VERSION ""

NS_ :

BS_:

BU_: DMU_VEDS VIC Vehicle_Control_Unit
VAL_TABLE_ ThermMngtSysHeatrSts 3 "Not Available" 2 "Error" 1 "Heater On" 0 "Heater Off" ;
VAL_TABLE_ ThermMngtSysHVILSts 3 "Not Available" 2 "Error" 1 "HVIL Open" 0 "HVIL Closed" ;
VAL_TABLE_ ThermMngtSysCooltLvl 3 "Not Available" 2 "Error" 1 "Coolant Level is sufficient" 0 "Coolant Level is not sufficient" ;
VAL_TABLE_ ThermManagSysMode_table 15 "Not Available" 14 "Faulted" 13 "Reserved" 12 "Reserved" 11 "Reserved" 10 "Reserved" 9 "Reserved" 8 "Reserved" 7 "Reserved" 6 "Reserved" 5 "Reserved" 4 "Drying" 3 "Heating" 2 "Cooling" 1 "Circulating" 0 "Off" ;
VAL_TABLE_ HVESS_Total_Accumulated_Charge 1 "100 Ah/bit" 0 "Description for the value '0x0'" ;
VAL_TABLE_ HVESS_Total_Energy_Throughput 1 "100 Watt-hour per bit" 0 "Description for the value '0x0'" ;
VAL_TABLE_ HVESS_State_of_Health 0 "0.4% per bit" ;
VAL_TABLE_ HVBLSRCR 3 "11b = Don't care/take no action" 2 "10b = Reserved" 1 "01b = Connection Requested" 0 "00b = Connection not Requested" ;
VAL_TABLE_ HVBHSRCR 3 "11b = Don't care/take no action" 2 "10b = Reserved" 1 "01b = Connection Requested" 0 "00b = Connection not Requested" ;
VAL_TABLE_ HOC 3 "11b = Don't care/Take no action" 2 "10b = Error" 1 "01b = Consent given" 0 "00b = Consent revoked" ;
VAL_TABLE_ HEICC 3 "11b = Don't care/Take no action" 2 "10b = Reserved" 1 "01b = Enable charging" 0 "00b = Disable charging" ;
VAL_TABLE_ HCBC 3 "11b = Don't care/Take no action" 2 "10b = Reserved" 1 "01b = Cell Balancing requested" 0 "00b = Cell Balancing not req" ;
VAL_TABLE_ HVBPITC 3 "11b = Don't care/Take no action" 2 "10b = Inhibit Passive Iso Test" 1 "01b = Passive Iso Test req" 0 "00b = Passive Iso Test not req" ;
VAL_TABLE_ HVBAITC 3 "11b = Don't care/Take no action" 2 "10b = Inhibit Active Iso Test" 1 "01b = Active Iso Test request" 0 "00b = Active Iso Test not req" ;
VAL_TABLE_ HPDM 3 "11b = Don't care/Take no action" 2 "10b = Execute emergency power-dn" 1 "01b = Execute normal power-down" 0 "00b = Power-down not requested" ;
VAL_TABLE_ HVBCC 3 "11b = Don't care/Take no action" 2 "10b = Emgancy contactor cls req" 1 "01b = Close Contactor" 0 "00b = Open Contactor" ;
VAL_TABLE_ PropB_C0 15 "1111b = Info not available (default)" 11 "1011b = Granted but error" 10 "1010b = Granted" 2 "10b = Denied permanently" 1 "01b = Denied until restart" 0 "00b = Denied due to initialization" ;
VAL_TABLE_ PropB_C1_ErrLvl 7 "111b = Open contactors immediately and lock" 6 "110b = Open contactors immediately" 5 "101b = Open contactors normal" 4 "100b = Open contactors with time limit" 3 "11b = Open contactors with speed limit" 2 "10b = Limp Home with limited power" 1 "01b = Internal information" 0 "00b = System is ok" ;
VAL_TABLE_ PropB_C1_ThermEveStsCellT 3 "11b = info not available (default)" 2 "10b = crit. temp. warn. limit exceeded" 1 "01b = temp. warn. limit exceeded" 0 "00b = temperature ok" ;
VAL_TABLE_ S1_ES_HV_REQ 7 "111b = info not available (default)" 6 "110b = disconnect DC char" 5 "101b = connect für DC char" 4 "100b = prepair for DC char" 3 "11b = connect for AC char" 2 "10b = connect for driving" 1 "01b = emergency disconnect" 0 "00b = disconnect" ;
VAL_TABLE_ PropB_A1_LOCK_ACTIVATED 3 "11b = Not available" 2 "10b = Lock is activated by ESCU" 1 "01b = Lock is activated by HTCU" 0 "00b = Lock is inactive" ;
VAL_TABLE_ PropB_A1_STATE_ES_RELAY 7 "111b = Not available" 6 "110b = Error" 5 "101b = reserved" 4 "100b = Main Relays opening" 3 "11b = Main Relays closed" 2 "10b = All Es-Relays closed" 1 "01b = PreCharge-Relais closed" 0 "00b = All Es-Relays open" ;
VAL_TABLE_ Control_Byte_TP_CM 16 "RTS" 17 "CTS" 19 "EoMA" 20 "ERTS" 21 "ECTS" 22 "EDPO" 23 "EEoMACK" 24 "EAbort" 32 "BAM" 255 "Abort" ;

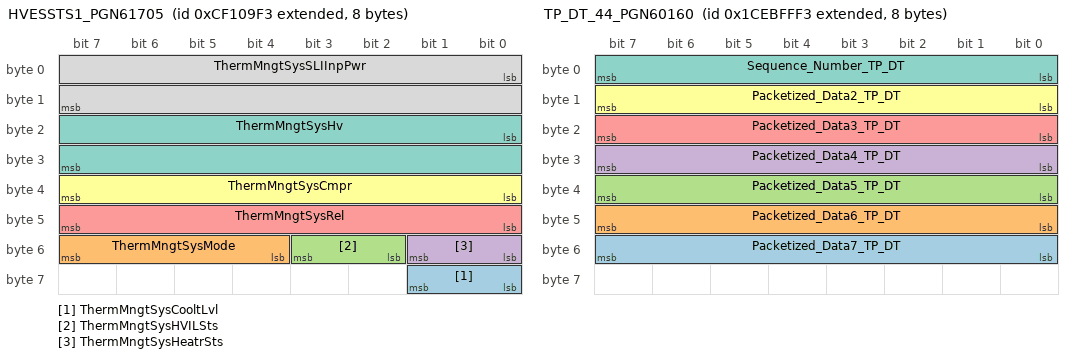
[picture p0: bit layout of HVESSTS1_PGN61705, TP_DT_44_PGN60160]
BO_ 2364606963 HVESSTS1_PGN61705: 8 VIC
 SG_ ThermMngtSysCooltLvl : 56|2@1+ (1,0) [0|3] "bit"  Vehicle_Control_Unit
 SG_ ThermMngtSysMode : 52|4@1+ (1,0) [0|15] "bit"  Vehicle_Control_Unit
 SG_ ThermMngtSysHVILSts : 50|2@1+ (1,0) [0|3] "bit"  Vehicle_Control_Unit
 SG_ ThermMngtSysHeatrSts : 48|2@1+ (1,0) [0|3] "bit"  Vehicle_Control_Unit
 SG_ ThermMngtSysRel : 40|8@1+ (0.4,0) [0|100] "%"  Vehicle_Control_Unit
 SG_ ThermMngtSysCmpr : 32|8@1+ (32,0) [0|8000] "rpm"  Vehicle_Control_Unit
 SG_ ThermMngtSysHv : 16|16@1+ (0.5,0) [0|32127.5] "W"  Vehicle_Control_Unit
 SG_ ThermMngtSysSLIInpPwr : 0|16@1+ (0.5,0) [0|32127.5] "W"  Vehicle_Control_Unit

BO_ 2632712179 TP_DT_44_PGN60160: 8 VIC
 SG_ Packetized_Data7_TP_DT : 48|8@1+ (1,0) [0|255] "" Vector__XXX
 SG_ Packetized_Data6_TP_DT : 40|8@1+ (1,0) [0|255] "" Vector__XXX
 SG_ Packetized_Data5_TP_DT : 32|8@1+ (1,0) [0|255] "" Vector__XXX
 SG_ Packetized_Data4_TP_DT : 24|8@1+ (1,0) [0|255] "" Vector__XXX
 SG_ Packetized_Data3_TP_DT : 16|8@1+ (1,0) [0|255] "" Vector__XXX
 SG_ Packetized_Data2_TP_DT : 8|8@1+ (1,0) [0|255] "" Vector__XXX
 SG_ Sequence_Number_TP_DT : 0|8@1+ (1,0) [0|255] "count" Vector__XXX

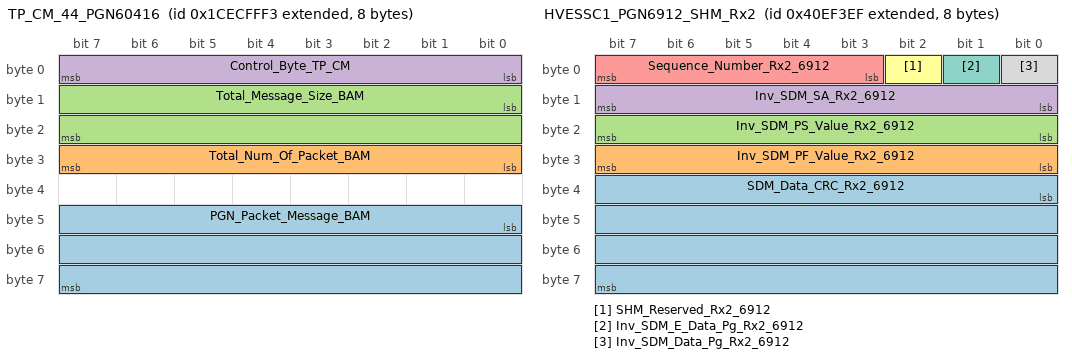
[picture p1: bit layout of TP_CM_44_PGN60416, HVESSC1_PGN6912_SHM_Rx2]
BO_ 2632777715 TP_CM_44_PGN60416: 8 VIC
 SG_ PGN_Packet_Message_BAM : 40|24@1+ (1,0) [0|16777215] "bit" Vector__XXX
 SG_ Total_Num_Of_Packet_BAM : 24|8@1+ (1,0) [0|255] "count" Vector__XXX
 SG_ Total_Message_Size_BAM : 8|16@1+ (1,0) [9|1785] "count" Vector__XXX
 SG_ Control_Byte_TP_CM : 0|8@1+ (1,0) [0|255] "bit" Vector__XXX

BO_ 2215572463 HVESSC1_PGN6912_SHM_Rx2: 8 DMU_VEDS
 SG_ SDM_Data_CRC_Rx2_6912 : 32|32@1+ (1,0) [0|4294967295] "bit"  VIC
 SG_ Inv_SDM_PF_Value_Rx2_6912 : 24|8@1+ (1,0) [0|256] "bit"  VIC
 SG_ Inv_SDM_PS_Value_Rx2_6912 : 16|8@1+ (1,0) [0|256] "bit"  VIC
 SG_ Inv_SDM_SA_Rx2_6912 : 8|8@1+ (1,0) [0|256] "bit"  VIC
 SG_ Sequence_Number_Rx2_6912 : 3|5@1+ (1,0) [0|32] "bit"  VIC
 SG_ SHM_Reserved_Rx2_6912 : 2|1@1+ (1,0) [0|1] "bit"  VIC
 SG_ Inv_SDM_E_Data_Pg_Rx2_6912 : 1|1@1+ (1,0) [0|1] "bit"  VIC
 SG_ Inv_SDM_Data_Pg_Rx2_6912 : 0|1@1+ (1,0) [0|1] "bit"  VIC

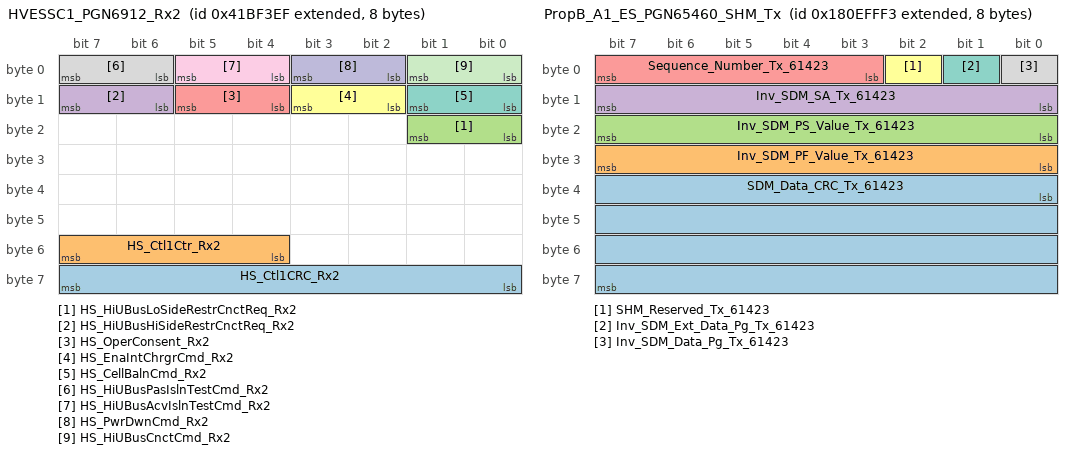
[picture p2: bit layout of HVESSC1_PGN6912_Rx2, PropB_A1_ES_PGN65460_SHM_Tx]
BO_ 2216424431 HVESSC1_PGN6912_Rx2: 8 DMU_VEDS
 SG_ HS_Ctl1CRC_Rx2 : 56|8@1+ (1,0) [0|255] "count"  VIC
 SG_ HS_Ctl1Ctr_Rx2 : 52|4@1+ (1,0) [0|15] "bit"  VIC
 SG_ HS_HiUBusLoSideRestrCnctReq_Rx2 : 16|2@1+ (1,0) [0|3] "bit"  VIC
 SG_ HS_HiUBusHiSideRestrCnctReq_Rx2 : 14|2@1+ (1,0) [0|3] "bit"  VIC
 SG_ HS_OperConsent_Rx2 : 12|2@1+ (1,0) [0|3] "bit"  VIC
 SG_ HS_EnaIntChrgrCmd_Rx2 : 10|2@1+ (1,0) [0|3] "bit"  VIC
 SG_ HS_CellBalnCmd_Rx2 : 8|2@1+ (1,0) [0|3] "bit"  VIC
 SG_ HS_HiUBusPasIslnTestCmd_Rx2 : 6|2@1+ (1,0) [0|3] "bit"  VIC
 SG_ HS_HiUBusAcvIslnTestCmd_Rx2 : 4|2@1+ (1,0) [0|3] "bit"  VIC
 SG_ HS_PwrDwnCmd_Rx2 : 2|2@1+ (1,0) [0|3] "bit"  VIC
 SG_ HS_HiUBusCnctCmd_Rx2 : 0|2@1+ (1,0) [0|3] "bit"  VIC

BO_ 2162881313 RQST_ES_PGN59904_Rx1: 3 Vehicle_Control_Unit
 SG_ RQST_Rx1 : 0|24@1+ (1,0) [0|0] ""  VIC

BO_ 2551119859 PropB_A1_ES_PGN65460_SHM_Tx: 8 VIC
 SG_ SDM_Data_CRC_Tx_61423 : 32|32@1+ (1,0) [0|4294967295] "bit"  DMU_VEDS
 SG_ Inv_SDM_PF_Value_Tx_61423 : 24|8@1+ (1,0) [0|256] "bit"  DMU_VEDS
 SG_ Inv_SDM_PS_Value_Tx_61423 : 16|8@1+ (1,0) [0|256] "bit"  DMU_VEDS
 SG_ Inv_SDM_SA_Tx_61423 : 8|8@1+ (1,0) [0|256] "bit"  DMU_VEDS
 SG_ Sequence_Number_Tx_61423 : 3|5@1+ (1,0) [0|32] "bit"  DMU_VEDS
 SG_ SHM_Reserved_Tx_61423 : 2|1@1+ (1,0) [0|1] "bit"  DMU_VEDS
 SG_ Inv_SDM_Ext_Data_Pg_Tx_61423 : 1|1@1+ (1,0) [0|1] "bit"  DMU_VEDS
 SG_ Inv_SDM_Data_Pg_Tx_61423 : 0|1@1+ (1,0) [0|1] "bit"  DMU_VEDS

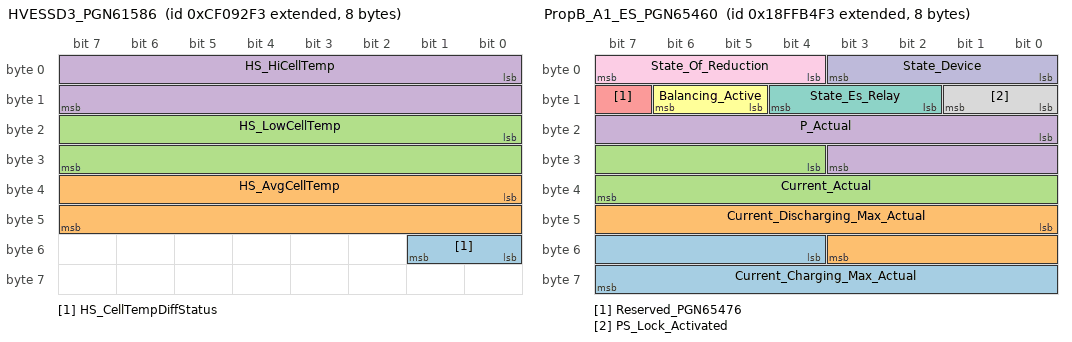
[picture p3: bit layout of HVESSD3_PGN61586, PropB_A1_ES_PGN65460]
BO_ 2364576499 HVESSD3_PGN61586: 8 VIC
 SG_ HS_CellTempDiffStatus : 48|2@1+ (1,0) [0|3] "bit"  Vehicle_Control_Unit
 SG_ HS_AvgCellTemp : 32|16@1+ (0.03125,-273) [-273|1734.96875] "°C"  Vehicle_Control_Unit
 SG_ HS_LowCellTemp : 16|16@1+ (0.03125,-273) [-273|1734.96875] "°C"  Vehicle_Control_Unit
 SG_ HS_HiCellTemp : 0|16@1+ (0.03125,-273) [-273|1734.96875] "°C"  Vehicle_Control_Unit

BO_ 2566894835 PropB_A1_ES_PGN65460: 8 VIC
 SG_ Current_Charging_Max_Actual : 52|12@1+ (1,-2000) [-2000|2015] "A"  DMU_VEDS
 SG_ Current_Discharging_Max_Actual : 40|12@1+ (1,-2000) [-2000|2015] "A"  DMU_VEDS
 SG_ Current_Actual : 28|12@1+ (1,-2000) [-2000|2015] "A"  DMU_VEDS
 SG_ P_Actual : 16|12@1+ (250,-500000) [-500000|503750] "W"  DMU_VEDS
 SG_ Reserved_PGN65476 : 15|1@1+ (1,0) [0|1] "bit"  DMU_VEDS
 SG_ Balancing_Active : 13|2@1+ (1,0) [0|3] "bit"  DMU_VEDS
 SG_ State_Es_Relay : 10|3@1+ (1,0) [0|7] "bit"  DMU_VEDS
 SG_ PS_Lock_Activated : 8|2@1+ (1,0) [0|3] "bit"  DMU_VEDS
 SG_ State_Of_Reduction : 4|4@1+ (1,0) [0|15] ""  DMU_VEDS
 SG_ State_Device : 0|4@1+ (1,0) [0|15] ""  DMU_VEDS

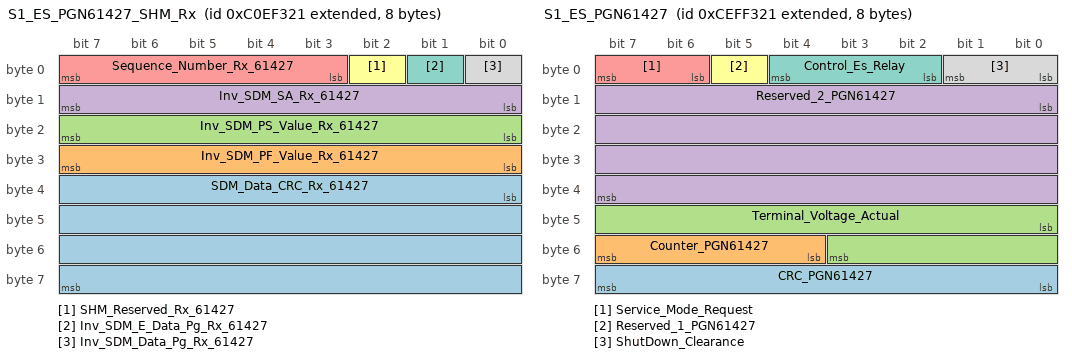
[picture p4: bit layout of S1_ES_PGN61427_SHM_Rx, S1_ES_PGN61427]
BO_ 2349789985 S1_ES_PGN61427_SHM_Rx: 8 Vehicle_Control_Unit
 SG_ SDM_Data_CRC_Rx_61427 : 32|32@1+ (1,0) [0|4294967295] "bit"  VIC
 SG_ Inv_SDM_PF_Value_Rx_61427 : 24|8@1+ (1,0) [0|256] "bit"  VIC
 SG_ Inv_SDM_PS_Value_Rx_61427 : 16|8@1+ (1,0) [0|256] "bit"  VIC
 SG_ Inv_SDM_SA_Rx_61427 : 8|8@1+ (1,0) [0|256] "bit"  VIC
 SG_ Sequence_Number_Rx_61427 : 3|5@1+ (1,0) [0|32] "bit"  VIC
 SG_ SHM_Reserved_Rx_61427 : 2|1@1+ (1,0) [0|1] "bit"  VIC
 SG_ Inv_SDM_E_Data_Pg_Rx_61427 : 1|1@1+ (1,0) [0|1] "bit"  VIC
 SG_ Inv_SDM_Data_Pg_Rx_61427 : 0|1@1+ (1,0) [0|1] "bit"  VIC

BO_ 2364535585 S1_ES_PGN61427: 8 Vehicle_Control_Unit
 SG_ CRC_PGN61427 : 56|8@1+ (1,0) [0|255] "unit"  VIC
 SG_ Counter_PGN61427 : 52|4@1+ (1,0) [0|15] "unit"  VIC
 SG_ Terminal_Voltage_Actual : 40|12@1+ (0.5,0) [0|2007.5] "V"  VIC
 SG_ Reserved_2_PGN61427 : 8|32@1+ (1,0) [0|4294967295] "unit"  VIC
 SG_ Service_Mode_Request : 6|2@1+ (1,0) [0|3] "bit"  VIC
 SG_ Reserved_1_PGN61427 : 5|1@1+ (1,0) [0|1] "unit"  VIC
 SG_ Control_Es_Relay : 2|3@1+ (1,0) [0|7] "bit"  VIC
 SG_ ShutDown_Clearance : 0|2@1+ (1,0) [0|3] "bit"  VIC

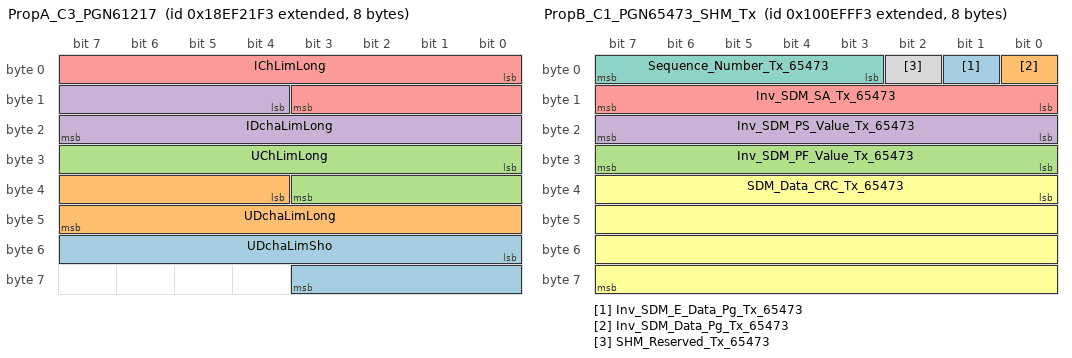
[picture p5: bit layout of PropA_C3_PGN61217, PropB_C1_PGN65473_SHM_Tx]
BO_ 2565808627 PropA_C3_PGN61217: 8 VIC
 SG_ UDchaLimSho : 48|12@1+ (0.25,0) [0|1023.75] "V" Vector__XXX
 SG_ UDchaLimLong : 36|12@1+ (0.25,0) [0|1023.75] "V" Vector__XXX
 SG_ UChLimLong : 24|12@1+ (0.25,0) [0|1023.75] "V" Vector__XXX
 SG_ IDchaLimLong : 12|12@1+ (0.5,0) [0|1023.75] "A" Vector__XXX
 SG_ IChLimLong : 0|12@1+ (0.5,0) [0|1023.75] "A"  Vehicle_Control_Unit

BO_ 2162827763 RQST_ES_PGN59904_Tx: 3 VIC
 SG_ RQST_Tx : 0|24@1+ (1,0) [0|16777215] "unit"  Vehicle_Control_Unit

BO_ 2566834931 DM01_44: 42 VIC
 SG_ Flash_Mil : 14|2@1+ (1,0) [0|3] "" Vector__XXX
 SG_ Flash_Rsl : 12|2@1+ (1,0) [0|3] "" Vector__XXX
 SG_ Flash_Awl : 10|2@1+ (1,0) [0|3] "" Vector__XXX
 SG_ Flash_ProtLamp : 8|2@1+ (1,0) [0|3] "" Vector__XXX
 SG_ ProtLamp : 0|2@1+ (1,0) [0|3] "" Vector__XXX
 SG_ Awl : 2|2@1+ (1,0) [0|3] "" Vector__XXX
 SG_ Rsl : 4|2@1+ (1,0) [0|3] "" Vector__XXX
 SG_ Mil : 6|2@1+ (1,0) [0|3] "" Vector__XXX
 SG_ Spn01 : 16|16@1+ (1,0) [0|65535] "binary" Vector__XXX
 SG_ SpnHigh01 : 37|3@1+ (1,0) [0|7] "binary" Vector__XXX
 SG_ Fmi01 : 32|5@1+ (1,0) [0|31] "binary" Vector__XXX
 SG_ Oc01 : 40|7@1+ (1,0) [0|127] "binary" Vector__XXX
 SG_ SpnCm01 : 47|1@1+ (1,0) [0|1] "" Vector__XXX
 SG_ Spn02 : 48|16@1+ (1,0) [0|65535] "binary" Vector__XXX
 SG_ SpnHigh02 : 69|3@1+ (1,0) [0|7] "binary" Vector__XXX
 SG_ Fmi02 : 64|5@1+ (1,0) [0|31] "binary" Vector__XXX
 SG_ Oc02 : 72|7@1+ (1,0) [0|127] "binary" Vector__XXX
 SG_ SpnCm02 : 79|1@1+ (1,0) [0|1] "" Vector__XXX
 SG_ Spn03 : 80|16@1+ (1,0) [0|65535] "binary" Vector__XXX
 SG_ SpnHigh03 : 101|3@1+ (1,0) [0|7] "binary" Vector__XXX
 SG_ Fmi03 : 96|5@1+ (1,0) [0|31] "binary" Vector__XXX
 SG_ Oc03 : 104|7@1+ (1,0) [0|127] "binary" Vector__XXX
 SG_ SpnCm03 : 111|1@1+ (1,0) [0|1] "" Vector__XXX
 SG_ Spn04 : 112|16@1+ (1,0) [0|65535] "binary" Vector__XXX
 SG_ SpnHigh04 : 133|3@1+ (1,0) [0|7] "binary" Vector__XXX
 SG_ Fmi04 : 128|5@1+ (1,0) [0|31] "binary" Vector__XXX
 SG_ Oc04 : 136|7@1+ (1,0) [0|127] "binary" Vector__XXX
 SG_ SpnCm04 : 143|1@1+ (1,0) [0|1] "" Vector__XXX
 SG_ Spn05 : 144|16@1+ (1,0) [0|65535] "binary" Vector__XXX
 SG_ SpnHigh05 : 165|3@1+ (1,0) [0|7] "binary" Vector__XXX
 SG_ Fmi05 : 160|5@1+ (1,0) [0|31] "binary" Vector__XXX
 SG_ Oc05 : 168|7@1+ (1,0) [0|127] "binary" Vector__XXX
 SG_ SpnCm05 : 175|1@1+ (1,0) [0|1] "" Vector__XXX
 SG_ Spn06 : 176|16@1+ (1,0) [0|65535] "binary" Vector__XXX
 SG_ SpnHigh06 : 197|3@1+ (1,0) [0|7] "binary" Vector__XXX
 SG_ Fmi06 : 192|5@1+ (1,0) [0|31] "binary" Vector__XXX
 SG_ Oc06 : 200|7@1+ (1,0) [0|127] "binary" Vector__XXX
 SG_ SpnCm06 : 207|1@1+ (1,0) [0|1] "" Vector__XXX
 SG_ Spn07 : 208|16@1+ (1,0) [0|65535] "binary" Vector__XXX
 SG_ SpnHigh07 : 229|3@1+ (1,0) [0|7] "binary" Vector__XXX
 SG_ Fmi07 : 224|5@1+ (1,0) [0|31] "binary" Vector__XXX
 SG_ Oc07 : 232|7@1+ (1,0) [0|127] "binary" Vector__XXX
 SG_ SpnCm07 : 239|1@1+ (1,0) [0|1] "" Vector__XXX
 SG_ Spn08 : 240|16@1+ (1,0) [0|65535] "binary" Vector__XXX
 SG_ SpnHigh08 : 261|3@1+ (1,0) [0|7] "binary" Vector__XXX
 SG_ Fmi08 : 256|5@1+ (1,0) [0|31] "binary" Vector__XXX
 SG_ Oc08 : 264|7@1+ (1,0) [0|127] "binary" Vector__XXX
 SG_ SpnCm08 : 271|1@1+ (1,0) [0|1] "" Vector__XXX
 SG_ Spn09 : 272|16@1+ (1,0) [0|65535] "binary" Vector__XXX
 SG_ SpnHigh09 : 293|3@1+ (1,0) [0|7] "binary" Vector__XXX
 SG_ Fmi09 : 288|5@1+ (1,0) [0|31] "binary" Vector__XXX
 SG_ Oc09 : 296|7@1+ (1,0) [0|127] "binary" Vector__XXX
 SG_ SpnCm09 : 303|1@1+ (1,0) [0|1] "" Vector__XXX
 SG_ Spn10 : 304|16@1+ (1,0) [0|65535] "binary" Vector__XXX
 SG_ SpnHigh10 : 325|3@1+ (1,0) [0|7] "binary" Vector__XXX
 SG_ Fmi10 : 320|5@1+ (1,0) [0|31] "binary" Vector__XXX
 SG_ Oc10 : 328|7@1+ (1,0) [0|127] "binary" Vector__XXX
 SG_ SpnCm10 : 335|1@1+ (1,0) [0|1] "" Vector__XXX

BO_ 2416902131 PropB_C1_PGN65473_SHM_Tx: 8 VIC
 SG_ Inv_SDM_E_Data_Pg_Tx_65473 : 1|1@1+ (1,0) [0|1] "bit"  Vehicle_Control_Unit
 SG_ Inv_SDM_Data_Pg_Tx_65473 : 0|1@1+ (1,0) [0|1] "bit"  Vehicle_Control_Unit
 SG_ Inv_SDM_PF_Value_Tx_65473 : 24|8@1+ (1,0) [0|256] "bit"  Vehicle_Control_Unit
 SG_ Inv_SDM_PS_Value_Tx_65473 : 16|8@1+ (1,0) [0|256] "bit"  Vehicle_Control_Unit
 SG_ Inv_SDM_SA_Tx_65473 : 8|8@1+ (1,0) [0|256] "bit"  Vehicle_Control_Unit
 SG_ SDM_Data_CRC_Tx_65473 : 32|32@1+ (1,0) [0|4294967295] "bit"  Vehicle_Control_Unit
 SG_ Sequence_Number_Tx_65473 : 3|5@1+ (1,0) [0|32] "bit"  Vehicle_Control_Unit
 SG_ SHM_Reserved_Tx_65473 : 2|1@1+ (1,0) [0|1] "bit"  Vehicle_Control_Unit

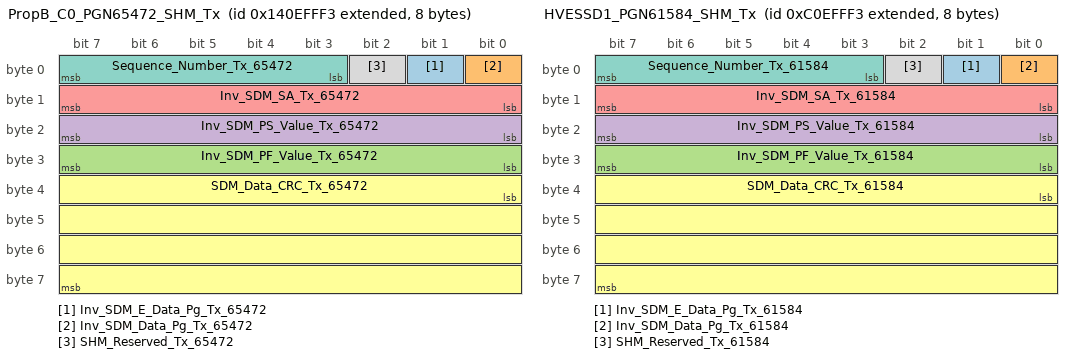
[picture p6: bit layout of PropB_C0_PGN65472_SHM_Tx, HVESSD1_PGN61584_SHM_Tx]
BO_ 2484010995 PropB_C0_PGN65472_SHM_Tx: 8 VIC
 SG_ Inv_SDM_E_Data_Pg_Tx_65472 : 1|1@1+ (1,0) [0|1] "bit"  Vehicle_Control_Unit
 SG_ Inv_SDM_Data_Pg_Tx_65472 : 0|1@1+ (1,0) [0|1] "bit"  Vehicle_Control_Unit
 SG_ Inv_SDM_PF_Value_Tx_65472 : 24|8@1+ (1,0) [0|256] "bit"  Vehicle_Control_Unit
 SG_ Inv_SDM_PS_Value_Tx_65472 : 16|8@1+ (1,0) [0|256] "bit"  Vehicle_Control_Unit
 SG_ Inv_SDM_SA_Tx_65472 : 8|8@1+ (1,0) [0|256] "bit"  Vehicle_Control_Unit
 SG_ SDM_Data_CRC_Tx_65472 : 32|32@1+ (1,0) [0|4294967295] "bit"  Vehicle_Control_Unit
 SG_ Sequence_Number_Tx_65472 : 3|5@1+ (1,0) [0|32] "bit"  Vehicle_Control_Unit
 SG_ SHM_Reserved_Tx_65472 : 2|1@1+ (1,0) [0|1] "bit"  Vehicle_Control_Unit

BO_ 2349793267 HVESSD1_PGN61584_SHM_Tx: 8 VIC
 SG_ Inv_SDM_E_Data_Pg_Tx_61584 : 1|1@1+ (1,0) [0|1] "bit"  Vehicle_Control_Unit
 SG_ Inv_SDM_Data_Pg_Tx_61584 : 0|1@1+ (1,0) [0|1] "bit"  Vehicle_Control_Unit
 SG_ Inv_SDM_PF_Value_Tx_61584 : 24|8@1+ (1,0) [0|256] "bit"  Vehicle_Control_Unit
 SG_ Inv_SDM_PS_Value_Tx_61584 : 16|8@1+ (1,0) [0|256] "bit"  Vehicle_Control_Unit
 SG_ Inv_SDM_SA_Tx_61584 : 8|8@1+ (1,0) [0|256] "bit"  Vehicle_Control_Unit
 SG_ SDM_Data_CRC_Tx_61584 : 32|32@1+ (1,0) [0|4294967295] "bit"  Vehicle_Control_Unit
 SG_ Sequence_Number_Tx_61584 : 3|5@1+ (1,0) [0|32] "bit"  Vehicle_Control_Unit
 SG_ SHM_Reserved_Tx_61584 : 2|1@1+ (1,0) [0|1] "bit"  Vehicle_Control_Unit

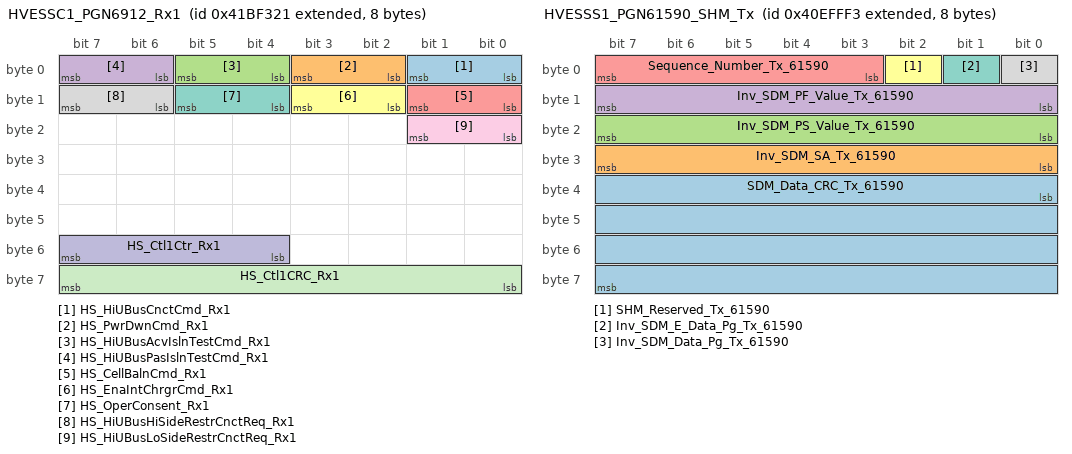
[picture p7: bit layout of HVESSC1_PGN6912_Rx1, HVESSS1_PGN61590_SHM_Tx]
BO_ 2216424225 HVESSC1_PGN6912_Rx1: 8 Vehicle_Control_Unit
 SG_ HS_HiUBusCnctCmd_Rx1 : 0|2@1+ (1,0) [0|3] "bit"  VIC
 SG_ HS_PwrDwnCmd_Rx1 : 2|2@1+ (1,0) [0|3] "bit"  VIC
 SG_ HS_HiUBusAcvIslnTestCmd_Rx1 : 4|2@1+ (1,0) [0|3] "bit"  VIC
 SG_ HS_HiUBusPasIslnTestCmd_Rx1 : 6|2@1+ (1,0) [0|3] "bit"  VIC
 SG_ HS_CellBalnCmd_Rx1 : 8|2@1+ (1,0) [0|3] "bit"  VIC
 SG_ HS_EnaIntChrgrCmd_Rx1 : 10|2@1+ (1,0) [0|3] "bit"  VIC
 SG_ HS_OperConsent_Rx1 : 12|2@1+ (1,0) [0|3] "bit"  VIC
 SG_ HS_HiUBusHiSideRestrCnctReq_Rx1 : 14|2@1+ (1,0) [0|3] "bit"  VIC
 SG_ HS_HiUBusLoSideRestrCnctReq_Rx1 : 16|2@1+ (1,0) [0|3] "bit"  VIC
 SG_ HS_Ctl1Ctr_Rx1 : 52|4@1+ (1,0) [0|15] "bit"  VIC
 SG_ HS_Ctl1CRC_Rx1 : 56|8@1+ (1,0) [0|255] "count"  VIC

BO_ 2215575539 HVESSS1_PGN61590_SHM_Tx: 8 VIC
 SG_ SDM_Data_CRC_Tx_61590 : 32|32@1+ (1,0) [0|4294967295] "bit"  Vehicle_Control_Unit
 SG_ Inv_SDM_SA_Tx_61590 : 24|8@1+ (1,0) [0|256] "bit"  Vehicle_Control_Unit
 SG_ Inv_SDM_PS_Value_Tx_61590 : 16|8@1+ (1,0) [0|256] "bit"  Vehicle_Control_Unit
 SG_ Inv_SDM_PF_Value_Tx_61590 : 8|8@1+ (1,0) [0|256] "bit"  Vehicle_Control_Unit
 SG_ Sequence_Number_Tx_61590 : 3|5@1+ (1,0) [0|32] "bit"  Vehicle_Control_Unit
 SG_ SHM_Reserved_Tx_61590 : 2|1@1+ (1,0) [0|1] "bit"  Vehicle_Control_Unit
 SG_ Inv_SDM_E_Data_Pg_Tx_61590 : 1|1@1+ (1,0) [0|1] "bit"  Vehicle_Control_Unit
 SG_ Inv_SDM_Data_Pg_Tx_61590 : 0|1@1+ (1,0) [0|1] "bit"  Vehicle_Control_Unit

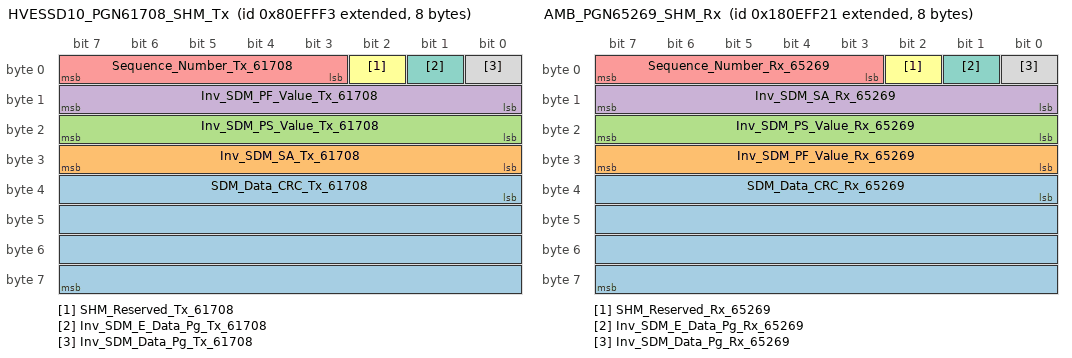
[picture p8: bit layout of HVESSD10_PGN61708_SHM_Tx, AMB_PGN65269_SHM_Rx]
BO_ 2282684403 HVESSD10_PGN61708_SHM_Tx: 8 VIC
 SG_ SDM_Data_CRC_Tx_61708 : 32|32@1+ (1,0) [0|4294967295] "bit"  Vehicle_Control_Unit
 SG_ Inv_SDM_SA_Tx_61708 : 24|8@1+ (1,0) [0|256] "bit"  Vehicle_Control_Unit
 SG_ Inv_SDM_PS_Value_Tx_61708 : 16|8@1+ (1,0) [0|256] "bit"  Vehicle_Control_Unit
 SG_ Inv_SDM_PF_Value_Tx_61708 : 8|8@1+ (1,0) [0|256] "bit"  Vehicle_Control_Unit
 SG_ Sequence_Number_Tx_61708 : 3|5@1+ (1,0) [0|32] "bit"  Vehicle_Control_Unit
 SG_ SHM_Reserved_Tx_61708 : 2|1@1+ (1,0) [0|1] "bit"  Vehicle_Control_Unit
 SG_ Inv_SDM_E_Data_Pg_Tx_61708 : 1|1@1+ (1,0) [0|1] "bit"  Vehicle_Control_Unit
 SG_ Inv_SDM_Data_Pg_Tx_61708 : 0|1@1+ (1,0) [0|1] "bit"  Vehicle_Control_Unit

BO_ 2551119649 AMB_PGN65269_SHM_Rx: 8 Vehicle_Control_Unit
 SG_ SDM_Data_CRC_Rx_65269 : 32|32@1+ (1,0) [0|4294967295] "bit"  VIC
 SG_ Inv_SDM_PF_Value_Rx_65269 : 24|8@1+ (1,0) [0|256] "bit"  VIC
 SG_ Inv_SDM_PS_Value_Rx_65269 : 16|8@1+ (1,0) [0|256] "bit"  VIC
 SG_ Inv_SDM_SA_Rx_65269 : 8|8@1+ (1,0) [0|256] "bit"  VIC
 SG_ Sequence_Number_Rx_65269 : 3|5@1+ (1,0) [0|32] "bit"  VIC
 SG_ SHM_Reserved_Rx_65269 : 2|1@1+ (1,0) [0|1] "bit"  VIC
 SG_ Inv_SDM_E_Data_Pg_Rx_65269 : 1|1@1+ (1,0) [0|1] "bit"  VIC
 SG_ Inv_SDM_Data_Pg_Rx_65269 : 0|1@1+ (1,0) [0|1] "bit"  VIC

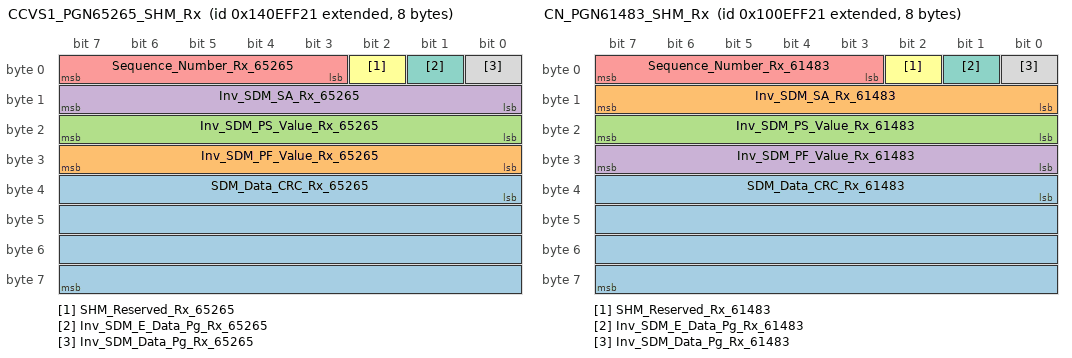
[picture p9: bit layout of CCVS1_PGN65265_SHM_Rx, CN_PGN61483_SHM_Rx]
BO_ 2484010785 CCVS1_PGN65265_SHM_Rx: 8 Vehicle_Control_Unit
 SG_ SDM_Data_CRC_Rx_65265 : 32|32@1+ (1,0) [0|4294967295] "bit"  VIC
 SG_ Inv_SDM_PF_Value_Rx_65265 : 24|8@1+ (1,0) [0|256] "bit"  VIC
 SG_ Inv_SDM_PS_Value_Rx_65265 : 16|8@1+ (1,0) [0|256] "bit"  VIC
 SG_ Inv_SDM_SA_Rx_65265 : 8|8@1+ (1,0) [0|256] "bit"  VIC
 SG_ Sequence_Number_Rx_65265 : 3|5@1+ (1,0) [0|32] "bit"  VIC
 SG_ SHM_Reserved_Rx_65265 : 2|1@1+ (1,0) [0|1] "bit"  VIC
 SG_ Inv_SDM_E_Data_Pg_Rx_65265 : 1|1@1+ (1,0) [0|1] "bit"  VIC
 SG_ Inv_SDM_Data_Pg_Rx_65265 : 0|1@1+ (1,0) [0|1] "bit"  VIC

BO_ 2416901921 CN_PGN61483_SHM_Rx: 8 Vehicle_Control_Unit
 SG_ SDM_Data_CRC_Rx_61483 : 32|32@1+ (1,0) [0|4294967295] "bit"  VIC
 SG_ Inv_SDM_SA_Rx_61483 : 8|8@1+ (1,0) [0|256] "bit"  VIC
 SG_ Inv_SDM_PS_Value_Rx_61483 : 16|8@1+ (1,0) [0|256] "bit"  VIC
 SG_ Inv_SDM_PF_Value_Rx_61483 : 24|8@1+ (1,0) [0|256] "bit"  VIC
 SG_ Sequence_Number_Rx_61483 : 3|5@1+ (1,0) [0|32] "bit"  VIC
 SG_ SHM_Reserved_Rx_61483 : 2|1@1+ (1,0) [0|1] "bit"  VIC
 SG_ Inv_SDM_E_Data_Pg_Rx_61483 : 1|1@1+ (1,0) [0|1] "bit"  VIC
 SG_ Inv_SDM_Data_Pg_Rx_61483 : 0|1@1+ (1,0) [0|1] "bit"  VIC

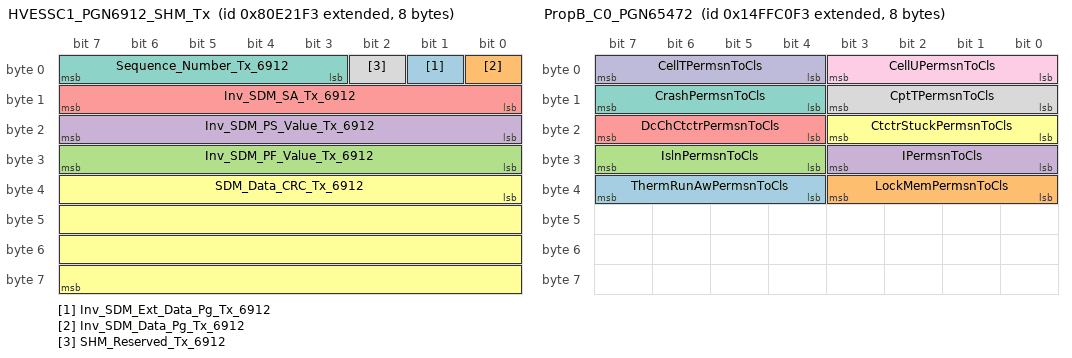
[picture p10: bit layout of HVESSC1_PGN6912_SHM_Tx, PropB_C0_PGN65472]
BO_ 2282627571 HVESSC1_PGN6912_SHM_Tx: 8 VIC
 SG_ Inv_SDM_Ext_Data_Pg_Tx_6912 : 1|1@1+ (1,0) [0|1] "bit"  Vehicle_Control_Unit
 SG_ Inv_SDM_Data_Pg_Tx_6912 : 0|1@1+ (1,0) [0|1] "bit"  Vehicle_Control_Unit
 SG_ Inv_SDM_PF_Value_Tx_6912 : 24|8@1+ (1,0) [0|256] "bit"  Vehicle_Control_Unit
 SG_ Inv_SDM_PS_Value_Tx_6912 : 16|8@1+ (1,0) [0|256] "bit"  Vehicle_Control_Unit
 SG_ Inv_SDM_SA_Tx_6912 : 8|8@1+ (1,0) [0|256] "bit"  Vehicle_Control_Unit
 SG_ SDM_Data_CRC_Tx_6912 : 32|32@1+ (1,0) [0|4294967295] "bit"  Vehicle_Control_Unit
 SG_ Sequence_Number_Tx_6912 : 3|5@1+ (1,0) [0|32] "bit"  Vehicle_Control_Unit
 SG_ SHM_Reserved_Tx_6912 : 2|1@1+ (1,0) [0|1] "bit"  Vehicle_Control_Unit

BO_ 2499789043 PropB_C0_PGN65472: 8 VIC
 SG_ ThermRunAwPermsnToCls : 36|4@1+ (1,0) [0|15] ""  Vehicle_Control_Unit
 SG_ LockMemPermsnToCls : 32|4@1+ (1,0) [0|15] ""  Vehicle_Control_Unit
 SG_ IslnPermsnToCls : 28|4@1+ (1,0) [0|15] ""  Vehicle_Control_Unit
 SG_ IPermsnToCls : 24|4@1+ (1,0) [0|15] ""  Vehicle_Control_Unit
 SG_ DcChCtctrPermsnToCls : 20|4@1+ (1,0) [0|15] ""  Vehicle_Control_Unit
 SG_ CtctrStuckPermsnToCls : 16|4@1+ (1,0) [0|15] ""  Vehicle_Control_Unit
 SG_ CrashPermsnToCls : 12|4@1+ (1,0) [0|15] ""  Vehicle_Control_Unit
 SG_ CptTPermsnToCls : 8|4@1+ (1,0) [0|15] ""  Vehicle_Control_Unit
 SG_ CellUPermsnToCls : 0|4@1+ (1,0) [0|15] ""  Vehicle_Control_Unit
 SG_ CellTPermsnToCls : 4|4@1+ (1,0) [0|15] ""  Vehicle_Control_Unit

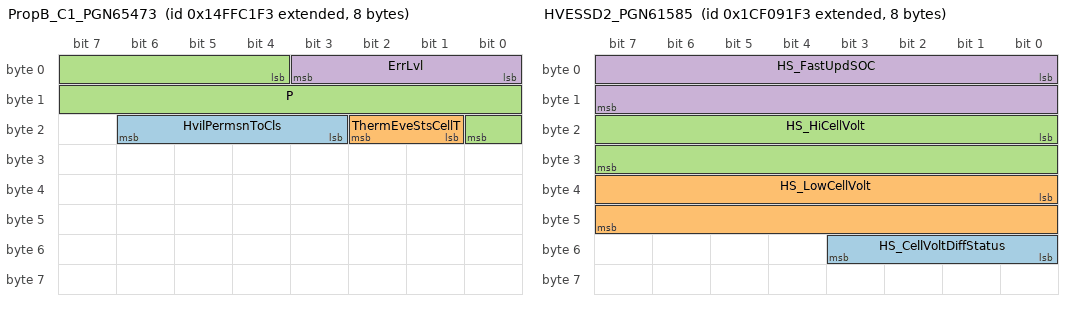
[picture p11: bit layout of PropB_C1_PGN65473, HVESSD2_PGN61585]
BO_ 2499789299 PropB_C1_PGN65473: 8 VIC
 SG_ HvilPermsnToCls : 19|4@1+ (1,0) [0|15] "unit"  Vehicle_Control_Unit
 SG_ ThermEveStsCellT : 17|2@1+ (1,0) [0|3] "unit"  Vehicle_Control_Unit
 SG_ P : 4|13@1+ (0.125,0) [0|1023.875] "kW"  Vehicle_Control_Unit
 SG_ ErrLvl : 0|4@1+ (1,0) [0|7] "unit"  Vehicle_Control_Unit

BO_ 2633011699 HVESSD2_PGN61585: 8 VIC
 SG_ HS_CellVoltDiffStatus : 48|4@1+ (1,0) [0|15] "V"  Vehicle_Control_Unit
 SG_ HS_LowCellVolt : 32|16@1+ (0.001,0) [0|64.255] "V"  Vehicle_Control_Unit
 SG_ HS_HiCellVolt : 16|16@1+ (0.0015625,0) [0|64.255] "V"  Vehicle_Control_Unit
 SG_ HS_FastUpdSOC : 0|16@1+ (0.0015625,0) [0|100.3984375] "%"  Vehicle_Control_Unit

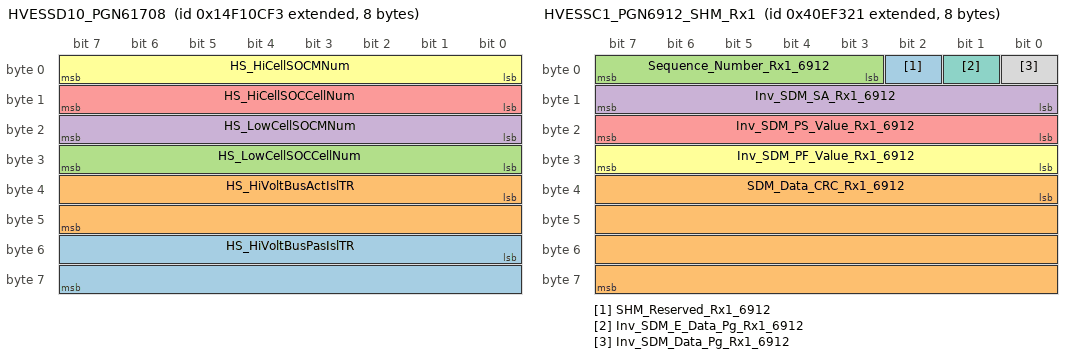
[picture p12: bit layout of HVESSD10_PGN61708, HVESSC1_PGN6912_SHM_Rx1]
BO_ 2498825459 HVESSD10_PGN61708: 8 VIC
 SG_ HS_HiVoltBusPasIslTR : 48|16@1+ (0.1,0) [0|6425.5] "ohm/V"  Vehicle_Control_Unit
 SG_ HS_HiVoltBusActIslTR : 32|16@1+ (0.1,0) [0|6425.5] "ohm/V"  Vehicle_Control_Unit
 SG_ HS_LowCellSOCCellNum : 24|8@1+ (1,0) [0|250] "count"  Vehicle_Control_Unit
 SG_ HS_LowCellSOCMNum : 16|8@1+ (1,0) [0|250] "count"  Vehicle_Control_Unit
 SG_ HS_HiCellSOCCellNum : 8|8@1+ (1,0) [0|250] "count"  Vehicle_Control_Unit
 SG_ HS_HiCellSOCMNum : 0|8@1+ (1,0) [0|250] "count"  Vehicle_Control_Unit

BO_ 2215572257 HVESSC1_PGN6912_SHM_Rx1: 8 Vehicle_Control_Unit
 SG_ SHM_Reserved_Rx1_6912 : 2|1@1+ (1,0) [0|1] "bit"  VIC
 SG_ SDM_Data_CRC_Rx1_6912 : 32|32@1+ (1,0) [0|4294967295] "bit"  VIC
 SG_ Sequence_Number_Rx1_6912 : 3|5@1+ (1,0) [0|32] "bit"  VIC
 SG_ Inv_SDM_SA_Rx1_6912 : 8|8@1+ (1,0) [0|256] "bit"  VIC
 SG_ Inv_SDM_PS_Value_Rx1_6912 : 16|8@1+ (1,0) [0|256] "bit"  VIC
 SG_ Inv_SDM_PF_Value_Rx1_6912 : 24|8@1+ (1,0) [0|256] "bit"  VIC
 SG_ Inv_SDM_E_Data_Pg_Rx1_6912 : 1|1@1+ (1,0) [0|1] "bit"  VIC
 SG_ Inv_SDM_Data_Pg_Rx1_6912 : 0|1@1+ (1,0) [0|1] "bit"  VIC

BO_ 2162881519 RQST_ES_PGN59904_Rx2: 3 DMU_VEDS
 SG_ RQST_Rx2 : 0|24@1+ (1,0) [0|0] ""  VIC

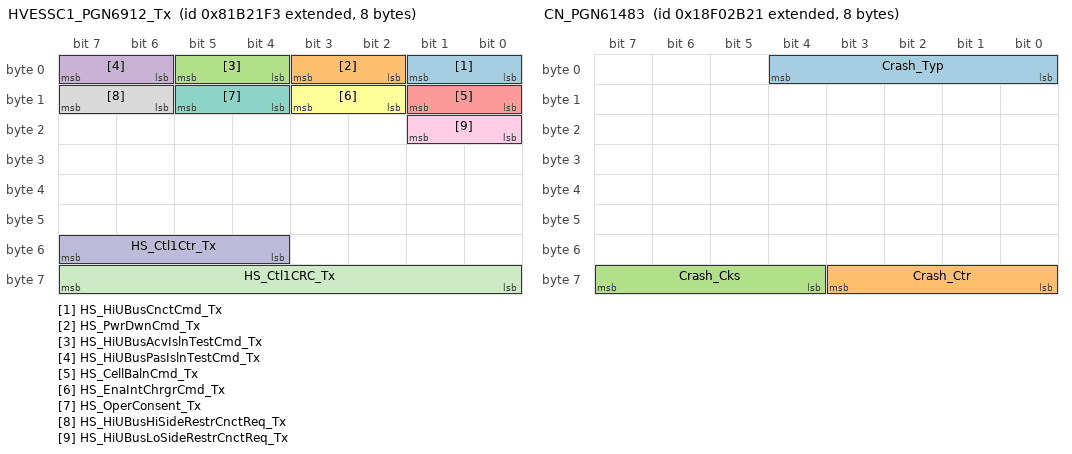
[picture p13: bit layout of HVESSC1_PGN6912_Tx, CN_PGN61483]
BO_ 2283479539 HVESSC1_PGN6912_Tx: 8 VIC
 SG_ HS_HiUBusCnctCmd_Tx : 0|2@1+ (1,0) [0|3] "bit"  Vehicle_Control_Unit
 SG_ HS_PwrDwnCmd_Tx : 2|2@1+ (1,0) [0|3] "bit"  Vehicle_Control_Unit
 SG_ HS_HiUBusAcvIslnTestCmd_Tx : 4|2@1+ (1,0) [0|3] "bit"  Vehicle_Control_Unit
 SG_ HS_HiUBusPasIslnTestCmd_Tx : 6|2@1+ (1,0) [0|3] "bit"  Vehicle_Control_Unit
 SG_ HS_CellBalnCmd_Tx : 8|2@1+ (1,0) [0|3] "bit"  Vehicle_Control_Unit
 SG_ HS_EnaIntChrgrCmd_Tx : 10|2@1+ (1,0) [0|3] "bit"  Vehicle_Control_Unit
 SG_ HS_OperConsent_Tx : 12|2@1+ (1,0) [0|3] "bit"  Vehicle_Control_Unit
 SG_ HS_HiUBusHiSideRestrCnctReq_Tx : 14|2@1+ (1,0) [0|3] "bit"  Vehicle_Control_Unit
 SG_ HS_HiUBusLoSideRestrCnctReq_Tx : 16|2@1+ (1,0) [0|3] "bit"  Vehicle_Control_Unit
 SG_ HS_Ctl1Ctr_Tx : 52|4@1+ (1,0) [0|15] "bit"  Vehicle_Control_Unit
 SG_ HS_Ctl1CRC_Tx : 56|8@1+ (1,0) [0|255] "count"  Vehicle_Control_Unit

BO_ 2565876513 CN_PGN61483: 8 Vehicle_Control_Unit
 SG_ Crash_Typ : 0|5@1+ (1,0) [0|5] "bit-mapped"  VIC
 SG_ Crash_Ctr : 56|4@1+ (1,0) [0|15] "count"  VIC
 SG_ Crash_Cks : 60|4@1+ (1,0) [0|15] "count"  VIC

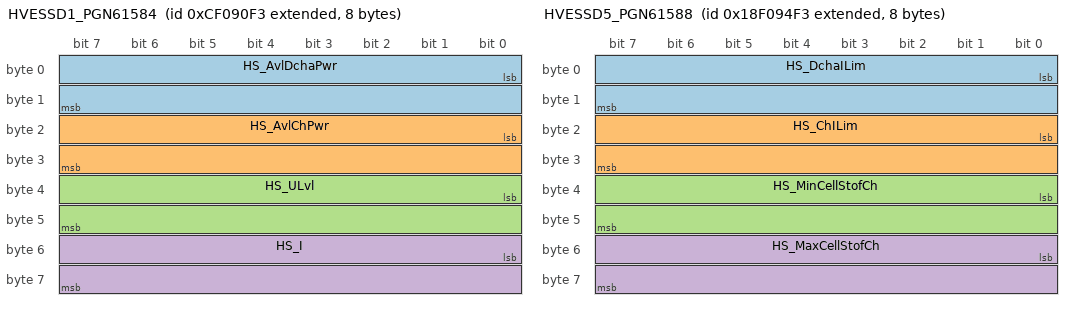
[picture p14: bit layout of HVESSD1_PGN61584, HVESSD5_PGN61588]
BO_ 2364575987 HVESSD1_PGN61584: 8 VIC
 SG_ HS_AvlDchaPwr : 0|16@1+ (0.05,0) [0|3212.75] "kW"  Vehicle_Control_Unit
 SG_ HS_AvlChPwr : 16|16@1+ (0.05,0) [0|3212.75] "kW"  Vehicle_Control_Unit
 SG_ HS_ULvl : 32|16@1+ (0.05,0) [0|3212.75] "V"  Vehicle_Control_Unit
 SG_ HS_I : 48|16@1+ (0.05,-1600) [-1600|1612.75] "A"  Vehicle_Control_Unit

BO_ 2565903603 HVESSD5_PGN61588: 8 VIC
 SG_ HS_DchaILim : 0|16@1+ (0.05,-1600) [-1600|1612.75] "A"  Vehicle_Control_Unit
 SG_ HS_ChILim : 16|16@1+ (0.05,-1600) [-1600|1612.75] "A"  Vehicle_Control_Unit
 SG_ HS_MinCellStofCh : 32|16@1+ (0.0015625,0) [0|100.3984375] "%"  Vehicle_Control_Unit
 SG_ HS_MaxCellStofCh : 48|16@1+ (0.0015625,0) [0|100.3984375] "%"  Vehicle_Control_Unit

BO_ 2498795251 HVESSS1_PGN61590: 8 VIC
 SG_ HS_HiUBusPosCtctrSt : 0|2@1+ (1,0) [0|3] "bit"  Vehicle_Control_Unit
 SG_ HS_HiUBusNegCtctrSt : 2|2@1+ (1,0) [0|3] "bit"  Vehicle_Control_Unit
 SG_ HS_HiUBusDcnctForewarning : 4|4@1+ (1,0) [0|15] "bit"  Vehicle_Control_Unit
 SG_ HS_HiUBusPreChRlySt : 8|2@1+ (1,0) [0|3] "bit"  Vehicle_Control_Unit
 SG_ HS_CentrofPackCtctrSt : 10|2@1+ (1,0) [0|3] "bit"  Vehicle_Control_Unit
 SG_ HS_HiUBusAcvIslnTestSts : 12|4@1+ (1,0) [0|15] "bit"  Vehicle_Control_Unit
 SG_ HS_HiUBusPasIslnTestSts : 16|4@1+ (1,0) [0|15] "bit"  Vehicle_Control_Unit
 SG_ HS_HVILSts : 20|2@1+ (1,0) [0|3] "bit"  Vehicle_Control_Unit
 SG_ HS_JSwtSts : 22|2@1+ (1,0) [0|3] "bit"  Vehicle_Control_Unit
 SG_ HS_StofChSts : 24|4@1+ (1,0) [0|15] "bit"  Vehicle_Control_Unit
 SG_ HS_CellBalSts : 28|2@1+ (1,0) [0|3] "bit"  Vehicle_Control_Unit
 SG_ HS_CellBalnAcv : 30|2@1+ (1,0) [0|3] "bit"  Vehicle_Control_Unit
 SG_ HS_IntChrgrSts : 32|2@1+ (1,0) [0|3] "bit"  Vehicle_Control_Unit
 SG_ HS_Sts1Ctr : 36|4@1+ (1,0) [0|15] "bit"  Vehicle_Control_Unit
 SG_ HS_HiUBusCnctnSts : 40|4@1+ (1,0) [0|15] "bit"  Vehicle_Control_Unit
 SG_ HS_OperationalSts : 44|4@1+ (1,0) [0|15] "bit"  Vehicle_Control_Unit
 SG_ HS_NrofHPsRdy : 48|8@1+ (1,0) [0|250] "count"  Vehicle_Control_Unit
 SG_ HS_Sts1CRC : 56|8@1+ (1,0) [0|255] "count"  Vehicle_Control_Unit

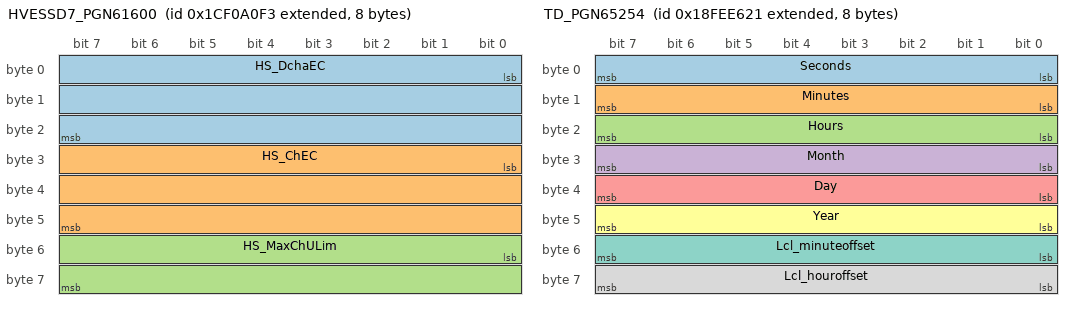
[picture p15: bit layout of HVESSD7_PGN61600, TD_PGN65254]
BO_ 2633015539 HVESSD7_PGN61600: 8 VIC
 SG_ HS_DchaEC : 0|24@1+ (0.001,0) [0|16449.535] "kWh"  Vehicle_Control_Unit
 SG_ HS_ChEC : 24|24@1+ (0.001,0) [0|16449.535] "kWh"  Vehicle_Control_Unit
 SG_ HS_MaxChULim : 48|16@1+ (0.05,0) [0|3212.75] "V"  Vehicle_Control_Unit

BO_ 2566844672 CCVS1_PGN65265: 8 Vehicle_Control_Unit
 SG_ Engine_Shutdwn_Ovride_Swtch : 62|2@1+ (1,0) [0|3] "bit"  VIC
 SG_ Engine_Diag_Test_Mode_Swtch : 60|2@1+ (1,0) [0|3] "bit"  VIC
 SG_ Engine_Idle_Decrement_Switch : 58|2@1+ (1,0) [0|3] "bit"  VIC
 SG_ Engine_Idle_Increment_Switch : 56|2@1+ (1,0) [0|3] "bit"  VIC
 SG_ Cruise_Control_States : 53|3@1+ (1,0) [0|7] "bit"  VIC
 SG_ PTO_Governor_State : 48|5@1+ (1,0) [0|31] "bit"  VIC
 SG_ Cruise_Control_Set_Spd : 40|8@1+ (1,0) [0|250] "km/h"  VIC
 SG_ Cruise_Control_Accelerate_Swtch : 38|2@1+ (1,0) [0|3] "bit"  VIC
 SG_ Cruise_Control_Resume_Swtch : 36|2@1+ (1,0) [0|3] "bit"  VIC
 SG_ Cruise_Control_Coast_Decl_Switch : 34|2@1+ (1,0) [0|3] "bit"  VIC
 SG_ Cruise_Control_SetSwtch : 32|2@1+ (1,0) [0|3] "bit"  VIC
 SG_ Clutch_Switch : 30|2@1+ (1,0) [0|3] "bit"  VIC
 SG_ Brake_Switch : 28|2@1+ (1,0) [0|3] "bit"  VIC
 SG_ Cruise_Control_Enable_Swtch : 26|2@1+ (1,0) [0|3] "bit"  VIC
 SG_ Cruise_Control_Active : 24|2@1+ (1,0) [0|3] "bit"  VIC
 SG_ Wheel_Based_Veh_Spd : 8|16@1+ (0.00390625,0) [0|250.996] "km/h"  VIC
 SG_ Cruise_Control_Pause_Swtch : 4|2@1+ (1,0) [0|3] "bit"  VIC
 SG_ Park_Brake_Rel_Inhibit_Req : 6|2@1+ (1,0) [0|3] "bit"  VIC
 SG_ Parking_Brake_Swtch : 2|2@1+ (1,0) [0|3] "bit"  VIC
 SG_ Two_Spd_Axle_Switch : 0|2@1+ (1,0) [0|3] "bit"  VIC

BO_ 2633785075 HVESSHIST_PGN64606: 19 VIC
 SG_ HS_StofHealth : 0|8@1+ (0.4,0) [0|100] "%"  Vehicle_Control_Unit
 SG_ HS_CtctrOpenUnderLoaCt : 8|16@1+ (1,0) [0|64255] "count"  Vehicle_Control_Unit
 SG_ HS_TotEThroughput : 24|32@1+ (100,0) [0|201326492] "Watt-hour"  Vehicle_Control_Unit
 SG_ HS_TotAccumdCh : 56|32@1+ (100,0) [0|201326492] "Ah"  Vehicle_Control_Unit
 SG_ HS_TotLifetimeEInp : 88|32@1+ (1,0) [0|4211081215] "kWh"  Vehicle_Control_Unit
 SG_ HS_TotLifetimeEOutp : 120|32@1+ (1,0) [0|4211081215] "kWh"  Vehicle_Control_Unit

BO_ 2566841889 TD_PGN65254: 8 Vehicle_Control_Unit
 SG_ Seconds : 0|8@1+ (0.25,0) [0|62.5] "s"  VIC
 SG_ Minutes : 8|8@1+ (1,0) [0|250] "min"  VIC
 SG_ Hours : 16|8@1+ (1,0) [0|250] "h"  VIC
 SG_ Month : 24|8@1+ (1,0) [0|250] "months"  VIC
 SG_ Day : 32|8@1+ (0.25,0) [0|62.5] "days"  VIC
 SG_ Year : 40|8@1+ (1,1985) [1985|2235] "years"  VIC
 SG_ Lcl_minuteoffset : 48|8@1+ (1,-125) [-125|125] "min"  VIC
 SG_ Lcl_houroffset : 56|8@1+ (1,-125) [-125|125] "h"  VIC

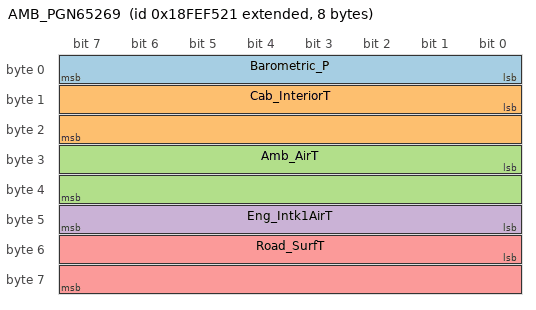
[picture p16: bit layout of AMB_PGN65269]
BO_ 2566845729 AMB_PGN65269: 8 Vehicle_Control_Unit
 SG_ Barometric_P : 0|8@1+ (0.5,0) [0|125] "kPa"  VIC
 SG_ Cab_InteriorT : 8|16@1+ (0.03125,-273) [-273|1734.96875] "°C"  VIC
 SG_ Amb_AirT : 24|16@1+ (0.03125,-273) [-273|1734.96875] "°C"  VIC
 SG_ Eng_Intk1AirT : 40|8@1+ (1,-40) [-40|210] "°C"  VIC
 SG_ Road_SurfT : 48|16@1+ (0.03125,-273) [-273|1734.96875] "°C"  VIC

CM_ BU_ DMU_VEDS "Voith ECU";
CM_ BU_ VIC "VIC";
CM_ BU_ Vehicle_Control_Unit "Vector__XXX";
CM_ BO_ 2364606963 "Collection of data the High Voltage Energy Storage System (or Pack 1 in systems with only one pack) Thermal Management System sends to the Hybrid Controller.
";
CM_ SG_ 2364606963 ThermMngtSysCooltLvl "Indicates the coolant level in the High Voltage Energy Storage System (or Pack 1 in systems with only one pack) Thermal Management System.
00b = Coolant Level is not sufficient
01b = Coolant Level is sufficient
10b = Error
11b = Not Available";
CM_ SG_ 2364606963 ThermMngtSysMode "Indicates the operating mode of the Thermal Management System.The heat transfer medium may be (e.g. liquid or air).  The cooling system may be fans, liquid coolant, or a combination of mediums.";
CM_ SG_ 2364606963 ThermMngtSysHVILSts "Status of the High Voltage Interlock Loop from the viewpoint of the High Voltage Energy Storage System Thermal Management System 1.
00b = HVIL Closed
01b = HVIL Open
10b = Error
11b = Not Available";
CM_ SG_ 2364606963 ThermMngtSysHeatrSts "The state of the High Voltage Energy Storage System (or Pack 1 in systems with only one pack) heater.
00b = Heater Off
01b = Heater On
10b = Error 
11b = Not Available";
CM_ SG_ 2364606963 ThermMngtSysRel "When the High Voltage Energy Storage System (or Pack 1 in systems with only one pack) Thermal Management System is equipped with a relative humidity sensor, this is the  measured Relative Humidity";
CM_ SG_ 2364606963 ThermMngtSysCmpr "When the High Voltage Energy Storage System (or Pack 1 in systems with only one pack) Thermal Management System is equipped with an active cooling system (e.g. air conditioner), this is the Compressor Speed.";
CM_ SG_ 2364606963 ThermMngtSysHv "This is the high-voltage power consumed by this Thermal Management System (TMS). If there is only one pack, or a single TMS for the entire HVES system, then this represents the total high-voltage power consumed.";
CM_ SG_ 2364606963 ThermMngtSysSLIInpPwr "This is the low-voltage power consumed by this Thermal Management System (TMS). If there is only one pack, or a single TMS for the entire HVES system, then this represents the total low-voltage power consumed.";
CM_ BO_ 2632712179 "- J1939/21 Transport Protocol packets, functional content is defined in the message using the protocol";
CM_ BO_ 2632777715 "- J1939/21 Transport Protocol packets, functional content is defined in the message using the protocol";
CM_ BO_ 2215572463 "High Voltage Energy Storage System Control 1";
CM_ SG_ 2215572463 SDM_Data_CRC_Rx2_6912 "When the HVES has an internal charger this parameter will enable it.   External chargers may use the External Energy Source Connection Demand (SPN 7890) and related SPs.

This parameter provides HVES system level information. If there are multiple pack";
CM_ SG_ 2215572463 Inv_SDM_PF_Value_Rx2_6912 "When the HVES has an internal charger this parameter will enable it.   External chargers may use the External Energy Source Connection Demand (SPN 7890) and related SPs.

This parameter provides HVES system level information. If there are multiple pack";
CM_ SG_ 2215572463 Inv_SDM_PS_Value_Rx2_6912 "When the HVES has an internal charger this parameter will enable it.   External chargers may use the External Energy Source Connection Demand (SPN 7890) and related SPs.

This parameter provides HVES system level information. If there are multiple pack";
CM_ SG_ 2215572463 Inv_SDM_SA_Rx2_6912 "When the HVES has an internal charger this parameter will enable it.   External chargers may use the External Energy Source Connection Demand (SPN 7890) and related SPs.

This parameter provides HVES system level information. If there are multiple pack";
CM_ SG_ 2215572463 Sequence_Number_Rx2_6912 "When the HVES has an internal charger this parameter will enable it.   External chargers may use the External Energy Source Connection Demand (SPN 7890) and related SPs.

";
CM_ SG_ 2215572463 SHM_Reserved_Rx2_6912 "When the HVES has an internal charger this parameter will enable it.   External chargers may use the External Energy Source Connection Demand (SPN 7890) and related SPs.

This parameter provides HVES system level information. If there are multiple pack";
CM_ SG_ 2215572463 Inv_SDM_E_Data_Pg_Rx2_6912 "When the HVES has an internal charger this parameter will enable it.   External chargers may use the External Energy Source Connection Demand (SPN 7890) and related SPs.

This parameter provides HVES system level information. If there are multiple pack";
CM_ SG_ 2215572463 Inv_SDM_Data_Pg_Rx2_6912 "When the HVES has an internal charger this parameter will enable it.   External chargers may use the External Energy Source Connection Demand (SPN 7890) and related SPs.

This parameter provides HVES system level information. If there are multiple pack";
CM_ BO_ 2216424431 "High Voltage Energy Storage System Control 1";
CM_ SG_ 2216424431 HS_Ctl1CRC_Rx2 "The CRC is defined as follows:
 • Length: 8 bits
 • Polynomial: x^8+x^5+x^3+x^2+x+1
 • Initial Value: FFh
 • Input Data Reflection: Not reflected
 • Result Data Reflection: Not reflected
 • XOR value: FFh

SAE makes no claim of the functional saf";
CM_ SG_ 2216424431 HS_Ctl1Ctr_Rx2 "The message counter is used to detect situations where the transmitting ECU malfunction repeats the same frame all the time. The receiver of the information may use the counter parameter to detect this situation. The transmitting device will increase the";
CM_ SG_ 2216424431 HS_HiUBusLoSideRestrCnctReq_Rx2 "This parameter is used to request connection of this HVES instance High-Voltage bus low side resistor in order to perform an isolation test.  See also SPN 8433  (HVESS Low-Voltage Bus High Side Resistor Connect Request).

This parameter provides HVES s";
CM_ SG_ 2216424431 HS_HiUBusHiSideRestrCnctReq_Rx2 "This parameter is used to request connection of this HVES instance High-Voltage bus high side resistor in order to perform an isolation test.  See also SPN 8434  (HVESS High-Voltage Bus Low Side Resistor Connect Request).

This parameter provides HVES ";
CM_ SG_ 2216424431 HS_OperConsent_Rx2 "This parameter provides an indication to the High Voltage Energy Storage System (or Pack 1 in systems with only one pack) that an external device is ready for this HVES instance to proceed with normal operation.  In applications which support this parame";
CM_ SG_ 2216424431 HS_EnaIntChrgrCmd_Rx2 "When the HVES has an internal charger this parameter will enable it.   External chargers may use the External Energy Source Connection Demand (SPN 7890) and related SPs.

This parameter provides HVES system level information. If there are multiple pack";
CM_ SG_ 2216424431 HS_CellBalnCmd_Rx2 "Command for the High Voltage Energy Storage System (or Pack 1 in systems with only one pack) to perform cell balancing.

This parameter provides HVES system level information. If there are multiple packs in the system, then both individual pack message";
CM_ SG_ 2216424431 HS_HiUBusPasIslnTestCmd_Rx2 "Command for the High Voltage Energy Storage System (or Pack 1 in systems with only one pack) to perform a passive electrical isolation test on the high voltage bus.

A passive isolation test uses additional circuitry (e.g. a high impedance network) to ";
CM_ SG_ 2216424431 HS_HiUBusAcvIslnTestCmd_Rx2 "Command for the High Voltage Energy Storage System (or Pack 1 in systems with only one pack) to perform an active electrical isolation test on the high voltage bus.

An active isolation test might use a generated signal (e.g. an injected AC signal) and";
CM_ SG_ 2216424431 HS_PwrDwnCmd_Rx2 "Command to shut down the High Voltage Energy Storage System (or Pack 1 in systems with only one pack).  A normal power-down may involve steps that take some period of time (tests, writing of data, etc.).  However, an emergency power-down should shut down";
CM_ SG_ 2216424431 HS_HiUBusCnctCmd_Rx2 "Command to connect the High Voltage Energy Storage System (or Pack 1 in systems with only one pack) to the high-voltage bus.  The emergency contactor closure request may be used in situations where one or more faults in the hybrid powertrain prevent norm";
CM_ BO_ 2162881313 "RQST PGN";
CM_ SG_ 2162881313 RQST_Rx1 "Upon Requset. To be requested every 5 sec , A request should be sent on 59904 PGN  and customer has to support the request handling





";
CM_ BO_ 2551119859 "Custom PGN";
CM_ SG_ 2551119859 Inv_SDM_Data_Pg_Tx_61423 "Custom PGN";
CM_ BO_ 2364576499 "Data set 3 (thermal data) for High Voltage Energy Storage System (or Pack 1 in systems with only one pack).";
CM_ SG_ 2364576499 HS_CellTempDiffStatus "Indicates whether or not the differential between the highest and lowest cell temperatures are within acceptable limits per the High Voltage Energy Storage System (or Pack 1 in systems with only one pack).";
CM_ SG_ 2364576499 HS_AvgCellTemp "The average temperature level of all cells in the High Voltage Energy Storage System (or Pack 1 in systems with only one pack).";
CM_ SG_ 2364576499 HS_LowCellTemp "The lowest temperature level reported by any cell in the High Voltage Energy Storage System (or Pack 1 in systems with only one pack).";
CM_ SG_ 2364576499 HS_HiCellTemp "The highest temperature level reported by any cell in the High Voltage Energy Storage System (or Pack 1 in systems with only one pack).";
CM_ BO_ 2566894835 "Custom PGN";
CM_ SG_ 2566894835 Current_Charging_Max_Actual "Maximum Charging current.";
CM_ SG_ 2566894835 Current_Discharging_Max_Actual "Maximum discharging current.";
CM_ SG_ 2566894835 Current_Actual "Actual value of the energy storage current.";
CM_ SG_ 2566894835 P_Actual "Actual value of the energy storage power.";
CM_ SG_ 2566894835 Reserved_PGN65476 "reserved.";
CM_ SG_ 2566894835 Balancing_Active "Indicates whether the balancing function of the energy storage is active.";
CM_ SG_ 2566894835 State_Es_Relay "State of the energy storage relays.";
CM_ SG_ 2566894835 PS_Lock_Activated "Indicates whether the electrical power supply lock of the ESCU is activated by
the HTCU or by the component itself due to an internal reason.";
CM_ SG_ 2566894835 State_Of_Reduction "Indicates the cause why the component limitation is active.";
CM_ SG_ 2566894835 State_Device "Indicates the current device state.";
CM_ BO_ 2349789985 "HvReq Connect";
CM_ BO_ 2364535585 "Set Point Message_1 – Energy Storage";
CM_ SG_ 2364535585 CRC_PGN61427 "The end-to-end crc is calculated over the first seven bytes of the CAN frame. The end-to-end crc is calculated with the WCDMA-8 (x^8 +x^7 +x^4 +x^3 +x +1)
polynomial.";
CM_ SG_ 2364535585 Counter_PGN61427 "The message counter is incremented by one for each new message. If the message counter exceeds the message counter maximum value, it start again by 0.
If the message counter does not match the expected value, the received data is invalid.";
CM_ SG_ 2364535585 Terminal_Voltage_Actual "Actual value of the terminal voltage, measured before the main contactor.";
CM_ SG_ 2364535585 Reserved_2_PGN61427 "Reserved";
CM_ SG_ 2364535585 Service_Mode_Request "By means of the serviceModeRequest signal the component can be put into to the service mode.
0x0 = Service mode not requested
0x1 = Service mode requested
0x2 = Reserved
0x3 = Not available";
CM_ SG_ 2364535585 Reserved_1_PGN61427 "Reserved";
CM_ SG_ 2364535585 Control_Es_Relay "Control command for the activation/deactivation of the energy storage relays.";
CM_ SG_ 2364535585 ShutDown_Clearance "Signal for prevention of an undesirable shut down of the ESCU during normal
system operation.
0x0 = Component shut down not
granted
0x1 = Component shut down granted
0x2 = Reserved
0x3 = Not available";
CM_ BO_ 2565808627 "Custom PGN";
CM_ SG_ 2565808627 UDchaLimSho "This signal contains the short term voltage limit for discharging the battery system.";
CM_ SG_ 2565808627 UDchaLimLong "This signal contains the long term voltage limit for discharging the battery system.";
CM_ SG_ 2565808627 UChLimLong "This signal contains the long term voltage limit for charging the battery system.";
CM_ SG_ 2565808627 IDchaLimLong "This signal contains the long term current limit for discharging the battery system.";
CM_ SG_ 2565808627 IChLimLong "This signal contains the long term current limit for charging the battery system.";
CM_ SG_ 2162827763 RQST_Tx " To be transmit every 5 sec , A request should be sent on 59904 PGN  and customer has to support the request handling





";
CM_ BO_ 2566834931 "The message is sent cyclic and on change";
CM_ SG_ 2566834931 Flash_Mil "Flash Malfunction Indication Lamp";
CM_ SG_ 2566834931 Flash_Rsl "Flash Red Stop Lamp";
CM_ SG_ 2566834931 Flash_Awl "Flash Amber Warning Lamp";
CM_ SG_ 2566834931 Flash_ProtLamp "Flash Protect Lamp";
CM_ BO_ 2416902131 "Custom PGN";
CM_ SG_ 2416902131 Inv_SDM_E_Data_Pg_Tx_65473 "When the HVES has an internal charger this parameter will enable it.   External chargers may use the External Energy Source Connection Demand (SPN 7890) and related SPs.

This parameter provides HVES system level information. If there are multiple pack";
CM_ SG_ 2416902131 Inv_SDM_Data_Pg_Tx_65473 "When the HVES has an internal charger this parameter will enable it.   External chargers may use the External Energy Source Connection Demand (SPN 7890) and related SPs.

This parameter provides HVES system level information. If there are multiple pack";
CM_ SG_ 2416902131 Inv_SDM_PF_Value_Tx_65473 "When the HVES has an internal charger this parameter will enable it.   External chargers may use the External Energy Source Connection Demand (SPN 7890) and related SPs.

This parameter provides HVES system level information. If there are multiple pack";
CM_ SG_ 2416902131 Inv_SDM_PS_Value_Tx_65473 "When the HVES has an internal charger this parameter will enable it.   External chargers may use the External Energy Source Connection Demand (SPN 7890) and related SPs.

This parameter provides HVES system level information. If there are multiple pack";
CM_ SG_ 2416902131 Inv_SDM_SA_Tx_65473 "When the HVES has an internal charger this parameter will enable it.   External chargers may use the External Energy Source Connection Demand (SPN 7890) and related SPs.

This parameter provides HVES system level information. If there are multiple pack";
CM_ SG_ 2416902131 SDM_Data_CRC_Tx_65473 "When the HVES has an internal charger this parameter will enable it.   External chargers may use the External Energy Source Connection Demand (SPN 7890) and related SPs.

This parameter provides HVES system level information. If there are multiple pack";
CM_ SG_ 2416902131 Sequence_Number_Tx_65473 "When the HVES has an internal charger this parameter will enable it.   External chargers may use the External Energy Source Connection Demand (SPN 7890) and related SPs.

";
CM_ SG_ 2416902131 SHM_Reserved_Tx_65473 "When the HVES has an internal charger this parameter will enable it.   External chargers may use the External Energy Source Connection Demand (SPN 7890) and related SPs.

This parameter provides HVES system level information. If there are multiple pack";
CM_ BO_ 2484010995 "High Voltage Energy Storage System Control 1";
CM_ SG_ 2484010995 Inv_SDM_E_Data_Pg_Tx_65472 "When the HVES has an internal charger this parameter will enable it.   External chargers may use the External Energy Source Connection Demand (SPN 7890) and related SPs.

This parameter provides HVES system level information. If there are multiple pack";
CM_ SG_ 2484010995 Inv_SDM_Data_Pg_Tx_65472 "When the HVES has an internal charger this parameter will enable it.   External chargers may use the External Energy Source Connection Demand (SPN 7890) and related SPs.

This parameter provides HVES system level information. If there are multiple pack";
CM_ SG_ 2484010995 Inv_SDM_PF_Value_Tx_65472 "When the HVES has an internal charger this parameter will enable it.   External chargers may use the External Energy Source Connection Demand (SPN 7890) and related SPs.

This parameter provides HVES system level information. If there are multiple pack";
CM_ SG_ 2484010995 Inv_SDM_PS_Value_Tx_65472 "When the HVES has an internal charger this parameter will enable it.   External chargers may use the External Energy Source Connection Demand (SPN 7890) and related SPs.

This parameter provides HVES system level information. If there are multiple pack";
CM_ SG_ 2484010995 Inv_SDM_SA_Tx_65472 "When the HVES has an internal charger this parameter will enable it.   External chargers may use the External Energy Source Connection Demand (SPN 7890) and related SPs.

This parameter provides HVES system level information. If there are multiple pack";
CM_ SG_ 2484010995 SDM_Data_CRC_Tx_65472 "When the HVES has an internal charger this parameter will enable it.   External chargers may use the External Energy Source Connection Demand (SPN 7890) and related SPs.

This parameter provides HVES system level information. If there are multiple pack";
CM_ SG_ 2484010995 Sequence_Number_Tx_65472 "When the HVES has an internal charger this parameter will enable it.   External chargers may use the External Energy Source Connection Demand (SPN 7890) and related SPs.

";
CM_ SG_ 2484010995 SHM_Reserved_Tx_65472 "When the HVES has an internal charger this parameter will enable it.   External chargers may use the External Energy Source Connection Demand (SPN 7890) and related SPs.

This parameter provides HVES system level information. If there are multiple pack";
CM_ BO_ 2349793267 "High Voltage Energy Storage System Control 1";
CM_ SG_ 2349793267 Inv_SDM_E_Data_Pg_Tx_61584 "When the HVES has an internal charger this parameter will enable it.   External chargers may use the External Energy Source Connection Demand (SPN 7890) and related SPs.

This parameter provides HVES system level information. If there are multiple pack";
CM_ SG_ 2349793267 Inv_SDM_Data_Pg_Tx_61584 "When the HVES has an internal charger this parameter will enable it.   External chargers may use the External Energy Source Connection Demand (SPN 7890) and related SPs.

This parameter provides HVES system level information. If there are multiple pack";
CM_ SG_ 2349793267 Inv_SDM_PF_Value_Tx_61584 "When the HVES has an internal charger this parameter will enable it.   External chargers may use the External Energy Source Connection Demand (SPN 7890) and related SPs.

This parameter provides HVES system level information. If there are multiple pack";
CM_ SG_ 2349793267 Inv_SDM_PS_Value_Tx_61584 "When the HVES has an internal charger this parameter will enable it.   External chargers may use the External Energy Source Connection Demand (SPN 7890) and related SPs.

This parameter provides HVES system level information. If there are multiple pack";
CM_ SG_ 2349793267 Inv_SDM_SA_Tx_61584 "When the HVES has an internal charger this parameter will enable it.   External chargers may use the External Energy Source Connection Demand (SPN 7890) and related SPs.

This parameter provides HVES system level information. If there are multiple pack";
CM_ SG_ 2349793267 SDM_Data_CRC_Tx_61584 "When the HVES has an internal charger this parameter will enable it.   External chargers may use the External Energy Source Connection Demand (SPN 7890) and related SPs.

This parameter provides HVES system level information. If there are multiple pack";
CM_ SG_ 2349793267 Sequence_Number_Tx_61584 "When the HVES has an internal charger this parameter will enable it.   External chargers may use the External Energy Source Connection Demand (SPN 7890) and related SPs.

";
CM_ SG_ 2349793267 SHM_Reserved_Tx_61584 "When the HVES has an internal charger this parameter will enable it.   External chargers may use the External Energy Source Connection Demand (SPN 7890) and related SPs.

This parameter provides HVES system level information. If there are multiple pack";
CM_ BO_ 2216424225 "High Voltage Energy Storage System Control 1";
CM_ SG_ 2216424225 HS_HiUBusCnctCmd_Rx1 "Command to connect the High Voltage Energy Storage System (or Pack 1 in systems with only one pack) to the high-voltage bus.  The emergency contactor closure request may be used in situations where one or more faults in the hybrid powertrain prevent norm";
CM_ SG_ 2216424225 HS_PwrDwnCmd_Rx1 "Command to shut down the High Voltage Energy Storage System (or Pack 1 in systems with only one pack).  A normal power-down may involve steps that take some period of time (tests, writing of data, etc.).  However, an emergency power-down should shut down";
CM_ SG_ 2216424225 HS_HiUBusAcvIslnTestCmd_Rx1 "Command for the High Voltage Energy Storage System (or Pack 1 in systems with only one pack) to perform an active electrical isolation test on the high voltage bus.

An active isolation test might use a generated signal (e.g. an injected AC signal) and";
CM_ SG_ 2216424225 HS_HiUBusPasIslnTestCmd_Rx1 "Command for the High Voltage Energy Storage System (or Pack 1 in systems with only one pack) to perform a passive electrical isolation test on the high voltage bus.

A passive isolation test uses additional circuitry (e.g. a high impedance network) to ";
CM_ SG_ 2216424225 HS_CellBalnCmd_Rx1 "Command for the High Voltage Energy Storage System (or Pack 1 in systems with only one pack) to perform cell balancing.

This parameter provides HVES system level information. If there are multiple packs in the system, then both individual pack message";
CM_ SG_ 2216424225 HS_EnaIntChrgrCmd_Rx1 "When the HVES has an internal charger this parameter will enable it.   External chargers may use the External Energy Source Connection Demand (SPN 7890) and related SPs.

This parameter provides HVES system level information. If there are multiple pack";
CM_ SG_ 2216424225 HS_OperConsent_Rx1 "This parameter provides an indication to the High Voltage Energy Storage System (or Pack 1 in systems with only one pack) that an external device is ready for this HVES instance to proceed with normal operation.  In applications which support this parame";
CM_ SG_ 2216424225 HS_HiUBusHiSideRestrCnctReq_Rx1 "This parameter is used to request connection of this HVES instance High-Voltage bus high side resistor in order to perform an isolation test.  See also SPN 8434  (HVESS High-Voltage Bus Low Side Resistor Connect Request).

This parameter provides HVES ";
CM_ SG_ 2216424225 HS_HiUBusLoSideRestrCnctReq_Rx1 "This parameter is used to request connection of this HVES instance High-Voltage bus low side resistor in order to perform an isolation test.  See also SPN 8433  (HVESS Low-Voltage Bus High Side Resistor Connect Request).

This parameter provides HVES s";
CM_ SG_ 2216424225 HS_Ctl1Ctr_Rx1 "The message counter is used to detect situations where the transmitting ECU malfunction repeats the same frame all the time. The receiver of the information may use the counter parameter to detect this situation. The transmitting device will increase the";
CM_ SG_ 2216424225 HS_Ctl1CRC_Rx1 "The CRC is defined as follows:
 • Length: 8 bits
 • Polynomial: x^8+x^5+x^3+x^2+x+1
 • Initial Value: FFh
 • Input Data Reflection: Not reflected
 • Result Data Reflection: Not reflected
 • XOR value: FFh

SAE makes no claim of the functional saf";
CM_ BO_ 2215575539 "High Voltage Energy Storage System Status 1";
CM_ SG_ 2215575539 SDM_Data_CRC_Tx_61590 "When the HVES has an internal charger this parameter will enable it.   External chargers may use the External Energy Source Connection Demand (SPN 7890) and related SPs.

This parameter provides HVES system level information. If there are multiple pack";
CM_ SG_ 2215575539 Inv_SDM_SA_Tx_61590 "When the HVES has an internal charger this parameter will enable it.   External chargers may use the External Energy Source Connection Demand (SPN 7890) and related SPs.

This parameter provides HVES system level information. If there are multiple pack";
CM_ SG_ 2215575539 Inv_SDM_PS_Value_Tx_61590 "When the HVES has an internal charger this parameter will enable it.   External chargers may use the External Energy Source Connection Demand (SPN 7890) and related SPs.

This parameter provides HVES system level information. If there are multiple pack";
CM_ SG_ 2215575539 Inv_SDM_PF_Value_Tx_61590 "When the HVES has an internal charger this parameter will enable it.   External chargers may use the External Energy Source Connection Demand (SPN 7890) and related SPs.

This parameter provides HVES system level information. If there are multiple pack";
CM_ SG_ 2215575539 Sequence_Number_Tx_61590 "When the HVES has an internal charger this parameter will enable it.   External chargers may use the External Energy Source Connection Demand (SPN 7890) and related SPs.

";
CM_ SG_ 2215575539 SHM_Reserved_Tx_61590 "When the HVES has an internal charger this parameter will enable it.   External chargers may use the External Energy Source Connection Demand (SPN 7890) and related SPs.

This parameter provides HVES system level information. If there are multiple pack";
CM_ SG_ 2215575539 Inv_SDM_E_Data_Pg_Tx_61590 "When the HVES has an internal charger this parameter will enable it.   External chargers may use the External Energy Source Connection Demand (SPN 7890) and related SPs.

This parameter provides HVES system level information. If there are multiple pack";
CM_ SG_ 2215575539 Inv_SDM_Data_Pg_Tx_61590 "When the HVES has an internal charger this parameter will enable it.   External chargers may use the External Energy Source Connection Demand (SPN 7890) and related SPs.

This parameter provides HVES system level information. If there are multiple pack";
CM_ BO_ 2282684403 "Data set 10 (electrical) for High Voltage Energy Storage System (or Pack 1 in systems with only one pack).";
CM_ SG_ 2282684403 SDM_Data_CRC_Tx_61708 "When the HVES has an internal charger this parameter will enable it.   External chargers may use the External Energy Source Connection Demand (SPN 7890) and related SPs.

This parameter provides HVES system level information. If there are multiple pack";
CM_ SG_ 2282684403 Inv_SDM_SA_Tx_61708 "When the HVES has an internal charger this parameter will enable it.   External chargers may use the External Energy Source Connection Demand (SPN 7890) and related SPs.

This parameter provides HVES system level information. If there are multiple pack";
CM_ SG_ 2282684403 Inv_SDM_PS_Value_Tx_61708 "When the HVES has an internal charger this parameter will enable it.   External chargers may use the External Energy Source Connection Demand (SPN 7890) and related SPs.

This parameter provides HVES system level information. If there are multiple pack";
CM_ SG_ 2282684403 Inv_SDM_PF_Value_Tx_61708 "When the HVES has an internal charger this parameter will enable it.   External chargers may use the External Energy Source Connection Demand (SPN 7890) and related SPs.

This parameter provides HVES system level information. If there are multiple pack";
CM_ SG_ 2282684403 Sequence_Number_Tx_61708 "When the HVES has an internal charger this parameter will enable it.   External chargers may use the External Energy Source Connection Demand (SPN 7890) and related SPs.

";
CM_ SG_ 2282684403 SHM_Reserved_Tx_61708 "When the HVES has an internal charger this parameter will enable it.   External chargers may use the External Energy Source Connection Demand (SPN 7890) and related SPs.

This parameter provides HVES system level information. If there are multiple pack";
CM_ SG_ 2282684403 Inv_SDM_E_Data_Pg_Tx_61708 "When the HVES has an internal charger this parameter will enable it.   External chargers may use the External Energy Source Connection Demand (SPN 7890) and related SPs.

This parameter provides HVES system level information. If there are multiple pack";
CM_ SG_ 2282684403 Inv_SDM_Data_Pg_Tx_61708 "When the HVES has an internal charger this parameter will enable it.   External chargers may use the External Energy Source Connection Demand (SPN 7890) and related SPs.

This parameter provides HVES system level information. If there are multiple pack";
CM_ BO_ 2551119649 "Ambient Conditions";
CM_ SG_ 2551119649 SDM_Data_CRC_Rx_65269 "When the HVES has an internal charger this parameter will enable it.   External chargers may use the External Energy Source Connection Demand (SPN 7890) and related SPs.

This parameter provides HVES system level information. If there are multiple pack";
CM_ SG_ 2551119649 Inv_SDM_PF_Value_Rx_65269 "When the HVES has an internal charger this parameter will enable it.   External chargers may use the External Energy Source Connection Demand (SPN 7890) and related SPs.

This parameter provides HVES system level information. If there are multiple pack";
CM_ SG_ 2551119649 Inv_SDM_PS_Value_Rx_65269 "When the HVES has an internal charger this parameter will enable it.   External chargers may use the External Energy Source Connection Demand (SPN 7890) and related SPs.

This parameter provides HVES system level information. If there are multiple pack";
CM_ SG_ 2551119649 Inv_SDM_SA_Rx_65269 "When the HVES has an internal charger this parameter will enable it.   External chargers may use the External Energy Source Connection Demand (SPN 7890) and related SPs.

This parameter provides HVES system level information. If there are multiple pack";
CM_ SG_ 2551119649 Sequence_Number_Rx_65269 "When the HVES has an internal charger this parameter will enable it.   External chargers may use the External Energy Source Connection Demand (SPN 7890) and related SPs.

";
CM_ SG_ 2551119649 SHM_Reserved_Rx_65269 "When the HVES has an internal charger this parameter will enable it.   External chargers may use the External Energy Source Connection Demand (SPN 7890) and related SPs.

This parameter provides HVES system level information. If there are multiple pack";
CM_ SG_ 2551119649 Inv_SDM_E_Data_Pg_Rx_65269 "When the HVES has an internal charger this parameter will enable it.   External chargers may use the External Energy Source Connection Demand (SPN 7890) and related SPs.

This parameter provides HVES system level information. If there are multiple pack";
CM_ SG_ 2551119649 Inv_SDM_Data_Pg_Rx_65269 "When the HVES has an internal charger this parameter will enable it.   External chargers may use the External Energy Source Connection Demand (SPN 7890) and related SPs.

This parameter provides HVES system level information. If there are multiple pack";
CM_ BO_ 2484010785 "Cruise Control/Vehicle Speed 1
";
CM_ SG_ 2484010785 SDM_Data_CRC_Rx_65265 "When the HVES has an internal charger this parameter will enable it.   External chargers may use the External Energy Source Connection Demand (SPN 7890) and related SPs.

This parameter provides HVES system level information. If there are multiple pack";
CM_ SG_ 2484010785 Inv_SDM_PF_Value_Rx_65265 "When the HVES has an internal charger this parameter will enable it.   External chargers may use the External Energy Source Connection Demand (SPN 7890) and related SPs.

This parameter provides HVES system level information. If there are multiple pack";
CM_ SG_ 2484010785 Inv_SDM_PS_Value_Rx_65265 "When the HVES has an internal charger this parameter will enable it.   External chargers may use the External Energy Source Connection Demand (SPN 7890) and related SPs.

This parameter provides HVES system level information. If there are multiple pack";
CM_ SG_ 2484010785 Inv_SDM_SA_Rx_65265 "When the HVES has an internal charger this parameter will enable it.   External chargers may use the External Energy Source Connection Demand (SPN 7890) and related SPs.

This parameter provides HVES system level information. If there are multiple pack";
CM_ SG_ 2484010785 Sequence_Number_Rx_65265 "When the HVES has an internal charger this parameter will enable it.   External chargers may use the External Energy Source Connection Demand (SPN 7890) and related SPs.

";
CM_ SG_ 2484010785 SHM_Reserved_Rx_65265 "When the HVES has an internal charger this parameter will enable it.   External chargers may use the External Energy Source Connection Demand (SPN 7890) and related SPs.

This parameter provides HVES system level information. If there are multiple pack";
CM_ SG_ 2484010785 Inv_SDM_E_Data_Pg_Rx_65265 "When the HVES has an internal charger this parameter will enable it.   External chargers may use the External Energy Source Connection Demand (SPN 7890) and related SPs.

This parameter provides HVES system level information. If there are multiple pack";
CM_ SG_ 2484010785 Inv_SDM_Data_Pg_Rx_65265 "When the HVES has an internal charger this parameter will enable it.   External chargers may use the External Energy Source Connection Demand (SPN 7890) and related SPs.

This parameter provides HVES system level information. If there are multiple pack";
CM_ BO_ 2416901921 "<<Devices developed to the standard published after June 2019 will transmit this message at a rate of 500 ms.  Additionally, these devices will also transmit this message every 20 ms for at least 3 s when a crash is detected.>>
J1939DA";
CM_ SG_ 2416901921 SDM_Data_CRC_Rx_61483 "When the HVES has an internal charger this parameter will enable it.   External chargers may use the External Energy Source Connection Demand (SPN 7890) and related SPs.

This parameter provides HVES system level information. If there are multiple pack";
CM_ SG_ 2416901921 Inv_SDM_SA_Rx_61483 "When the HVES has an internal charger this parameter will enable it.   External chargers may use the External Energy Source Connection Demand (SPN 7890) and related SPs.

This parameter provides HVES system level information. If there are multiple pack";
CM_ SG_ 2416901921 Inv_SDM_PS_Value_Rx_61483 "When the HVES has an internal charger this parameter will enable it.   External chargers may use the External Energy Source Connection Demand (SPN 7890) and related SPs.

This parameter provides HVES system level information. If there are multiple pack";
CM_ SG_ 2416901921 Inv_SDM_PF_Value_Rx_61483 "When the HVES has an internal charger this parameter will enable it.   External chargers may use the External Energy Source Connection Demand (SPN 7890) and related SPs.

This parameter provides HVES system level information. If there are multiple pack";
CM_ SG_ 2416901921 Sequence_Number_Rx_61483 "When the HVES has an internal charger this parameter will enable it.   External chargers may use the External Energy Source Connection Demand (SPN 7890) and related SPs.

";
CM_ SG_ 2416901921 SHM_Reserved_Rx_61483 "When the HVES has an internal charger this parameter will enable it.   External chargers may use the External Energy Source Connection Demand (SPN 7890) and related SPs.

This parameter provides HVES system level information. If there are multiple pack";
CM_ SG_ 2416901921 Inv_SDM_E_Data_Pg_Rx_61483 "When the HVES has an internal charger this parameter will enable it.   External chargers may use the External Energy Source Connection Demand (SPN 7890) and related SPs.

This parameter provides HVES system level information. If there are multiple pack";
CM_ SG_ 2416901921 Inv_SDM_Data_Pg_Rx_61483 "When the HVES has an internal charger this parameter will enable it.   External chargers may use the External Energy Source Connection Demand (SPN 7890) and related SPs.

This parameter provides HVES system level information. If there are multiple pack";
CM_ BO_ 2282627571 "High Voltage Energy Storage System Control 1";
CM_ SG_ 2282627571 Inv_SDM_Ext_Data_Pg_Tx_6912 "When the HVES has an internal charger this parameter will enable it.   External chargers may use the External Energy Source Connection Demand (SPN 7890) and related SPs.

This parameter provides HVES system level information. If there are multiple pack";
CM_ SG_ 2282627571 Inv_SDM_Data_Pg_Tx_6912 "When the HVES has an internal charger this parameter will enable it.   External chargers may use the External Energy Source Connection Demand (SPN 7890) and related SPs.

This parameter provides HVES system level information. If there are multiple pack";
CM_ SG_ 2282627571 Inv_SDM_PF_Value_Tx_6912 "When the HVES has an internal charger this parameter will enable it.   External chargers may use the External Energy Source Connection Demand (SPN 7890) and related SPs.

This parameter provides HVES system level information. If there are multiple pack";
CM_ SG_ 2282627571 Inv_SDM_PS_Value_Tx_6912 "When the HVES has an internal charger this parameter will enable it.   External chargers may use the External Energy Source Connection Demand (SPN 7890) and related SPs.

This parameter provides HVES system level information. If there are multiple pack";
CM_ SG_ 2282627571 Inv_SDM_SA_Tx_6912 "When the HVES has an internal charger this parameter will enable it.   External chargers may use the External Energy Source Connection Demand (SPN 7890) and related SPs.

This parameter provides HVES system level information. If there are multiple pack";
CM_ SG_ 2282627571 SDM_Data_CRC_Tx_6912 "When the HVES has an internal charger this parameter will enable it.   External chargers may use the External Energy Source Connection Demand (SPN 7890) and related SPs.

This parameter provides HVES system level information. If there are multiple pack";
CM_ SG_ 2282627571 Sequence_Number_Tx_6912 "When the HVES has an internal charger this parameter will enable it.   External chargers may use the External Energy Source Connection Demand (SPN 7890) and related SPs.

";
CM_ SG_ 2282627571 SHM_Reserved_Tx_6912 "When the HVES has an internal charger this parameter will enable it.   External chargers may use the External Energy Source Connection Demand (SPN 7890) and related SPs.

This parameter provides HVES system level information. If there are multiple pack";
CM_ BO_ 2633011699 "Data set 2 (electrical data) for High Voltage Energy Storage System (or Pack 1 in systems with only one pack).";
CM_ SG_ 2633011699 HS_CellVoltDiffStatus "Indicates whether or not the differential between the highest and lowest cell voltages are within acceptable limits, according to the High Voltage Energy Storage System";
CM_ SG_ 2633011699 HS_LowCellVolt "The lowest voltage level reported by any cell in the High Voltage Energy Storage System (or Pack 1 in systems with only one pack).";
CM_ SG_ 2633011699 HS_HiCellVolt "IThe highest voltage level reported by any cell in the High Voltage Energy Storage System (or Pack 1 in systems with only one pack).";
CM_ SG_ 2633011699 HS_FastUpdSOC "Indicates the High Voltage Energy Storage System (or Pack 1 in systems with only one pack) state of charge.  0% means no charge remaining, 100% means the system is fully charged in terms of physical limits of the energy storage system.";
CM_ BO_ 2498825459 "Data set 10 (electrical) for High Voltage Energy Storage System (or Pack 1 in systems with only one pack).";
CM_ SG_ 2498825459 HS_HiVoltBusPasIslTR "The isolation resistance expressed in Ohms per Volt that resulted from the High-Voltage Bus Passive Isolation Test";
CM_ SG_ 2498825459 HS_HiVoltBusActIslTR "The isolation resistance expressed in Ohms per Volt that resulted from the High-Voltage Bus Active Isolation Test";
CM_ SG_ 2498825459 HS_LowCellSOCCellNum "Identifies the location of SPN 8084 (HVESS Lowest Cell State of Charge) within SPN 8247 (HVESS Lowest Cell State of Charge Module Number).";
CM_ SG_ 2498825459 HS_LowCellSOCMNum "Identifies the location of the module containing SPN 8084 (HVESS Lowest Cell State of Charge).";
CM_ SG_ 2498825459 HS_HiCellSOCCellNum "Identifies the location of SPN 8085 (HVESS Highest Cell State of Charge) within SPN 8245 (HVESS Highest Cell State of Charge Module Number).";
CM_ SG_ 2498825459 HS_HiCellSOCMNum "Identifies the location of the module containing SPN 8085 (HVESS Highest Cell State of Charge).";
CM_ BO_ 2215572257 "High Voltage Energy Storage System Control 1";
CM_ SG_ 2215572257 SHM_Reserved_Rx1_6912 "When the HVES has an internal charger this parameter will enable it.   External chargers may use the External Energy Source Connection Demand (SPN 7890) and related SPs.

This parameter provides HVES system level information. If there are multiple pack";
CM_ SG_ 2215572257 SDM_Data_CRC_Rx1_6912 "When the HVES has an internal charger this parameter will enable it.   External chargers may use the External Energy Source Connection Demand (SPN 7890) and related SPs.

This parameter provides HVES system level information. If there are multiple pack";
CM_ SG_ 2215572257 Sequence_Number_Rx1_6912 "When the HVES has an internal charger this parameter will enable it.   External chargers may use the External Energy Source Connection Demand (SPN 7890) and related SPs.

";
CM_ SG_ 2215572257 Inv_SDM_SA_Rx1_6912 "When the HVES has an internal charger this parameter will enable it.   External chargers may use the External Energy Source Connection Demand (SPN 7890) and related SPs.

This parameter provides HVES system level information. If there are multiple pack";
CM_ SG_ 2215572257 Inv_SDM_PS_Value_Rx1_6912 "When the HVES has an internal charger this parameter will enable it.   External chargers may use the External Energy Source Connection Demand (SPN 7890) and related SPs.

This parameter provides HVES system level information. If there are multiple pack";
CM_ SG_ 2215572257 Inv_SDM_PF_Value_Rx1_6912 "When the HVES has an internal charger this parameter will enable it.   External chargers may use the External Energy Source Connection Demand (SPN 7890) and related SPs.

This parameter provides HVES system level information. If there are multiple pack";
CM_ SG_ 2215572257 Inv_SDM_E_Data_Pg_Rx1_6912 "When the HVES has an internal charger this parameter will enable it.   External chargers may use the External Energy Source Connection Demand (SPN 7890) and related SPs.

This parameter provides HVES system level information. If there are multiple pack";
CM_ SG_ 2215572257 Inv_SDM_Data_Pg_Rx1_6912 "When the HVES has an internal charger this parameter will enable it.   External chargers may use the External Energy Source Connection Demand (SPN 7890) and related SPs.

This parameter provides HVES system level information. If there are multiple pack";
CM_ SG_ 2162881519 RQST_Rx2 "Upon Requset. To be requested every 5 sec , A request should be sent on 59904 PGN  and customer has to support the request handling





";
CM_ BO_ 2283479539 "High Voltage Energy Storage System Control 1";
CM_ SG_ 2283479539 HS_HiUBusCnctCmd_Tx "Command to connect the High Voltage Energy Storage System (or Pack 1 in systems with only one pack) to the high-voltage bus.  The emergency contactor closure request may be used in situations where one or more faults in the hybrid powertrain prevent norm";
CM_ SG_ 2283479539 HS_PwrDwnCmd_Tx "Command to shut down the High Voltage Energy Storage System (or Pack 1 in systems with only one pack).  A normal power-down may involve steps that take some period of time (tests, writing of data, etc.).  However, an emergency power-down should shut down";
CM_ SG_ 2283479539 HS_HiUBusAcvIslnTestCmd_Tx "Command for the High Voltage Energy Storage System (or Pack 1 in systems with only one pack) to perform an active electrical isolation test on the high voltage bus.

An active isolation test might use a generated signal (e.g. an injected AC signal) and";
CM_ SG_ 2283479539 HS_HiUBusPasIslnTestCmd_Tx "Command for the High Voltage Energy Storage System (or Pack 1 in systems with only one pack) to perform a passive electrical isolation test on the high voltage bus.

A passive isolation test uses additional circuitry (e.g. a high impedance network) to ";
CM_ SG_ 2283479539 HS_CellBalnCmd_Tx "Command for the High Voltage Energy Storage System (or Pack 1 in systems with only one pack) to perform cell balancing.

This parameter provides HVES system level information. If there are multiple packs in the system, then both individual pack message";
CM_ SG_ 2283479539 HS_EnaIntChrgrCmd_Tx "When the HVES has an internal charger this parameter will enable it.   External chargers may use the External Energy Source Connection Demand (SPN 7890) and related SPs.

This parameter provides HVES system level information. If there are multiple pack";
CM_ SG_ 2283479539 HS_OperConsent_Tx "This parameter provides an indication to the High Voltage Energy Storage System (or Pack 1 in systems with only one pack) that an external device is ready for this HVES instance to proceed with normal operation.  In applications which support this parame";
CM_ SG_ 2283479539 HS_HiUBusHiSideRestrCnctReq_Tx "This parameter is used to request connection of this HVES instance High-Voltage bus high side resistor in order to perform an isolation test.  See also SPN 8434  (HVESS High-Voltage Bus Low Side Resistor Connect Request).

This parameter provides HVES ";
CM_ SG_ 2283479539 HS_HiUBusLoSideRestrCnctReq_Tx "This parameter is used to request connection of this HVES instance High-Voltage bus low side resistor in order to perform an isolation test.  See also SPN 8433  (HVESS Low-Voltage Bus High Side Resistor Connect Request).

This parameter provides HVES s";
CM_ SG_ 2283479539 HS_Ctl1Ctr_Tx "The message counter is used to detect situations where the transmitting ECU malfunction repeats the same frame all the time. The receiver of the information may use the counter parameter to detect this situation. The transmitting device will increase the";
CM_ SG_ 2283479539 HS_Ctl1CRC_Tx "The CRC is defined as follows:
 • Length: 8 bits
 • Polynomial: x^8+x^5+x^3+x^2+x+1
 • Initial Value: FFh
 • Input Data Reflection: Not reflected
 • Result Data Reflection: Not reflected
 • XOR value: FFh

SAE makes no claim of the functional saf";
CM_ BO_ 2565876513 "<<Devices developed to the standard published after June 2019 will transmit this message at a rate of 500 ms.  Additionally, these devices will also transmit this message every 20 ms for at least 3 s when a crash is detected.>>
J1939DA";
CM_ SG_ 2565876513 Crash_Typ "Type of crash event. 

00000b = no crash
00001b = frontal crash
00010b = rear crash
00100b = side crash (left)
01000b = side crash (right)
10000b = rollover

It is possible to combine different Crash Types. (e.g. frontal and side crash (left) = ";
CM_ SG_ 2565876513 Crash_Ctr "The Crash Counter prevents other ECUs from reacting to a faulty transmission of the Crash Notification PG and serves as a safety mechanism. The Crash Counter becomes incremented by 1 for every sent message, and wraps around to 0 when the previously trans";
CM_ SG_ 2565876513 Crash_Cks "The Crash Checksum is used to verify the signal path from the airbag ECU to other devices in case of a crash.

The 4 bit checksum is the sum of the high nibble and the low nibble of the sum of the identifier, the first 7 data bytes and the 4 bit messag";
CM_ BO_ 2364575987 "High Voltage Energy Storage System Data 1";
CM_ SG_ 2364575987 HS_AvlDchaPwr "The rate at which the High Voltage Energy Storage System (or Pack 1 in systems with only one pack) can currently provide energy for propulsion or other uses.

This parameter provides HVES system level information. If there are multiple packs in the sys";
CM_ SG_ 2364575987 HS_AvlChPwr "The rate at which the High Voltage Energy Storage System (or Pack 1 in systems with only one pack) can currently receive energy from a regenerative or recharging system.

This parameter provides HVES system level information. If there are multiple pack";
CM_ SG_ 2364575987 HS_ULvl "The voltage level of the High Voltage Energy Storage System (or Pack 1 in systems with only one pack). This parameter should be synchronized with SPN 5920 (HVESS Current) such that a realized power value can be calculated.  If the HVES component physical";
CM_ SG_ 2364575987 HS_I "The current in or out of the High Voltage Energy Storage System (or Pack 1 in systems with only one pack). This parameter should be synchronized with SPN 5919 (HVESS Voltage Level) such that a realized power value can be calculated.  This parameter is de";
CM_ BO_ 2565903603 "High Voltage Energy Storage System Data 5";
CM_ SG_ 2565903603 HS_DchaILim "The maximum permissible current flow out of the High Voltage Energy Storage System (or Pack 1 in systems with only one pack). This parameter is defined from the high voltage energy storage system's point of view.

A negative value represents current fl";
CM_ SG_ 2565903603 HS_ChILim "The maximum permissible current flow into the High Voltage Energy Storage System (or Pack 1 in systems with only one pack). This parameter is defined from the high voltage energy storage system's point of view.

A positive value represents current flow";
CM_ SG_ 2565903603 HS_MinCellStofCh "Indicates the state of charge of the lowest-charged cell in the High Voltage Energy Storage System (or Pack 1 in systems with only one pack).  0% means no charge remaining, 100% means the cell is fully charged.   If a single state of charge value covers ";
CM_ SG_ 2565903603 HS_MaxCellStofCh "Indicates the state of charge of the highest-charged cell in the High Voltage Energy Storage System (or Pack 1 in systems with only one pack).  0% means no charge remaining, 100% means the cell is fully charged.  If a single state of charge value covers ";
CM_ BO_ 2498795251 "High Voltage Energy Storage System Status 1";
CM_ SG_ 2498795251 HS_HiUBusPosCtctrSt "Position of the High Voltage Energy Storage System (or Pack 1 in systems with only one pack) positive side bus contactor.  When this contactor is closed, the positive side of this HVES instance is connected to the positive side of the high-voltage bus.  ";
CM_ SG_ 2498795251 HS_HiUBusNegCtctrSt "Position of the High Voltage Energy Storage System (or Pack 1 in systems with only one pack) negative side bus contactor.  When this contactor is closed, the negative side of this HVES instance is connected to the negative side of the high-voltage bus.  ";
CM_ SG_ 2498795251 HS_HiUBusDcnctForewarning "Indicates that the High Voltage Energy Storage System (or Pack 1 in systems with only one pack) is about to disconnect from the high voltage bus due to unacceptable conditions.

This parameter provides HVES system level information. If there are multip";
CM_ SG_ 2498795251 HS_HiUBusPreChRlySt "Position of the high-voltage bus contactor pre-charge relay.  When this relay is closed, the High Voltage Energy Storage System (or Pack 1 in systems with only one pack) is bringing the high-voltage bus up to its operating level.

This parameter provid";
CM_ SG_ 2498795251 HS_CentrofPackCtctrSt "Position of the center high-voltage contactor.  When this contactor is closed, the positive half of the High Voltage Energy Storage System (or Pack 1 in systems with only one pack) is connected to the negative half.  If a system controls the positive, ne";
CM_ SG_ 2498795251 HS_HiUBusAcvIslnTestSts "Status of the high-voltage bus electrical active isolation test as performed by the High Voltage Energy Storage System (or Pack 1 in systems with only one pack).

This parameter provides HVES system level information. If there are multiple packs in the";
CM_ SG_ 2498795251 HS_HiUBusPasIslnTestSts "Status of the high-voltage bus electrical passive isolation test as performed by the High Voltage Energy Storage System (or Pack 1 in systems with only one pack).

This parameter provides HVES system level information. If there are multiple packs in th";
CM_ SG_ 2498795251 HS_HVILSts "Status of the High Voltage Interlock Loop from the viewpoint of the High Voltage Energy Storage System (or Pack 1 in systems with only one pack).

This parameter provides HVES system level information. If there are multiple packs in the system, then bo";
CM_ SG_ 2498795251 HS_JSwtSts "Switch indicating that an impact has been sensed by the High Voltage Energy Storage System (or Pack 1 in systems with only one pack). The impact indication may require action by another controller, or by this HVES instance itself.  For example, a control";
CM_ SG_ 2498795251 HS_StofChSts "Status of the High Voltage Energy Storage System (or Pack 1 in systems with only one pack) State of Charge (SOC).  Note:  A given HVES controller may not support all of the states.

This parameter provides HVES system level information. If there are mu";
CM_ SG_ 2498795251 HS_CellBalSts "Indicates whether or not the cells in the High Voltage Energy Storage System (or Pack 1 in systems with only one pack) are balanced.

This parameter provides HVES system level information. If there are multiple packs in the system, then both individual";
CM_ SG_ 2498795251 HS_CellBalnAcv "Indicates whether or not the cells in the High Voltage Energy Storage System (or Pack 1 in systems with only one pack) are currently being balanced.

This parameter provides HVES system level information. If there are multiple packs in the system, then";
CM_ SG_ 2498795251 HS_IntChrgrSts "Indicates that the charger in this HVES instance is on.  External chargers may use the External Energy Source Connection Status (SPN 7898) and related SPs.

This parameter provides HVES system level information. If there are multiple packs in the syste";
CM_ SG_ 2498795251 HS_Sts1Ctr "The message counter is used to detect situations where the transmitting ECU malfunction repeats the same frame all the time. The receiver of the information may use the counter parameter to detect this situation. The transmitting device will increase the";
CM_ SG_ 2498795251 HS_HiUBusCnctnSts "This parameter provides high level feedback on the High Voltage Energy Storage System (or Pack 1 in systems with only one pack) high voltage bus connection.  For specific contactor information, see SPN 8091 (HVESS High-Voltage Bus (Positive) Contactor St";
CM_ SG_ 2498795251 HS_OperationalSts "Provides feedback on where the High Voltage Energy Storage System (or Pack 1 in systems with only one pack) is in its operating spectrum, and includes feedback in response to the Operation Consent [i.e. SPN 8412 (HVESS Operation Consent)] and Power Down ";
CM_ SG_ 2498795251 HS_NrofHPsRdy "The number of High Voltage Energy Storage Packs that are currently ready to provide high voltage energy or are actively providing high voltage energy in the HVESS system. This parameter will increment after contactors are closed.";
CM_ SG_ 2498795251 HS_Sts1CRC "The CRC is defined as follows:
 • Length: 8 bits
 • Polynomial: x^8+x^5+x^3+x^2+x+1
 • Initial Value: FFh
 • Input Data Reflection: Not reflected
 • Result Data Reflection: Not reflected
 • XOR value: FFh

SAE makes no claim of the functional saf";
CM_ BO_ 2633015539 "High Voltage Energy Storage System Data 7";
CM_ SG_ 2633015539 HS_DchaEC "The amount of stored electrical energy in High Voltage Energy Storage System (or Pack 1 in systems with only one pack) that is available for use by the hybrid system, i.e. “how full is the tank”.  See SPN 8079 (HVESS Discharge Capacity) for Ampere-hours ";
CM_ SG_ 2633015539 HS_ChEC "The amount of unused electrical energy storage available to be filled by charging High Voltage Energy Storage System (or Pack 1 in systems with only one pack), i.e. “how much empty space is remaining in the tank”.  See SPN 8080 (HVESS Charge Capacity) fo";
CM_ SG_ 2633015539 HS_MaxChULim "The maximum voltage level not to be exceeded while charging the High Voltage Energy Storage System (or Pack 1 in systems with only one pack).  If this parameter is not supported, the maximum charge voltage should be limited to SPN 8117 (HVESS Recommended";
CM_ BO_ 2566844672 "Cruise Control/Vehicle Speed 1
";
CM_ SG_ 2566844672 Engine_Shutdwn_Ovride_Swtch "Switch signal which indicates the position of the engine shutdown override switch. 

00b = Off
01b = On
10b = Error
11b = Not available



";
CM_ SG_ 2566844672 Engine_Diag_Test_Mode_Swtch "Switch signal which indicates the position of the engine diagnostic test mode switch.

00b = Off
01b = On
10b = Error
11b = Not available



";
CM_ SG_ 2566844672 Engine_Idle_Decrement_Switch "Switch signal which indicates the position of the idle decrement switch.

00b = Off
01b = On
10b = Error
11b = Not available


";
CM_ SG_ 2566844672 Engine_Idle_Increment_Switch "Switch signal which indicates the position of the idle increment switch.

00b = Off
01b = On
10b = Error
11b = Not available


";
CM_ SG_ 2566844672 Cruise_Control_States "This parameter is used to indicate the current state, or mode, of operation by the cruise control device.
000b = Off/Disabled
001b = Hold
010b = Accelerate
011b = Decelerate
100b = Resume
101b = Set
110b = Accel Override
111b = Not available


";
CM_ SG_ 2566844672 PTO_Governor_State "This parameter is used to indicate the current state or mode of operation by the power takeoff (PTO) governor.
00000b = Off/Disabled
00001b = Hold
00010b = Remote Hold
00011b = Standby
00100b = Remote Standby
00101b = Set



";
CM_ SG_ 2566844672 Cruise_Control_Set_Spd "Value of set (chosen) velocity of velocity control system. 
If an algorithm that can modify the cruise control set point exists in the system.



";
CM_ SG_ 2566844672 Cruise_Control_Accelerate_Swtch "Switch signal of the cruise control activator which indicates that the activator is in the position accelerate.

00b = Cruise control act not in the pos accel
01b = Cruise control activator in position accelerate
10b = Error
11b = Not available

";
CM_ SG_ 2566844672 Cruise_Control_Resume_Swtch "Switch signal of the cruise control activator which indicates that the activator is in the position resume.

00b = Cruise control act not in the pos resume
01b = Cruise control activator in position resume
10b = Error
11b = Not available
";
CM_ SG_ 2566844672 Cruise_Control_Coast_Decl_Switch "Switch signal of the cruise control activator which indicates that the activator is in the position coast (decelerate).

00b = Cruise control act not in the pos coast
01b = Cruise control activator in position coast
10b = Error
11b = Not available
";
CM_ SG_ 2566844672 Cruise_Control_SetSwtch "Switch signal of the cruise control activator which indicates that the activator is in the position set.

00b = Cruise control activator not in the position set
01b = Cruise control activator in position set
10b = Error
11b = Not available

";
CM_ SG_ 2566844672 Clutch_Switch "Switch signal which indicates that the clutch pedal is being pressed.

00b = Clutch pedal released
01b = Clutch pedal depressed
10b = Error
11b = Not available
";
CM_ SG_ 2566844672 Brake_Switch "Switch signal which indicates that the driver operated brake foot pedal is being pressed.

00b = Brake pedal released
01b = Brake pedal depressed
10b = Error
11b = Not Available
";
CM_ SG_ 2566844672 Cruise_Control_Enable_Swtch "Switch signal which indicates that it is possible to manage the cruise control function.

00b = Cruise control disabled
01b = Cruise control enabled
10b = Error
11b = Not available

";
CM_ SG_ 2566844672 Cruise_Control_Active "Cruise control is switched on.  It is not ensured that the engine is controlled by cruise control. 

00b = Cruise control switched off
01b = Cruise control switched on
10b = Error
11b = Not available

";
CM_ SG_ 2566844672 Wheel_Based_Veh_Spd "Speed of the vehicle as calculated from wheel or tailshaft speed.
";
CM_ SG_ 2566844672 Cruise_Control_Pause_Swtch "Switch signal which indicates the position of the Cruise Control Pause Switch used on Remote Cruise Control applications.

00b = Off
01b = On
10b = Error Indicator
11b = Take No Action

";
CM_ SG_ 2566844672 Park_Brake_Rel_Inhibit_Req "Park Brake Release Inhibit Request signals the desire that an applied park brake remain applied and limit the ability of the vehicle to be moved.

00b = Park Brake Release Inhibit not req
01b = P B R InhtR
10b = SAE reserved
11b = Unavailable";
CM_ SG_ 2566844672 Parking_Brake_Swtch "Switch signal which indicates when the parking brake is set. In general the switch actuated by the operator's park brake control.

00b = Parking brake not set
01b = Parking brake set
10b = Error
11b = Not available
";
CM_ SG_ 2566844672 Two_Spd_Axle_Switch "Switch signal which indicates the current axle range.

00b = Low speed range
01b = High speed range
10b = Error
11b = Not available
";
CM_ BO_ 2633785075 "High Voltage Energy Storage System History";
CM_ SG_ 2633785075 HS_StofHealth "This signal represents the expected remaining 'Life' of the High Voltage Energy Storage System (or Pack 1 in systems with only one pack), in percent.  Battery life is a manufacturer-specific measure of how well the energy storage system is functioning re";
CM_ SG_ 2633785075 HS_CtctrOpenUnderLoaCt "This signal represents the number of times the contactors inside the High Voltage Energy Storage System (or Pack 1 in systems with only one pack) have opened while current is flowing through them.  The current level (that determines if an opening event w";
CM_ SG_ 2633785075 HS_TotEThroughput "The total energy throughput which has flowed through High Voltage Energy Storage System (or Pack 1 in systems with only one pack).  This parameter is the sum of the absolute values of the Energy into and out of this HVES instance.  

This parameter pro";
CM_ SG_ 2633785075 HS_TotAccumdCh "The total accumulated amp hours which have flowed through High Voltage Energy Storage System (or Pack 1 in systems with only one pack).  This parameter is the sum of the absolute values of the Ampere hours into and out of this HVES instance.  

This pa";
CM_ SG_ 2633785075 HS_TotLifetimeEInp "The cumulative energy which has flowed into the High Voltage Energy Storage System over the lifetime of the battery system (or Pack 1 in systems with only one pack). In multipack systems this parameter is the sum of the individual packs (See SPN 13367 (";
CM_ SG_ 2633785075 HS_TotLifetimeEOutp "The cumulative energy which has flowed out of the High Voltage Energy Storage System over the lifetime of the battery system (or Pack 1 in systems with only one pack). In multipack systems this parameter is the sum of the individual packs (See SPN 13368 ";
CM_ BO_ 2566841889 "Time/Date";
CM_ SG_ 2566841889 Seconds "The seconds component of the current time of day.  This should be reported as the seconds component of the current time at UTC (Universal Time Coordinate), a.k.a. GMT; however, it may be reported as the seconds component of the current time at a local ti";
CM_ SG_ 2566841889 Minutes "The minutes component of the current time of day.  This should be reported as the minutes component of the current time at UTC (Universal Time Coordinate), a.k.a. GMT; however, it may be reported as the minutes component of the current time at a local ti";
CM_ SG_ 2566841889 Hours "The hour component of the current time of day.  This should be reported as the hour component of the current time at UTC (Universal Time Coordinate), a.k.a. GMT; however, it may be reported as the hour component of the current time at a local time zone. ";
CM_ SG_ 2566841889 Month "The month component of the current calendar date.  This should be reported as the month component of the current date at UTC (Universal Time Coordinate), a.k.a. GMT; however, it may be reported as the month component of the current date at a local time z";
CM_ SG_ 2566841889 Day "The day component of the current calendar date.  This should be reported as the day component of the current date at UTC (Universal Time Coordinate), a.k.a. GMT; however, it may be reported as the day component of the current date at a local time zone.  ";
CM_ SG_ 2566841889 Year "The year component of the current calendar date.  This should be reported as the year component of the current date at UTC (Universal Time Coordinate), a.k.a. GMT; however, it may be reported as the year component of the current date at a local time zone";
CM_ SG_ 2566841889 Lcl_minuteoffset "The minute component of the offset between the UTC time and date and a local time zone time and date.  This is the number of minutes to add to UTC (Universal Time Coordinate) time and date to convert to the time and date in the local time zone .  The Loc";
CM_ SG_ 2566841889 Lcl_houroffset "The hour component of the offset between the UTC (Universal Time Coordinate) time and date and a local time zone time and date.  This is the number of hours to add to UTC, a.k.a. GMT, time and date to convert to the time and date in the local time zone. ";
CM_ BO_ 2566845729 "Ambient Conditions";
CM_ SG_ 2566845729 Barometric_P "Absolute air pressure of the atmosphere.";
CM_ SG_ 2566845729 Cab_InteriorT "Temperature of air inside the part of the vehicle that encloses the driver and vehicle operating controls.

Note: See also SPN 1691.  SPN 1662 is an additional diagnostic SP associated with cab temperature.";
CM_ SG_ 2566845729 Amb_AirT "Temperature of air surrounding vehicle.";
CM_ SG_ 2566845729 Eng_Intk1AirT "Temperature of air entering vehicle air induction system.";
CM_ SG_ 2566845729 Road_SurfT "Indicated temperature of road surface over which vehicle is operating.";
BA_DEF_ SG_  "SigType" ENUM  "Default","Range","RangeSigned","ASCII","Discrete","Control","ReferencePGN","DTC","StringDelimiter","StringLength","StringLengthControl","MessageCounter","MessageChecksum";
BA_DEF_ SG_  "GenSigEVName" STRING ;
BA_DEF_ SG_  "GenSigILSupport" ENUM  "No","Yes";
BA_DEF_ SG_  "GenSigSendType" ENUM  "Cyclic","OnWrite","OnWriteWithRepetition","OnChange","OnChangeWithRepetition","IfActive","IfActiveWithRepetition","NoSigSendType";
BA_DEF_ SG_  "GenSigStartValue" INT 0 2147483647;
BA_DEF_ BO_  "GenMsgILSupport" ENUM  "No","Yes";
BA_DEF_ BO_  "GenMsgStartDelayTime" INT 0 100000;
BA_DEF_ BU_  "NmStationAddress" INT 0 255;
BA_DEF_ BO_  "GenMsgSendType" ENUM  "cyclic","NotUsed","IfActive","NotUsed","NotUsed","NotUsed","NotUsed","NotUsed","noMsgSendType";
BA_DEF_ BO_  "GenMsgRequestable" INT 0 1;
BA_DEF_ BO_  "GenMsgCycleTime" INT 0 3600000;
BA_DEF_ SG_  "SPN" INT 0 524287;
BA_DEF_  "DBName" STRING ;
BA_DEF_  "BusType" STRING ;
BA_DEF_  "ProtocolType" STRING ;
BA_DEF_ BO_  "VFrameFormat" ENUM  "StandardCAN","ExtendedCAN","reserved","J1939PG";
BA_DEF_DEF_  "SigType" "Default";
BA_DEF_DEF_  "GenSigEVName" "Env@Nodename_@Signame";
BA_DEF_DEF_  "GenSigILSupport" "Yes";
BA_DEF_DEF_  "GenSigSendType" "NoSigSendType";
BA_DEF_DEF_  "GenSigStartValue" 0;
BA_DEF_DEF_  "GenMsgILSupport" "Yes";
BA_DEF_DEF_  "GenMsgStartDelayTime" 0;
BA_DEF_DEF_  "NmStationAddress" 254;
BA_DEF_DEF_  "GenMsgSendType" "noMsgSendType";
BA_DEF_DEF_  "GenMsgRequestable" 1;
BA_DEF_DEF_  "GenMsgCycleTime" 0;
BA_DEF_DEF_  "SPN" 0;
BA_DEF_DEF_  "DBName" "";
BA_DEF_DEF_  "BusType" "CAN";
BA_DEF_DEF_  "ProtocolType" "J1939";
BA_DEF_DEF_  "VFrameFormat" "J1939PG";
BA_ "ProtocolType" "*";
BA_ "DBName" "J1939_gen";
BA_ "NmStationAddress" BU_ DMU_VEDS 239;
BA_ "NmStationAddress" BU_ VIC 243;
BA_ "NmStationAddress" BU_ Vehicle_Control_Unit 33;
BA_ "GenMsgSendType" BO_ 2364606963 0;
BA_ "GenMsgCycleTime" BO_ 2364606963 100;
BA_ "GenMsgStartDelayTime" BO_ 2215572463 4;
BA_ "GenMsgSendType" BO_ 2215572463 0;
BA_ "GenMsgCycleTime" BO_ 2215572463 20;
BA_ "GenMsgSendType" BO_ 2216424431 0;
BA_ "GenMsgCycleTime" BO_ 2216424431 20;
BA_ "GenMsgCycleTime" BO_ 2551119859 20;
BA_ "GenMsgSendType" BO_ 2551119859 0;
BA_ "GenMsgSendType" BO_ 2364576499 0;
BA_ "GenMsgCycleTime" BO_ 2364576499 20;
BA_ "GenMsgSendType" BO_ 2566894835 0;
BA_ "GenMsgCycleTime" BO_ 2566894835 20;
BA_ "GenMsgCycleTime" BO_ 2349789985 20;
BA_ "GenMsgSendType" BO_ 2349789985 0;
BA_ "GenMsgCycleTime" BO_ 2364535585 20;
BA_ "GenMsgSendType" BO_ 2364535585 0;
BA_ "GenMsgCycleTime" BO_ 2565808627 20;
BA_ "GenMsgSendType" BO_ 2565808627 0;
BA_ "GenMsgSendType" BO_ 2162827763 0;
BA_ "GenMsgCycleTime" BO_ 2162827763 1000;
BA_ "GenMsgSendType" BO_ 2416902131 0;
BA_ "GenMsgCycleTime" BO_ 2416902131 100;
BA_ "GenMsgSendType" BO_ 2484010995 0;
BA_ "GenMsgCycleTime" BO_ 2484010995 100;
BA_ "GenMsgSendType" BO_ 2349793267 0;
BA_ "GenMsgCycleTime" BO_ 2349793267 20;
BA_ "GenMsgSendType" BO_ 2216424225 0;
BA_ "GenMsgCycleTime" BO_ 2216424225 20;
BA_ "GenMsgSendType" BO_ 2215575539 0;
BA_ "GenMsgCycleTime" BO_ 2215575539 100;
BA_ "GenMsgSendType" BO_ 2282684403 0;
BA_ "GenMsgCycleTime" BO_ 2282684403 100;
BA_ "GenMsgStartDelayTime" BO_ 2551119649 200;
BA_ "GenMsgSendType" BO_ 2551119649 0;
BA_ "GenMsgCycleTime" BO_ 2551119649 1000;
BA_ "GenMsgStartDelayTime" BO_ 2484010785 20;
BA_ "GenMsgSendType" BO_ 2484010785 0;
BA_ "GenMsgCycleTime" BO_ 2484010785 100;
BA_ "GenMsgStartDelayTime" BO_ 2416901921 4;
BA_ "GenMsgSendType" BO_ 2416901921 0;
BA_ "GenMsgCycleTime" BO_ 2416901921 20;
BA_ "GenMsgSendType" BO_ 2282627571 0;
BA_ "GenMsgCycleTime" BO_ 2282627571 20;
BA_ "GenMsgSendType" BO_ 2499789043 0;
BA_ "GenMsgCycleTime" BO_ 2499789043 100;
BA_ "GenMsgSendType" BO_ 2499789299 0;
BA_ "GenMsgCycleTime" BO_ 2499789299 100;
BA_ "GenMsgSendType" BO_ 2633011699 0;
BA_ "GenMsgCycleTime" BO_ 2633011699 20;
BA_ "GenMsgSendType" BO_ 2498825459 0;
BA_ "GenMsgCycleTime" BO_ 2498825459 100;
BA_ "GenMsgStartDelayTime" BO_ 2215572257 4;
BA_ "GenMsgSendType" BO_ 2215572257 0;
BA_ "GenMsgCycleTime" BO_ 2215572257 20;
BA_ "GenMsgSendType" BO_ 2283479539 0;
BA_ "GenMsgCycleTime" BO_ 2283479539 20;
BA_ "GenMsgSendType" BO_ 2565876513 0;
BA_ "GenMsgCycleTime" BO_ 2565876513 20;
BA_ "GenMsgSendType" BO_ 2364575987 0;
BA_ "GenMsgCycleTime" BO_ 2364575987 20;
BA_ "GenMsgSendType" BO_ 2565903603 0;
BA_ "GenMsgCycleTime" BO_ 2565903603 20;
BA_ "GenMsgSendType" BO_ 2498795251 0;
BA_ "GenMsgCycleTime" BO_ 2498795251 100;
BA_ "GenMsgSendType" BO_ 2633015539 0;
BA_ "GenMsgCycleTime" BO_ 2633015539 100;
BA_ "GenMsgSendType" BO_ 2566844672 0;
BA_ "GenMsgCycleTime" BO_ 2566844672 100;
BA_ "GenMsgSendType" BO_ 2566845729 0;
BA_ "GenMsgCycleTime" BO_ 2566845729 1000;
BA_ "SPN" SG_ 2364606963 ThermMngtSysCooltLvl 12897;
BA_ "SPN" SG_ 2364606963 ThermMngtSysMode 8235;
BA_ "SPN" SG_ 2364606963 ThermMngtSysHVILSts 12813;
BA_ "SPN" SG_ 2364606963 ThermMngtSysHeatrSts 8234;
BA_ "SPN" SG_ 2364606963 ThermMngtSysRel 8233;
BA_ "SPN" SG_ 2364606963 ThermMngtSysCmpr 8232;
BA_ "SPN" SG_ 2364606963 ThermMngtSysHv 8231;
BA_ "SPN" SG_ 2364606963 ThermMngtSysSLIInpPwr 8230;
BA_ "SigType" SG_ 2632712179 Packetized_Data7_TP_DT 6;
BA_ "SigType" SG_ 2632712179 Packetized_Data6_TP_DT 6;
BA_ "SigType" SG_ 2632712179 Packetized_Data5_TP_DT 6;
BA_ "SigType" SG_ 2632712179 Packetized_Data4_TP_DT 6;
BA_ "SigType" SG_ 2632712179 Packetized_Data3_TP_DT 6;
BA_ "SigType" SG_ 2632712179 Packetized_Data2_TP_DT 6;
BA_ "SPN" SG_ 2632712179 Sequence_Number_TP_DT 2572;
BA_ "SigType" SG_ 2632712179 Sequence_Number_TP_DT 6;
BA_ "SPN" SG_ 2632777715 PGN_Packet_Message_BAM 2569;
BA_ "SigType" SG_ 2632777715 PGN_Packet_Message_BAM 6;
BA_ "SPN" SG_ 2632777715 Total_Num_Of_Packet_BAM 2568;
BA_ "SigType" SG_ 2632777715 Total_Num_Of_Packet_BAM 6;
BA_ "GenSigStartValue" SG_ 2632777715 Total_Message_Size_BAM 9;
BA_ "SPN" SG_ 2632777715 Total_Message_Size_BAM 2567;
BA_ "SigType" SG_ 2632777715 Total_Message_Size_BAM 6;
BA_ "SPN" SG_ 2632777715 Control_Byte_TP_CM 2556;
BA_ "SigType" SG_ 2632777715 Control_Byte_TP_CM 6;
BA_ "SigType" SG_ 2215572463 SDM_Data_CRC_Rx2_6912 6;
BA_ "SPN" SG_ 2215572463 SDM_Data_CRC_Rx2_6912 9383;
BA_ "SigType" SG_ 2215572463 Inv_SDM_PF_Value_Rx2_6912 6;
BA_ "SPN" SG_ 2215572463 Inv_SDM_PF_Value_Rx2_6912 9386;
BA_ "SigType" SG_ 2215572463 Inv_SDM_PS_Value_Rx2_6912 6;
BA_ "SPN" SG_ 2215572463 Inv_SDM_PS_Value_Rx2_6912 9385;
BA_ "SigType" SG_ 2215572463 Inv_SDM_SA_Rx2_6912 6;
BA_ "SPN" SG_ 2215572463 Inv_SDM_SA_Rx2_6912 9384;
BA_ "SigType" SG_ 2215572463 Sequence_Number_Rx2_6912 6;
BA_ "SPN" SG_ 2215572463 Sequence_Number_Rx2_6912 9382;
BA_ "SigType" SG_ 2215572463 SHM_Reserved_Rx2_6912 6;
BA_ "SPN" SG_ 2215572463 SHM_Reserved_Rx2_6912 9381;
BA_ "SigType" SG_ 2215572463 Inv_SDM_E_Data_Pg_Rx2_6912 6;
BA_ "SPN" SG_ 2215572463 Inv_SDM_E_Data_Pg_Rx2_6912 9388;
BA_ "SigType" SG_ 2215572463 Inv_SDM_Data_Pg_Rx2_6912 6;
BA_ "SPN" SG_ 2215572463 Inv_SDM_Data_Pg_Rx2_6912 9387;
BA_ "SigType" SG_ 2216424431 HS_Ctl1CRC_Rx2 6;
BA_ "SPN" SG_ 2216424431 HS_Ctl1CRC_Rx2 13028;
BA_ "SigType" SG_ 2216424431 HS_Ctl1Ctr_Rx2 6;
BA_ "SPN" SG_ 2216424431 HS_Ctl1Ctr_Rx2 13027;
BA_ "SigType" SG_ 2216424431 HS_HiUBusLoSideRestrCnctReq_Rx2 6;
BA_ "SPN" SG_ 2216424431 HS_HiUBusLoSideRestrCnctReq_Rx2 8434;
BA_ "SigType" SG_ 2216424431 HS_HiUBusHiSideRestrCnctReq_Rx2 6;
BA_ "SPN" SG_ 2216424431 HS_HiUBusHiSideRestrCnctReq_Rx2 8433;
BA_ "SigType" SG_ 2216424431 HS_OperConsent_Rx2 6;
BA_ "SPN" SG_ 2216424431 HS_OperConsent_Rx2 8412;
BA_ "SigType" SG_ 2216424431 HS_EnaIntChrgrCmd_Rx2 6;
BA_ "SPN" SG_ 2216424431 HS_EnaIntChrgrCmd_Rx2 8213;
BA_ "SigType" SG_ 2216424431 HS_CellBalnCmd_Rx2 6;
BA_ "SPN" SG_ 2216424431 HS_CellBalnCmd_Rx2 8127;
BA_ "SigType" SG_ 2216424431 HS_HiUBusPasIslnTestCmd_Rx2 6;
BA_ "SPN" SG_ 2216424431 HS_HiUBusPasIslnTestCmd_Rx2 8126;
BA_ "SigType" SG_ 2216424431 HS_HiUBusAcvIslnTestCmd_Rx2 6;
BA_ "SPN" SG_ 2216424431 HS_HiUBusAcvIslnTestCmd_Rx2 8125;
BA_ "SigType" SG_ 2216424431 HS_PwrDwnCmd_Rx2 6;
BA_ "SPN" SG_ 2216424431 HS_PwrDwnCmd_Rx2 8124;
BA_ "SigType" SG_ 2216424431 HS_HiUBusCnctCmd_Rx2 6;
BA_ "SPN" SG_ 2216424431 HS_HiUBusCnctCmd_Rx2 8123;
BA_ "SPN" SG_ 2162881313 RQST_Rx1 2540;
BA_ "SPN" SG_ 2551119859 SDM_Data_CRC_Tx_61423 9383;
BA_ "SigType" SG_ 2551119859 SDM_Data_CRC_Tx_61423 6;
BA_ "SPN" SG_ 2551119859 Inv_SDM_PF_Value_Tx_61423 9386;
BA_ "SigType" SG_ 2551119859 Inv_SDM_PF_Value_Tx_61423 6;
BA_ "SPN" SG_ 2551119859 Inv_SDM_PS_Value_Tx_61423 9385;
BA_ "SigType" SG_ 2551119859 Inv_SDM_PS_Value_Tx_61423 6;
BA_ "SPN" SG_ 2551119859 Inv_SDM_SA_Tx_61423 9384;
BA_ "SigType" SG_ 2551119859 Inv_SDM_SA_Tx_61423 6;
BA_ "SPN" SG_ 2551119859 Sequence_Number_Tx_61423 9382;
BA_ "SigType" SG_ 2551119859 Sequence_Number_Tx_61423 6;
BA_ "SPN" SG_ 2551119859 SHM_Reserved_Tx_61423 9381;
BA_ "SigType" SG_ 2551119859 SHM_Reserved_Tx_61423 6;
BA_ "SPN" SG_ 2551119859 Inv_SDM_Ext_Data_Pg_Tx_61423 9388;
BA_ "SigType" SG_ 2551119859 Inv_SDM_Ext_Data_Pg_Tx_61423 6;
BA_ "SPN" SG_ 2551119859 Inv_SDM_Data_Pg_Tx_61423 9387;
BA_ "SigType" SG_ 2551119859 Inv_SDM_Data_Pg_Tx_61423 6;
BA_ "SPN" SG_ 2364576499 HS_CellTempDiffStatus 8078;
BA_ "GenSigStartValue" SG_ 2364576499 HS_AvgCellTemp 8736;
BA_ "SPN" SG_ 2364576499 HS_AvgCellTemp 8077;
BA_ "GenSigStartValue" SG_ 2364576499 HS_LowCellTemp 8736;
BA_ "SPN" SG_ 2364576499 HS_LowCellTemp 8076;
BA_ "SPN" SG_ 2364576499 HS_HiCellTemp 8075;
BA_ "GenSigStartValue" SG_ 2364576499 HS_HiCellTemp 8736;
BA_ "SPN" SG_ 2566894835 Current_Charging_Max_Actual 517031;
BA_ "GenSigStartValue" SG_ 2566894835 Current_Charging_Max_Actual 2000;
BA_ "SPN" SG_ 2566894835 Current_Discharging_Max_Actual 517030;
BA_ "GenSigStartValue" SG_ 2566894835 Current_Discharging_Max_Actual 2000;
BA_ "SPN" SG_ 2566894835 Current_Actual 517029;
BA_ "GenSigStartValue" SG_ 2566894835 Current_Actual 2000;
BA_ "GenSigStartValue" SG_ 2566894835 P_Actual 2000;
BA_ "SPN" SG_ 2566894835 P_Actual 517028;
BA_ "SPN" SG_ 2566894835 Reserved_PGN65476 517027;
BA_ "SPN" SG_ 2566894835 Balancing_Active 517026;
BA_ "SPN" SG_ 2566894835 State_Es_Relay 517025;
BA_ "SPN" SG_ 2566894835 PS_Lock_Activated 517024;
BA_ "SPN" SG_ 2566894835 State_Of_Reduction 517023;
BA_ "SPN" SG_ 2566894835 State_Device 517022;
BA_ "SPN" SG_ 2349789985 SDM_Data_CRC_Rx_61427 9383;
BA_ "SigType" SG_ 2349789985 SDM_Data_CRC_Rx_61427 6;
BA_ "SPN" SG_ 2349789985 Inv_SDM_PF_Value_Rx_61427 9386;
BA_ "SigType" SG_ 2349789985 Inv_SDM_PF_Value_Rx_61427 6;
BA_ "SPN" SG_ 2349789985 Inv_SDM_PS_Value_Rx_61427 9385;
BA_ "SigType" SG_ 2349789985 Inv_SDM_PS_Value_Rx_61427 6;
BA_ "SPN" SG_ 2349789985 Inv_SDM_SA_Rx_61427 9384;
BA_ "SigType" SG_ 2349789985 Inv_SDM_SA_Rx_61427 6;
BA_ "SPN" SG_ 2349789985 Sequence_Number_Rx_61427 9382;
BA_ "SigType" SG_ 2349789985 Sequence_Number_Rx_61427 6;
BA_ "SPN" SG_ 2349789985 SHM_Reserved_Rx_61427 9381;
BA_ "SigType" SG_ 2349789985 SHM_Reserved_Rx_61427 6;
BA_ "SPN" SG_ 2349789985 Inv_SDM_E_Data_Pg_Rx_61427 9388;
BA_ "SigType" SG_ 2349789985 Inv_SDM_E_Data_Pg_Rx_61427 6;
BA_ "SPN" SG_ 2349789985 Inv_SDM_Data_Pg_Rx_61427 9387;
BA_ "SigType" SG_ 2349789985 Inv_SDM_Data_Pg_Rx_61427 6;
BA_ "SPN" SG_ 2364535585 CRC_PGN61427 517039;
BA_ "SigType" SG_ 2364535585 CRC_PGN61427 6;
BA_ "SPN" SG_ 2364535585 Counter_PGN61427 517038;
BA_ "SigType" SG_ 2364535585 Counter_PGN61427 6;
BA_ "SPN" SG_ 2364535585 Terminal_Voltage_Actual 517037;
BA_ "SigType" SG_ 2364535585 Terminal_Voltage_Actual 6;
BA_ "SPN" SG_ 2364535585 Reserved_2_PGN61427 517036;
BA_ "SigType" SG_ 2364535585 Reserved_2_PGN61427 6;
BA_ "SPN" SG_ 2364535585 Service_Mode_Request 517035;
BA_ "SigType" SG_ 2364535585 Service_Mode_Request 6;
BA_ "SPN" SG_ 2364535585 Reserved_1_PGN61427 517034;
BA_ "SigType" SG_ 2364535585 Reserved_1_PGN61427 6;
BA_ "SPN" SG_ 2364535585 Control_Es_Relay 517033;
BA_ "SigType" SG_ 2364535585 Control_Es_Relay 6;
BA_ "SPN" SG_ 2364535585 ShutDown_Clearance 517032;
BA_ "SigType" SG_ 2364535585 ShutDown_Clearance 6;
BA_ "SigType" SG_ 2565808627 UDchaLimSho 6;
BA_ "SPN" SG_ 2565808627 UDchaLimSho 517044;
BA_ "SigType" SG_ 2565808627 UDchaLimLong 6;
BA_ "SPN" SG_ 2565808627 UDchaLimLong 517043;
BA_ "SigType" SG_ 2565808627 UChLimLong 6;
BA_ "SPN" SG_ 2565808627 UChLimLong 517042;
BA_ "SigType" SG_ 2565808627 IDchaLimLong 6;
BA_ "SPN" SG_ 2565808627 IDchaLimLong 517041;
BA_ "SPN" SG_ 2565808627 IChLimLong 517040;
BA_ "SigType" SG_ 2565808627 IChLimLong 6;
BA_ "SPN" SG_ 2162827763 RQST_Tx 2540;
BA_ "SPN" SG_ 2566834931 Flash_Mil 3038;
BA_ "SigType" SG_ 2566834931 Flash_Mil 4;
BA_ "SPN" SG_ 2566834931 Flash_Rsl 3039;
BA_ "SigType" SG_ 2566834931 Flash_Rsl 4;
BA_ "SPN" SG_ 2566834931 Flash_Awl 3040;
BA_ "SigType" SG_ 2566834931 Flash_Awl 4;
BA_ "SPN" SG_ 2566834931 Flash_ProtLamp 3041;
BA_ "SigType" SG_ 2566834931 Flash_ProtLamp 4;
BA_ "SigType" SG_ 2566834931 ProtLamp 4;
BA_ "SPN" SG_ 2566834931 ProtLamp 987;
BA_ "SigType" SG_ 2566834931 Awl 4;
BA_ "SPN" SG_ 2566834931 Awl 624;
BA_ "SigType" SG_ 2566834931 Rsl 4;
BA_ "SPN" SG_ 2566834931 Rsl 623;
BA_ "SigType" SG_ 2566834931 Mil 4;
BA_ "SPN" SG_ 2566834931 Mil 1213;
BA_ "SPN" SG_ 2566834931 Spn01 1214;
BA_ "SPN" SG_ 2566834931 SpnHigh01 1214;
BA_ "SPN" SG_ 2566834931 Fmi01 1215;
BA_ "SPN" SG_ 2566834931 Oc01 1216;
BA_ "SPN" SG_ 2566834931 SpnCm01 1706;
BA_ "SPN" SG_ 2566834931 Spn02 1214;
BA_ "SPN" SG_ 2566834931 SpnHigh02 1214;
BA_ "SPN" SG_ 2566834931 Fmi02 1215;
BA_ "SPN" SG_ 2566834931 Oc02 1216;
BA_ "SPN" SG_ 2566834931 SpnCm02 1706;
BA_ "SPN" SG_ 2566834931 Spn03 1214;
BA_ "SPN" SG_ 2566834931 SpnHigh03 1214;
BA_ "SPN" SG_ 2566834931 Fmi03 1215;
BA_ "SPN" SG_ 2566834931 Oc03 1216;
BA_ "SPN" SG_ 2566834931 SpnCm03 1706;
BA_ "SPN" SG_ 2566834931 Spn04 1214;
BA_ "SPN" SG_ 2566834931 SpnHigh04 1214;
BA_ "SPN" SG_ 2566834931 Fmi04 1215;
BA_ "SPN" SG_ 2566834931 Oc04 1216;
BA_ "SPN" SG_ 2566834931 SpnCm04 1706;
BA_ "SPN" SG_ 2566834931 Spn05 1214;
BA_ "SPN" SG_ 2566834931 SpnHigh05 1214;
BA_ "SPN" SG_ 2566834931 Fmi05 1215;
BA_ "SPN" SG_ 2566834931 Oc05 1216;
BA_ "SPN" SG_ 2566834931 SpnCm05 1706;
BA_ "SPN" SG_ 2566834931 Spn06 1214;
BA_ "SPN" SG_ 2566834931 SpnHigh06 1214;
BA_ "SPN" SG_ 2566834931 Fmi06 1215;
BA_ "SPN" SG_ 2566834931 Oc06 1216;
BA_ "SPN" SG_ 2566834931 SpnCm06 1706;
BA_ "SPN" SG_ 2566834931 Spn07 1214;
BA_ "SPN" SG_ 2566834931 SpnHigh07 1214;
BA_ "SPN" SG_ 2566834931 Fmi07 1215;
BA_ "SPN" SG_ 2566834931 Oc07 1216;
BA_ "SPN" SG_ 2566834931 SpnCm07 1706;
BA_ "SPN" SG_ 2566834931 Spn08 1214;
BA_ "SPN" SG_ 2566834931 SpnHigh08 1214;
BA_ "SPN" SG_ 2566834931 Fmi08 1215;
BA_ "SPN" SG_ 2566834931 Oc08 1216;
BA_ "SPN" SG_ 2566834931 SpnCm08 1706;
BA_ "SPN" SG_ 2566834931 Spn09 1214;
BA_ "SPN" SG_ 2566834931 SpnHigh09 1214;
BA_ "SPN" SG_ 2566834931 Fmi09 1215;
BA_ "SPN" SG_ 2566834931 Oc09 1216;
BA_ "SPN" SG_ 2566834931 SpnCm09 1706;
BA_ "SPN" SG_ 2566834931 Spn10 1214;
BA_ "SPN" SG_ 2566834931 SpnHigh10 1214;
BA_ "SPN" SG_ 2566834931 Fmi10 1215;
BA_ "SPN" SG_ 2566834931 Oc10 1216;
BA_ "SPN" SG_ 2566834931 SpnCm10 1706;
BA_ "SigType" SG_ 2416902131 Inv_SDM_E_Data_Pg_Tx_65473 6;
BA_ "SPN" SG_ 2416902131 Inv_SDM_E_Data_Pg_Tx_65473 9388;
BA_ "SigType" SG_ 2416902131 Inv_SDM_Data_Pg_Tx_65473 6;
BA_ "SPN" SG_ 2416902131 Inv_SDM_Data_Pg_Tx_65473 9387;
BA_ "SigType" SG_ 2416902131 Inv_SDM_PF_Value_Tx_65473 6;
BA_ "SPN" SG_ 2416902131 Inv_SDM_PF_Value_Tx_65473 9386;
BA_ "SigType" SG_ 2416902131 Inv_SDM_PS_Value_Tx_65473 6;
BA_ "SPN" SG_ 2416902131 Inv_SDM_PS_Value_Tx_65473 9385;
BA_ "SigType" SG_ 2416902131 Inv_SDM_SA_Tx_65473 6;
BA_ "SPN" SG_ 2416902131 Inv_SDM_SA_Tx_65473 9384;
BA_ "SigType" SG_ 2416902131 SDM_Data_CRC_Tx_65473 6;
BA_ "SPN" SG_ 2416902131 SDM_Data_CRC_Tx_65473 9383;
BA_ "SigType" SG_ 2416902131 Sequence_Number_Tx_65473 6;
BA_ "SPN" SG_ 2416902131 Sequence_Number_Tx_65473 9382;
BA_ "SigType" SG_ 2416902131 SHM_Reserved_Tx_65473 6;
BA_ "SPN" SG_ 2416902131 SHM_Reserved_Tx_65473 9381;
BA_ "SigType" SG_ 2484010995 Inv_SDM_E_Data_Pg_Tx_65472 6;
BA_ "SPN" SG_ 2484010995 Inv_SDM_E_Data_Pg_Tx_65472 9388;
BA_ "SigType" SG_ 2484010995 Inv_SDM_Data_Pg_Tx_65472 6;
BA_ "SPN" SG_ 2484010995 Inv_SDM_Data_Pg_Tx_65472 9387;
BA_ "SigType" SG_ 2484010995 Inv_SDM_PF_Value_Tx_65472 6;
BA_ "SPN" SG_ 2484010995 Inv_SDM_PF_Value_Tx_65472 9386;
BA_ "SigType" SG_ 2484010995 Inv_SDM_PS_Value_Tx_65472 6;
BA_ "SPN" SG_ 2484010995 Inv_SDM_PS_Value_Tx_65472 9385;
BA_ "SigType" SG_ 2484010995 Inv_SDM_SA_Tx_65472 6;
BA_ "SPN" SG_ 2484010995 Inv_SDM_SA_Tx_65472 9384;
BA_ "SigType" SG_ 2484010995 SDM_Data_CRC_Tx_65472 6;
BA_ "SPN" SG_ 2484010995 SDM_Data_CRC_Tx_65472 9383;
BA_ "SigType" SG_ 2484010995 Sequence_Number_Tx_65472 6;
BA_ "SPN" SG_ 2484010995 Sequence_Number_Tx_65472 9382;
BA_ "SigType" SG_ 2484010995 SHM_Reserved_Tx_65472 6;
BA_ "SPN" SG_ 2484010995 SHM_Reserved_Tx_65472 9381;
BA_ "SigType" SG_ 2349793267 Inv_SDM_E_Data_Pg_Tx_61584 6;
BA_ "SPN" SG_ 2349793267 Inv_SDM_E_Data_Pg_Tx_61584 9388;
BA_ "SigType" SG_ 2349793267 Inv_SDM_Data_Pg_Tx_61584 6;
BA_ "SPN" SG_ 2349793267 Inv_SDM_Data_Pg_Tx_61584 9387;
BA_ "SigType" SG_ 2349793267 Inv_SDM_PF_Value_Tx_61584 6;
BA_ "SPN" SG_ 2349793267 Inv_SDM_PF_Value_Tx_61584 9386;
BA_ "SigType" SG_ 2349793267 Inv_SDM_PS_Value_Tx_61584 6;
BA_ "SPN" SG_ 2349793267 Inv_SDM_PS_Value_Tx_61584 9385;
BA_ "SigType" SG_ 2349793267 Inv_SDM_SA_Tx_61584 6;
BA_ "SPN" SG_ 2349793267 Inv_SDM_SA_Tx_61584 9384;
BA_ "SigType" SG_ 2349793267 SDM_Data_CRC_Tx_61584 6;
BA_ "SPN" SG_ 2349793267 SDM_Data_CRC_Tx_61584 9383;
BA_ "SigType" SG_ 2349793267 Sequence_Number_Tx_61584 6;
BA_ "SPN" SG_ 2349793267 Sequence_Number_Tx_61584 9382;
BA_ "SigType" SG_ 2349793267 SHM_Reserved_Tx_61584 6;
BA_ "SPN" SG_ 2349793267 SHM_Reserved_Tx_61584 9381;
BA_ "SigType" SG_ 2216424225 HS_HiUBusCnctCmd_Rx1 6;
BA_ "SPN" SG_ 2216424225 HS_HiUBusCnctCmd_Rx1 8123;
BA_ "SigType" SG_ 2216424225 HS_PwrDwnCmd_Rx1 6;
BA_ "SPN" SG_ 2216424225 HS_PwrDwnCmd_Rx1 8124;
BA_ "SigType" SG_ 2216424225 HS_HiUBusAcvIslnTestCmd_Rx1 6;
BA_ "SPN" SG_ 2216424225 HS_HiUBusAcvIslnTestCmd_Rx1 8125;
BA_ "SigType" SG_ 2216424225 HS_HiUBusPasIslnTestCmd_Rx1 6;
BA_ "SPN" SG_ 2216424225 HS_HiUBusPasIslnTestCmd_Rx1 8126;
BA_ "SigType" SG_ 2216424225 HS_CellBalnCmd_Rx1 6;
BA_ "SPN" SG_ 2216424225 HS_CellBalnCmd_Rx1 8127;
BA_ "SigType" SG_ 2216424225 HS_EnaIntChrgrCmd_Rx1 6;
BA_ "SPN" SG_ 2216424225 HS_EnaIntChrgrCmd_Rx1 8213;
BA_ "SigType" SG_ 2216424225 HS_OperConsent_Rx1 6;
BA_ "SPN" SG_ 2216424225 HS_OperConsent_Rx1 8412;
BA_ "SigType" SG_ 2216424225 HS_HiUBusHiSideRestrCnctReq_Rx1 6;
BA_ "SPN" SG_ 2216424225 HS_HiUBusHiSideRestrCnctReq_Rx1 8433;
BA_ "SigType" SG_ 2216424225 HS_HiUBusLoSideRestrCnctReq_Rx1 6;
BA_ "SPN" SG_ 2216424225 HS_HiUBusLoSideRestrCnctReq_Rx1 8434;
BA_ "SigType" SG_ 2216424225 HS_Ctl1Ctr_Rx1 6;
BA_ "SPN" SG_ 2216424225 HS_Ctl1Ctr_Rx1 13027;
BA_ "SigType" SG_ 2216424225 HS_Ctl1CRC_Rx1 6;
BA_ "SPN" SG_ 2216424225 HS_Ctl1CRC_Rx1 13028;
BA_ "SigType" SG_ 2215575539 SDM_Data_CRC_Tx_61590 6;
BA_ "SPN" SG_ 2215575539 SDM_Data_CRC_Tx_61590 9383;
BA_ "SigType" SG_ 2215575539 Inv_SDM_SA_Tx_61590 6;
BA_ "SPN" SG_ 2215575539 Inv_SDM_SA_Tx_61590 9384;
BA_ "SigType" SG_ 2215575539 Inv_SDM_PS_Value_Tx_61590 6;
BA_ "SPN" SG_ 2215575539 Inv_SDM_PS_Value_Tx_61590 9385;
BA_ "SigType" SG_ 2215575539 Inv_SDM_PF_Value_Tx_61590 6;
BA_ "SPN" SG_ 2215575539 Inv_SDM_PF_Value_Tx_61590 9386;
BA_ "SigType" SG_ 2215575539 Sequence_Number_Tx_61590 6;
BA_ "SPN" SG_ 2215575539 Sequence_Number_Tx_61590 9382;
BA_ "SigType" SG_ 2215575539 SHM_Reserved_Tx_61590 6;
BA_ "SPN" SG_ 2215575539 SHM_Reserved_Tx_61590 9381;
BA_ "SigType" SG_ 2215575539 Inv_SDM_E_Data_Pg_Tx_61590 6;
BA_ "SPN" SG_ 2215575539 Inv_SDM_E_Data_Pg_Tx_61590 9388;
BA_ "SigType" SG_ 2215575539 Inv_SDM_Data_Pg_Tx_61590 6;
BA_ "SPN" SG_ 2215575539 Inv_SDM_Data_Pg_Tx_61590 9387;
BA_ "SigType" SG_ 2282684403 SDM_Data_CRC_Tx_61708 6;
BA_ "SPN" SG_ 2282684403 SDM_Data_CRC_Tx_61708 9383;
BA_ "SigType" SG_ 2282684403 Inv_SDM_SA_Tx_61708 6;
BA_ "SPN" SG_ 2282684403 Inv_SDM_SA_Tx_61708 9384;
BA_ "SigType" SG_ 2282684403 Inv_SDM_PS_Value_Tx_61708 6;
BA_ "SPN" SG_ 2282684403 Inv_SDM_PS_Value_Tx_61708 9385;
BA_ "SigType" SG_ 2282684403 Inv_SDM_PF_Value_Tx_61708 6;
BA_ "SPN" SG_ 2282684403 Inv_SDM_PF_Value_Tx_61708 9386;
BA_ "SigType" SG_ 2282684403 Sequence_Number_Tx_61708 6;
BA_ "SPN" SG_ 2282684403 Sequence_Number_Tx_61708 9382;
BA_ "SigType" SG_ 2282684403 SHM_Reserved_Tx_61708 6;
BA_ "SPN" SG_ 2282684403 SHM_Reserved_Tx_61708 9381;
BA_ "SigType" SG_ 2282684403 Inv_SDM_E_Data_Pg_Tx_61708 6;
BA_ "SPN" SG_ 2282684403 Inv_SDM_E_Data_Pg_Tx_61708 9388;
BA_ "SigType" SG_ 2282684403 Inv_SDM_Data_Pg_Tx_61708 6;
BA_ "SPN" SG_ 2282684403 Inv_SDM_Data_Pg_Tx_61708 9387;
BA_ "SPN" SG_ 2551119649 SDM_Data_CRC_Rx_65269 9383;
BA_ "SigType" SG_ 2551119649 SDM_Data_CRC_Rx_65269 6;
BA_ "SPN" SG_ 2551119649 Inv_SDM_PF_Value_Rx_65269 9386;
BA_ "SigType" SG_ 2551119649 Inv_SDM_PF_Value_Rx_65269 6;
BA_ "SPN" SG_ 2551119649 Inv_SDM_PS_Value_Rx_65269 9385;
BA_ "SigType" SG_ 2551119649 Inv_SDM_PS_Value_Rx_65269 6;
BA_ "SPN" SG_ 2551119649 Inv_SDM_SA_Rx_65269 9384;
BA_ "SigType" SG_ 2551119649 Inv_SDM_SA_Rx_65269 6;
BA_ "SPN" SG_ 2551119649 Sequence_Number_Rx_65269 9382;
BA_ "SigType" SG_ 2551119649 Sequence_Number_Rx_65269 6;
BA_ "SPN" SG_ 2551119649 SHM_Reserved_Rx_65269 9381;
BA_ "SigType" SG_ 2551119649 SHM_Reserved_Rx_65269 6;
BA_ "SPN" SG_ 2551119649 Inv_SDM_E_Data_Pg_Rx_65269 9388;
BA_ "SigType" SG_ 2551119649 Inv_SDM_E_Data_Pg_Rx_65269 6;
BA_ "SPN" SG_ 2551119649 Inv_SDM_Data_Pg_Rx_65269 9387;
BA_ "SigType" SG_ 2551119649 Inv_SDM_Data_Pg_Rx_65269 6;
BA_ "SPN" SG_ 2484010785 SDM_Data_CRC_Rx_65265 9383;
BA_ "SigType" SG_ 2484010785 SDM_Data_CRC_Rx_65265 6;
BA_ "SPN" SG_ 2484010785 Inv_SDM_PF_Value_Rx_65265 9386;
BA_ "SigType" SG_ 2484010785 Inv_SDM_PF_Value_Rx_65265 6;
BA_ "SPN" SG_ 2484010785 Inv_SDM_PS_Value_Rx_65265 9385;
BA_ "SigType" SG_ 2484010785 Inv_SDM_PS_Value_Rx_65265 6;
BA_ "SPN" SG_ 2484010785 Inv_SDM_SA_Rx_65265 9384;
BA_ "SigType" SG_ 2484010785 Inv_SDM_SA_Rx_65265 6;
BA_ "SPN" SG_ 2484010785 Sequence_Number_Rx_65265 9382;
BA_ "SigType" SG_ 2484010785 Sequence_Number_Rx_65265 6;
BA_ "SPN" SG_ 2484010785 SHM_Reserved_Rx_65265 9381;
BA_ "SigType" SG_ 2484010785 SHM_Reserved_Rx_65265 6;
BA_ "SPN" SG_ 2484010785 Inv_SDM_E_Data_Pg_Rx_65265 9388;
BA_ "SigType" SG_ 2484010785 Inv_SDM_E_Data_Pg_Rx_65265 6;
BA_ "SPN" SG_ 2484010785 Inv_SDM_Data_Pg_Rx_65265 9387;
BA_ "SigType" SG_ 2484010785 Inv_SDM_Data_Pg_Rx_65265 6;
BA_ "SPN" SG_ 2416901921 SDM_Data_CRC_Rx_61483 9383;
BA_ "SigType" SG_ 2416901921 SDM_Data_CRC_Rx_61483 6;
BA_ "SPN" SG_ 2416901921 Inv_SDM_SA_Rx_61483 9384;
BA_ "SigType" SG_ 2416901921 Inv_SDM_SA_Rx_61483 6;
BA_ "SPN" SG_ 2416901921 Inv_SDM_PS_Value_Rx_61483 9385;
BA_ "SigType" SG_ 2416901921 Inv_SDM_PS_Value_Rx_61483 6;
BA_ "SPN" SG_ 2416901921 Inv_SDM_PF_Value_Rx_61483 9386;
BA_ "SigType" SG_ 2416901921 Inv_SDM_PF_Value_Rx_61483 6;
BA_ "SPN" SG_ 2416901921 Sequence_Number_Rx_61483 9382;
BA_ "SigType" SG_ 2416901921 Sequence_Number_Rx_61483 6;
BA_ "SPN" SG_ 2416901921 SHM_Reserved_Rx_61483 9381;
BA_ "SigType" SG_ 2416901921 SHM_Reserved_Rx_61483 6;
BA_ "SPN" SG_ 2416901921 Inv_SDM_E_Data_Pg_Rx_61483 9388;
BA_ "SigType" SG_ 2416901921 Inv_SDM_E_Data_Pg_Rx_61483 6;
BA_ "SPN" SG_ 2416901921 Inv_SDM_Data_Pg_Rx_61483 9387;
BA_ "SigType" SG_ 2416901921 Inv_SDM_Data_Pg_Rx_61483 6;
BA_ "SigType" SG_ 2282627571 Inv_SDM_Ext_Data_Pg_Tx_6912 6;
BA_ "SPN" SG_ 2282627571 Inv_SDM_Ext_Data_Pg_Tx_6912 9388;
BA_ "SigType" SG_ 2282627571 Inv_SDM_Data_Pg_Tx_6912 6;
BA_ "SPN" SG_ 2282627571 Inv_SDM_Data_Pg_Tx_6912 9387;
BA_ "SigType" SG_ 2282627571 Inv_SDM_PF_Value_Tx_6912 6;
BA_ "SPN" SG_ 2282627571 Inv_SDM_PF_Value_Tx_6912 9386;
BA_ "SigType" SG_ 2282627571 Inv_SDM_PS_Value_Tx_6912 6;
BA_ "SPN" SG_ 2282627571 Inv_SDM_PS_Value_Tx_6912 9385;
BA_ "SigType" SG_ 2282627571 Inv_SDM_SA_Tx_6912 6;
BA_ "SPN" SG_ 2282627571 Inv_SDM_SA_Tx_6912 9384;
BA_ "SigType" SG_ 2282627571 SDM_Data_CRC_Tx_6912 6;
BA_ "SPN" SG_ 2282627571 SDM_Data_CRC_Tx_6912 9383;
BA_ "SigType" SG_ 2282627571 Sequence_Number_Tx_6912 6;
BA_ "SPN" SG_ 2282627571 Sequence_Number_Tx_6912 9382;
BA_ "SigType" SG_ 2282627571 SHM_Reserved_Tx_6912 6;
BA_ "SPN" SG_ 2282627571 SHM_Reserved_Tx_6912 9381;
BA_ "SPN" SG_ 2499789043 ThermRunAwPermsnToCls 517008;
BA_ "SPN" SG_ 2499789043 LockMemPermsnToCls 517007;
BA_ "SPN" SG_ 2499789043 IslnPermsnToCls 517006;
BA_ "SPN" SG_ 2499789043 IPermsnToCls 517005;
BA_ "SPN" SG_ 2499789043 DcChCtctrPermsnToCls 517004;
BA_ "SPN" SG_ 2499789043 CtctrStuckPermsnToCls 517003;
BA_ "SPN" SG_ 2499789043 CrashPermsnToCls 517002;
BA_ "SPN" SG_ 2499789043 CptTPermsnToCls 517001;
BA_ "SPN" SG_ 2499789043 CellUPermsnToCls 517009;
BA_ "SPN" SG_ 2499789043 CellTPermsnToCls 517000;
BA_ "SPN" SG_ 2499789299 HvilPermsnToCls 517019;
BA_ "SPN" SG_ 2499789299 ThermEveStsCellT 517017;
BA_ "SPN" SG_ 2499789299 P 517016;
BA_ "SPN" SG_ 2499789299 ErrLvl 517015;
BA_ "SPN" SG_ 2633011699 HS_CellVoltDiffStatus 5924;
BA_ "SPN" SG_ 2633011699 HS_LowCellVolt 5923;
BA_ "SPN" SG_ 2633011699 HS_HiCellVolt 5922;
BA_ "SPN" SG_ 2633011699 HS_FastUpdSOC 5921;
BA_ "SPN" SG_ 2498825459 HS_HiVoltBusPasIslTR 8432;
BA_ "SPN" SG_ 2498825459 HS_HiVoltBusActIslTR 8431;
BA_ "SPN" SG_ 2498825459 HS_LowCellSOCCellNum 8248;
BA_ "SPN" SG_ 2498825459 HS_LowCellSOCMNum 8047;
BA_ "SPN" SG_ 2498825459 HS_HiCellSOCCellNum 8246;
BA_ "SPN" SG_ 2498825459 HS_HiCellSOCMNum 8245;
BA_ "SPN" SG_ 2215572257 SHM_Reserved_Rx1_6912 9381;
BA_ "SigType" SG_ 2215572257 SHM_Reserved_Rx1_6912 6;
BA_ "SPN" SG_ 2215572257 SDM_Data_CRC_Rx1_6912 9383;
BA_ "SigType" SG_ 2215572257 SDM_Data_CRC_Rx1_6912 6;
BA_ "SPN" SG_ 2215572257 Sequence_Number_Rx1_6912 9382;
BA_ "SigType" SG_ 2215572257 Sequence_Number_Rx1_6912 6;
BA_ "SPN" SG_ 2215572257 Inv_SDM_SA_Rx1_6912 9384;
BA_ "SigType" SG_ 2215572257 Inv_SDM_SA_Rx1_6912 6;
BA_ "SPN" SG_ 2215572257 Inv_SDM_PS_Value_Rx1_6912 9385;
BA_ "SigType" SG_ 2215572257 Inv_SDM_PS_Value_Rx1_6912 6;
BA_ "SPN" SG_ 2215572257 Inv_SDM_PF_Value_Rx1_6912 9386;
BA_ "SigType" SG_ 2215572257 Inv_SDM_PF_Value_Rx1_6912 6;
BA_ "SPN" SG_ 2215572257 Inv_SDM_E_Data_Pg_Rx1_6912 9388;
BA_ "SigType" SG_ 2215572257 Inv_SDM_E_Data_Pg_Rx1_6912 6;
BA_ "SPN" SG_ 2215572257 Inv_SDM_Data_Pg_Rx1_6912 9387;
BA_ "SigType" SG_ 2215572257 Inv_SDM_Data_Pg_Rx1_6912 6;
BA_ "SPN" SG_ 2162881519 RQST_Rx2 2540;
BA_ "SigType" SG_ 2283479539 HS_HiUBusCnctCmd_Tx 6;
BA_ "SPN" SG_ 2283479539 HS_HiUBusCnctCmd_Tx 8123;
BA_ "SigType" SG_ 2283479539 HS_PwrDwnCmd_Tx 6;
BA_ "SPN" SG_ 2283479539 HS_PwrDwnCmd_Tx 8124;
BA_ "SigType" SG_ 2283479539 HS_HiUBusAcvIslnTestCmd_Tx 6;
BA_ "SPN" SG_ 2283479539 HS_HiUBusAcvIslnTestCmd_Tx 8125;
BA_ "SigType" SG_ 2283479539 HS_HiUBusPasIslnTestCmd_Tx 6;
BA_ "SPN" SG_ 2283479539 HS_HiUBusPasIslnTestCmd_Tx 8126;
BA_ "SigType" SG_ 2283479539 HS_CellBalnCmd_Tx 6;
BA_ "SPN" SG_ 2283479539 HS_CellBalnCmd_Tx 8127;
BA_ "SigType" SG_ 2283479539 HS_EnaIntChrgrCmd_Tx 6;
BA_ "SPN" SG_ 2283479539 HS_EnaIntChrgrCmd_Tx 8213;
BA_ "SigType" SG_ 2283479539 HS_OperConsent_Tx 6;
BA_ "SPN" SG_ 2283479539 HS_OperConsent_Tx 8412;
BA_ "SigType" SG_ 2283479539 HS_HiUBusHiSideRestrCnctReq_Tx 6;
BA_ "SPN" SG_ 2283479539 HS_HiUBusHiSideRestrCnctReq_Tx 8433;
BA_ "SigType" SG_ 2283479539 HS_HiUBusLoSideRestrCnctReq_Tx 6;
BA_ "SPN" SG_ 2283479539 HS_HiUBusLoSideRestrCnctReq_Tx 8434;
BA_ "SigType" SG_ 2283479539 HS_Ctl1Ctr_Tx 6;
BA_ "SPN" SG_ 2283479539 HS_Ctl1Ctr_Tx 13027;
BA_ "SigType" SG_ 2283479539 HS_Ctl1CRC_Tx 6;
BA_ "SPN" SG_ 2283479539 HS_Ctl1CRC_Tx 13028;
BA_ "SigType" SG_ 2565876513 Crash_Typ 6;
BA_ "SPN" SG_ 2565876513 Crash_Typ 4973;
BA_ "SigType" SG_ 2565876513 Crash_Ctr 6;
BA_ "SPN" SG_ 2565876513 Crash_Ctr 4974;
BA_ "SigType" SG_ 2565876513 Crash_Cks 6;
BA_ "SPN" SG_ 2565876513 Crash_Cks 4975;
BA_ "SigType" SG_ 2364575987 HS_AvlDchaPwr 6;
BA_ "SPN" SG_ 2364575987 HS_AvlDchaPwr 5917;
BA_ "SigType" SG_ 2364575987 HS_AvlChPwr 6;
BA_ "SPN" SG_ 2364575987 HS_AvlChPwr 5918;
BA_ "SigType" SG_ 2364575987 HS_ULvl 6;
BA_ "SPN" SG_ 2364575987 HS_ULvl 5919;
BA_ "SigType" SG_ 2364575987 HS_I 6;
BA_ "SPN" SG_ 2364575987 HS_I 5920;
BA_ "SigType" SG_ 2565903603 HS_DchaILim 6;
BA_ "SPN" SG_ 2565903603 HS_DchaILim 8082;
BA_ "SigType" SG_ 2565903603 HS_ChILim 6;
BA_ "SPN" SG_ 2565903603 HS_ChILim 8083;
BA_ "SigType" SG_ 2565903603 HS_MinCellStofCh 6;
BA_ "SPN" SG_ 2565903603 HS_MinCellStofCh 8084;
BA_ "SigType" SG_ 2565903603 HS_MaxCellStofCh 6;
BA_ "SPN" SG_ 2565903603 HS_MaxCellStofCh 8085;
BA_ "SigType" SG_ 2498795251 HS_HiUBusPosCtctrSt 6;
BA_ "SPN" SG_ 2498795251 HS_HiUBusPosCtctrSt 8091;
BA_ "SigType" SG_ 2498795251 HS_HiUBusNegCtctrSt 6;
BA_ "SPN" SG_ 2498795251 HS_HiUBusNegCtctrSt 8092;
BA_ "SigType" SG_ 2498795251 HS_HiUBusDcnctForewarning 6;
BA_ "SPN" SG_ 2498795251 HS_HiUBusDcnctForewarning 8093;
BA_ "SigType" SG_ 2498795251 HS_HiUBusPreChRlySt 6;
BA_ "SPN" SG_ 2498795251 HS_HiUBusPreChRlySt 8094;
BA_ "SigType" SG_ 2498795251 HS_CentrofPackCtctrSt 6;
BA_ "SPN" SG_ 2498795251 HS_CentrofPackCtctrSt 8095;
BA_ "SigType" SG_ 2498795251 HS_HiUBusAcvIslnTestSts 6;
BA_ "SPN" SG_ 2498795251 HS_HiUBusAcvIslnTestSts 8096;
BA_ "SigType" SG_ 2498795251 HS_HiUBusPasIslnTestSts 6;
BA_ "SPN" SG_ 2498795251 HS_HiUBusPasIslnTestSts 8097;
BA_ "SigType" SG_ 2498795251 HS_HVILSts 6;
BA_ "SPN" SG_ 2498795251 HS_HVILSts 8098;
BA_ "SigType" SG_ 2498795251 HS_JSwtSts 6;
BA_ "SPN" SG_ 2498795251 HS_JSwtSts 8099;
BA_ "SigType" SG_ 2498795251 HS_StofChSts 6;
BA_ "SPN" SG_ 2498795251 HS_StofChSts 8100;
BA_ "SigType" SG_ 2498795251 HS_CellBalSts 6;
BA_ "SPN" SG_ 2498795251 HS_CellBalSts 8101;
BA_ "SigType" SG_ 2498795251 HS_CellBalnAcv 6;
BA_ "SPN" SG_ 2498795251 HS_CellBalnAcv 8102;
BA_ "SigType" SG_ 2498795251 HS_IntChrgrSts 6;
BA_ "SPN" SG_ 2498795251 HS_IntChrgrSts 8207;
BA_ "SigType" SG_ 2498795251 HS_Sts1Ctr 6;
BA_ "SPN" SG_ 2498795251 HS_Sts1Ctr 13013;
BA_ "SigType" SG_ 2498795251 HS_HiUBusCnctnSts 6;
BA_ "SPN" SG_ 2498795251 HS_HiUBusCnctnSts 8413;
BA_ "SigType" SG_ 2498795251 HS_OperationalSts 6;
BA_ "SPN" SG_ 2498795251 HS_OperationalSts 8414;
BA_ "SigType" SG_ 2498795251 HS_NrofHPsRdy 6;
BA_ "SPN" SG_ 2498795251 HS_NrofHPsRdy 12905;
BA_ "SigType" SG_ 2498795251 HS_Sts1CRC 6;
BA_ "SPN" SG_ 2498795251 HS_Sts1CRC 13014;
BA_ "SigType" SG_ 2633015539 HS_DchaEC 6;
BA_ "SPN" SG_ 2633015539 HS_DchaEC 8205;
BA_ "SigType" SG_ 2633015539 HS_ChEC 6;
BA_ "SPN" SG_ 2633015539 HS_ChEC 8206;
BA_ "SigType" SG_ 2633015539 HS_MaxChULim 6;
BA_ "SPN" SG_ 2633015539 HS_MaxChULim 8090;
BA_ "SigType" SG_ 2566844672 Engine_Shutdwn_Ovride_Swtch 6;
BA_ "SPN" SG_ 2566844672 Engine_Shutdwn_Ovride_Swtch 1237;
BA_ "SigType" SG_ 2566844672 Engine_Diag_Test_Mode_Swtch 6;
BA_ "SPN" SG_ 2566844672 Engine_Diag_Test_Mode_Swtch 966;
BA_ "SigType" SG_ 2566844672 Engine_Idle_Decrement_Switch 6;
BA_ "SPN" SG_ 2566844672 Engine_Idle_Decrement_Switch 967;
BA_ "SigType" SG_ 2566844672 Engine_Idle_Increment_Switch 6;
BA_ "SPN" SG_ 2566844672 Engine_Idle_Increment_Switch 968;
BA_ "SigType" SG_ 2566844672 Cruise_Control_States 6;
BA_ "SPN" SG_ 2566844672 Cruise_Control_States 527;
BA_ "SigType" SG_ 2566844672 PTO_Governor_State 6;
BA_ "SPN" SG_ 2566844672 PTO_Governor_State 976;
BA_ "SigType" SG_ 2566844672 Cruise_Control_Set_Spd 6;
BA_ "SPN" SG_ 2566844672 Cruise_Control_Set_Spd 86;
BA_ "SigType" SG_ 2566844672 Cruise_Control_Accelerate_Swtch 6;
BA_ "SPN" SG_ 2566844672 Cruise_Control_Accelerate_Swtch 602;
BA_ "SigType" SG_ 2566844672 Cruise_Control_Resume_Swtch 6;
BA_ "SPN" SG_ 2566844672 Cruise_Control_Resume_Swtch 601;
BA_ "SigType" SG_ 2566844672 Cruise_Control_Coast_Decl_Switch 6;
BA_ "SPN" SG_ 2566844672 Cruise_Control_Coast_Decl_Switch 600;
BA_ "SigType" SG_ 2566844672 Cruise_Control_SetSwtch 6;
BA_ "SPN" SG_ 2566844672 Cruise_Control_SetSwtch 599;
BA_ "SigType" SG_ 2566844672 Clutch_Switch 6;
BA_ "SPN" SG_ 2566844672 Clutch_Switch 598;
BA_ "SigType" SG_ 2566844672 Brake_Switch 6;
BA_ "SPN" SG_ 2566844672 Brake_Switch 597;
BA_ "SigType" SG_ 2566844672 Cruise_Control_Enable_Swtch 6;
BA_ "SPN" SG_ 2566844672 Cruise_Control_Enable_Swtch 596;
BA_ "SigType" SG_ 2566844672 Cruise_Control_Active 6;
BA_ "SPN" SG_ 2566844672 Cruise_Control_Active 595;
BA_ "SigType" SG_ 2566844672 Wheel_Based_Veh_Spd 6;
BA_ "SPN" SG_ 2566844672 Wheel_Based_Veh_Spd 84;
BA_ "SigType" SG_ 2566844672 Cruise_Control_Pause_Swtch 6;
BA_ "SPN" SG_ 2566844672 Cruise_Control_Pause_Swtch 1633;
BA_ "SigType" SG_ 2566844672 Park_Brake_Rel_Inhibit_Req 6;
BA_ "SPN" SG_ 2566844672 Park_Brake_Rel_Inhibit_Req 3087;
BA_ "SigType" SG_ 2566844672 Parking_Brake_Swtch 6;
BA_ "SPN" SG_ 2566844672 Parking_Brake_Swtch 70;
BA_ "SPN" SG_ 2566844672 Two_Spd_Axle_Switch 69;
BA_ "SigType" SG_ 2566844672 Two_Spd_Axle_Switch 6;
BA_ "SigType" SG_ 2633785075 HS_StofHealth 6;
BA_ "SPN" SG_ 2633785075 HS_StofHealth 8121;
BA_ "SigType" SG_ 2633785075 HS_CtctrOpenUnderLoaCt 6;
BA_ "SPN" SG_ 2633785075 HS_CtctrOpenUnderLoaCt 8122;
BA_ "SigType" SG_ 2633785075 HS_TotEThroughput 6;
BA_ "SPN" SG_ 2633785075 HS_TotEThroughput 8211;
BA_ "SigType" SG_ 2633785075 HS_TotAccumdCh 6;
BA_ "SPN" SG_ 2633785075 HS_TotAccumdCh 8212;
BA_ "SigType" SG_ 2633785075 HS_TotLifetimeEInp 6;
BA_ "SPN" SG_ 2633785075 HS_TotLifetimeEInp 13365;
BA_ "SigType" SG_ 2633785075 HS_TotLifetimeEOutp 6;
BA_ "SPN" SG_ 2633785075 HS_TotLifetimeEOutp 13366;
BA_ "SigType" SG_ 2566841889 Seconds 6;
BA_ "SPN" SG_ 2566841889 Seconds 959;
BA_ "SigType" SG_ 2566841889 Minutes 6;
BA_ "SPN" SG_ 2566841889 Minutes 960;
BA_ "SigType" SG_ 2566841889 Hours 6;
BA_ "SPN" SG_ 2566841889 Hours 961;
BA_ "SigType" SG_ 2566841889 Month 6;
BA_ "SPN" SG_ 2566841889 Month 963;
BA_ "SigType" SG_ 2566841889 Day 6;
BA_ "SPN" SG_ 2566841889 Day 962;
BA_ "SigType" SG_ 2566841889 Year 6;
BA_ "SPN" SG_ 2566841889 Year 964;
BA_ "SigType" SG_ 2566841889 Lcl_minuteoffset 6;
BA_ "SPN" SG_ 2566841889 Lcl_minuteoffset 1601;
BA_ "SigType" SG_ 2566841889 Lcl_houroffset 6;
BA_ "SPN" SG_ 2566841889 Lcl_houroffset 1602;
BA_ "SigType" SG_ 2566845729 Barometric_P 6;
BA_ "SPN" SG_ 2566845729 Barometric_P 108;
BA_ "SigType" SG_ 2566845729 Cab_InteriorT 6;
BA_ "SPN" SG_ 2566845729 Cab_InteriorT 170;
BA_ "SigType" SG_ 2566845729 Amb_AirT 6;
BA_ "SPN" SG_ 2566845729 Amb_AirT 171;
BA_ "SigType" SG_ 2566845729 Eng_Intk1AirT 6;
BA_ "SPN" SG_ 2566845729 Eng_Intk1AirT 172;
BA_ "SigType" SG_ 2566845729 Road_SurfT 6;
BA_ "SPN" SG_ 2566845729 Road_SurfT 79;
VAL_ 2364606963 ThermMngtSysCooltLvl 3 "Not Available" 2 "Error" 1 "Coolant Level is sufficient" 0 "Coolant Level is not sufficient" ;
VAL_ 2364606963 ThermMngtSysMode 15 "Not Available" 14 "Faulted" 13 "Reserved" 12 "Reserved" 11 "Reserved" 10 "Reserved" 9 "Reserved" 8 "Reserved" 7 "Reserved" 6 "Reserved" 5 "Reserved" 4 "Drying" 3 "Heating" 2 "Cooling" 1 "Circulating" 0 "Off" ;
VAL_ 2364606963 ThermMngtSysHVILSts 3 "Not Available" 2 "Error" 1 "HVIL Open" 0 "HVIL Closed" ;
VAL_ 2364606963 ThermMngtSysHeatrSts 3 "Not Available" 2 "Error" 1 "Heater On" 0 "Heater Off" ;
VAL_ 2632777715 Control_Byte_TP_CM 16 "RTS" 17 "CTS" 19 "EoMA" 20 "ERTS" 21 "ECTS" 22 "EDPO" 23 "EEoMACK" 24 "EAbort" 32 "BAM" 255 "Abort" ;
VAL_ 2215572463 SDM_Data_CRC_Rx2_6912 3 "11b = Don't care/Take no action" 2 "10b = Reserved" 1 "01b = Enable charging" 0 "00b = Disable charging" ;
VAL_ 2215572463 Inv_SDM_PF_Value_Rx2_6912 3 "11b = Don't care/Take no action" 2 "10b = Reserved" 1 "01b = Enable charging" 0 "00b = Disable charging" ;
VAL_ 2215572463 Inv_SDM_PS_Value_Rx2_6912 3 "11b = Don't care/Take no action" 2 "10b = Reserved" 1 "01b = Enable charging" 0 "00b = Disable charging" ;
VAL_ 2215572463 Inv_SDM_SA_Rx2_6912 3 "11b = Don't care/Take no action" 2 "10b = Reserved" 1 "01b = Enable charging" 0 "00b = Disable charging" ;
VAL_ 2215572463 Sequence_Number_Rx2_6912 3 "11b = Don't care/Take no action" 2 "10b = Reserved" 1 "01b = Enable charging" 0 "00b = Disable charging" ;
VAL_ 2215572463 SHM_Reserved_Rx2_6912 3 "11b = Don't care/Take no action" 2 "10b = Reserved" 1 "01b = Enable charging" 0 "00b = Disable charging" ;
VAL_ 2215572463 Inv_SDM_E_Data_Pg_Rx2_6912 3 "11b = Don't care/Take no action" 2 "10b = Reserved" 1 "01b = Enable charging" 0 "00b = Disable charging" ;
VAL_ 2215572463 Inv_SDM_Data_Pg_Rx2_6912 3 "11b = Don't care/Take no action" 2 "10b = Reserved" 1 "01b = Enable charging" 0 "00b = Disable charging" ;
VAL_ 2216424431 HS_HiUBusLoSideRestrCnctReq_Rx2 3 "11b = Don't care/take no action" 2 "10b = Reserved" 1 "01b = Connection Requested" 0 "00b = Connection not Requested" ;
VAL_ 2216424431 HS_HiUBusHiSideRestrCnctReq_Rx2 3 "11b = Don't care/take no action" 2 "10b = Reserved" 1 "01b = Connection Requested" 0 "00b = Connection not Requested" ;
VAL_ 2216424431 HS_OperConsent_Rx2 3 "11b = Don't care/Take no action" 2 "10b = Error" 1 "01b = Consent given; system component consents to HVES instance operation" 0 "00b = Consent revoked; system component does not consent to HVES instance operation" ;
VAL_ 2216424431 HS_EnaIntChrgrCmd_Rx2 3 "11b = Don't care/Take no action" 2 "10b = Reserved" 1 "01b = Enable charging" 0 "00b = Disable charging" ;
VAL_ 2216424431 HS_CellBalnCmd_Rx2 3 "11b = Don't care/Take no action" 2 "10b = Reserved" 1 "01b = Cell Balancing requested" 0 "00b = Cell Balancing not requested" ;
VAL_ 2216424431 HS_HiUBusPasIslnTestCmd_Rx2 3 "11b = Don't care/Take no action" 2 "10b = Inhibit Passive Isolation Test" 1 "01b = Passive Isolation Test request" 0 "00b = Passive Isolation Test not requested" ;
VAL_ 2216424431 HS_HiUBusAcvIslnTestCmd_Rx2 3 "11b = Don't care/Take no action" 2 "10b = Inhibit Active Isolation Test" 1 "01b = Active Isolation Test request" 0 "00b = Active Isolation Test not requested" ;
VAL_ 2216424431 HS_PwrDwnCmd_Rx2 3 "11b = Don't care/Take no action" 2 "10b = Execute emergency power-down" 1 "01b = Execute normal power-down" 0 "00b = Power-down not requested" ;
VAL_ 2216424431 HS_HiUBusCnctCmd_Rx2 3 "11b = Don't care/Take no action" 2 "10b = Emergency contactor closure request" 1 "01b = Close Contactor; Connect HVES to high-voltage bus" 0 "00b = Open Contactor; Disconnect HVES from high-voltage bus" ;
VAL_ 2566894835 State_Es_Relay 7 "111b = Not available" 6 "110b = Error" 5 "101b = reserved" 4 "100b = Main Relays opening" 3 "11b = Main Relays closed" 2 "10b = All Es-Relays closed" 1 "01b = PreCharge-Relais closed" 0 "00b = All Es-Relays open" ;
VAL_ 2566894835 PS_Lock_Activated 3 "11b = Not available" 2 "10b = Lock is activated by ESCU" 1 "01b = Lock is activated by HTCU" 0 "00b = Lock is inactive" ;
VAL_ 2349789985 Inv_SDM_Data_Pg_Rx_61427 3 "11b = Don't care/Take no action" 2 "10b = Reserved" 1 "01b = Enable charging" 0 "00b = Disable charging" ;
VAL_ 2364535585 Control_Es_Relay 7 "111b = info not available (default)" 6 "110b = disconnect DC char" 5 "101b = connect für DC char" 4 "100b = prepair for DC char" 3 "11b = connect for AC char" 2 "10b = connect for driving" 1 "01b = emergency disconnect" 0 "00b = disconnect" ;
VAL_ 2566834931 Flash_Mil 0 "Off" 1 "On" 2 "Short MIL" ;
VAL_ 2566834931 Flash_Rsl 0 "Off" 1 "On" ;
VAL_ 2566834931 Flash_Awl 0 "Off" 1 "On" ;
VAL_ 2566834931 Flash_ProtLamp 0 "Off" 1 "On" ;
VAL_ 2566834931 ProtLamp 0 "Off" 1 "On" ;
VAL_ 2566834931 Awl 0 "Off" 1 "On" ;
VAL_ 2566834931 Rsl 0 "Off" 1 "On" ;
VAL_ 2566834931 Mil 0 "Off" 1 "On" 2 "Short MIL" ;
VAL_ 2566834931 Fmi01 0 "Data Above Normal, Most severe" 1 "Data Below Normal, Most severe" 2 "Data erratic, interm, incorrect" 3 "Voltage above normal, SC High" 4 "Voltage below normal, SC Low" 5 "Current below normal, OC" 6 "Current above normal, SC" 7 "Mech. system not responding" 8 "Abnormal Freq, Width, Period" 9 "Abnormal Update Rate" 10 "Abnormal Rate Of Change" 11 "Root Cause Not Known" 12 "Bad Intell. Device, Component" 13 "Out Of Calibration" 14 "Special Instructions" 15 "Data Above Normal, Least severe" 16 "Data Above Normal, Moder. severe" 17 "Data Below Normal, Least Severe" 18 "Data Below Normal, Moder. severe" 19 "Received Network Data In Error" 20 "Data Drifted High" 21 "Data Drifted Low" 31 "Condition Exists" ;
VAL_ 2566834931 Oc01 127 "Not Available" ;
VAL_ 2566834931 SpnCm01 0 "SPN v.4" 1 "SPN v.1,2,3" ;
VAL_ 2566834931 Fmi02 0 "Data Above Normal, Most severe" 1 "Data Below Normal, Most severe" 2 "Data erratic, interm, incorrect" 3 "Voltage above normal, SC High" 4 "Voltage below normal, SC Low" 5 "Current below normal, OC" 6 "Current above normal, SC" 7 "Mech. system not responding" 8 "Abnormal Freq, Width, Period" 9 "Abnormal Update Rate" 10 "Abnormal Rate Of Change" 11 "Root Cause Not Known" 12 "Bad Intell. Device, Component" 13 "Out Of Calibration" 14 "Special Instructions" 15 "Data Above Normal, Least severe" 16 "Data Above Normal, Moder. severe" 17 "Data Below Normal, Least Severe" 18 "Data Below Normal, Moder. severe" 19 "Received Network Data In Error" 20 "Data Drifted High" 21 "Data Drifted Low" 31 "Condition Exists" ;
VAL_ 2566834931 Oc02 127 "Not Available" ;
VAL_ 2566834931 SpnCm02 0 "SPN v.4" 1 "SPN v.1,2,3" ;
VAL_ 2566834931 Fmi03 0 "Data Above Normal, Most severe" 1 "Data Below Normal, Most severe" 2 "Data erratic, interm, incorrect" 3 "Voltage above normal, SC High" 4 "Voltage below normal, SC Low" 5 "Current below normal, OC" 6 "Current above normal, SC" 7 "Mech. system not responding" 8 "Abnormal Freq, Width, Period" 9 "Abnormal Update Rate" 10 "Abnormal Rate Of Change" 11 "Root Cause Not Known" 12 "Bad Intell. Device, Component" 13 "Out Of Calibration" 14 "Special Instructions" 15 "Data Above Normal, Least severe" 16 "Data Above Normal, Moder. severe" 17 "Data Below Normal, Least Severe" 18 "Data Below Normal, Moder. severe" 19 "Received Network Data In Error" 20 "Data Drifted High" 21 "Data Drifted Low" 31 "Condition Exists" ;
VAL_ 2566834931 Oc03 127 "Not Available" ;
VAL_ 2566834931 SpnCm03 0 "SPN v.4" 1 "SPN v.1,2,3" ;
VAL_ 2566834931 Fmi04 0 "Data Above Normal, Most severe" 1 "Data Below Normal, Most severe" 2 "Data erratic, interm, incorrect" 3 "Voltage above normal, SC High" 4 "Voltage below normal, SC Low" 5 "Current below normal, OC" 6 "Current above normal, SC" 7 "Mech. system not responding" 8 "Abnormal Freq, Width, Period" 9 "Abnormal Update Rate" 10 "Abnormal Rate Of Change" 11 "Root Cause Not Known" 12 "Bad Intell. Device, Component" 13 "Out Of Calibration" 14 "Special Instructions" 15 "Data Above Normal, Least severe" 16 "Data Above Normal, Moder. severe" 17 "Data Below Normal, Least Severe" 18 "Data Below Normal, Moder. severe" 19 "Received Network Data In Error" 20 "Data Drifted High" 21 "Data Drifted Low" 31 "Condition Exists" ;
VAL_ 2566834931 Oc04 127 "Not Available" ;
VAL_ 2566834931 SpnCm04 0 "SPN v.4" 1 "SPN v.1,2,3" ;
VAL_ 2566834931 Fmi05 0 "Data Above Normal, Most severe" 1 "Data Below Normal, Most severe" 2 "Data erratic, interm, incorrect" 3 "Voltage above normal, SC High" 4 "Voltage below normal, SC Low" 5 "Current below normal, OC" 6 "Current above normal, SC" 7 "Mech. system not responding" 8 "Abnormal Freq, Width, Period" 9 "Abnormal Update Rate" 10 "Abnormal Rate Of Change" 11 "Root Cause Not Known" 12 "Bad Intell. Device, Component" 13 "Out Of Calibration" 14 "Special Instructions" 15 "Data Above Normal, Least severe" 16 "Data Above Normal, Moder. severe" 17 "Data Below Normal, Least Severe" 18 "Data Below Normal, Moder. severe" 19 "Received Network Data In Error" 20 "Data Drifted High" 21 "Data Drifted Low" 31 "Condition Exists" ;
VAL_ 2566834931 Oc05 127 "Not Available" ;
VAL_ 2566834931 SpnCm05 0 "SPN v.4" 1 "SPN v.1,2,3" ;
VAL_ 2566834931 Fmi06 0 "Data Above Normal, Most severe" 1 "Data Below Normal, Most severe" 2 "Data erratic, interm, incorrect" 3 "Voltage above normal, SC High" 4 "Voltage below normal, SC Low" 5 "Current below normal, OC" 6 "Current above normal, SC" 7 "Mech. system not responding" 8 "Abnormal Freq, Width, Period" 9 "Abnormal Update Rate" 10 "Abnormal Rate Of Change" 11 "Root Cause Not Known" 12 "Bad Intell. Device, Component" 13 "Out Of Calibration" 14 "Special Instructions" 15 "Data Above Normal, Least severe" 16 "Data Above Normal, Moder. severe" 17 "Data Below Normal, Least Severe" 18 "Data Below Normal, Moder. severe" 19 "Received Network Data In Error" 20 "Data Drifted High" 21 "Data Drifted Low" 31 "Condition Exists" ;
VAL_ 2566834931 Oc06 127 "Not Available" ;
VAL_ 2566834931 SpnCm06 0 "SPN v.4" 1 "SPN v.1,2,3" ;
VAL_ 2566834931 Fmi07 0 "Data Above Normal, Most severe" 1 "Data Below Normal, Most severe" 2 "Data erratic, interm, incorrect" 3 "Voltage above normal, SC High" 4 "Voltage below normal, SC Low" 5 "Current below normal, OC" 6 "Current above normal, SC" 7 "Mech. system not responding" 8 "Abnormal Freq, Width, Period" 9 "Abnormal Update Rate" 10 "Abnormal Rate Of Change" 11 "Root Cause Not Known" 12 "Bad Intell. Device, Component" 13 "Out Of Calibration" 14 "Special Instructions" 15 "Data Above Normal, Least severe" 16 "Data Above Normal, Moder. severe" 17 "Data Below Normal, Least Severe" 18 "Data Below Normal, Moder. severe" 19 "Received Network Data In Error" 20 "Data Drifted High" 21 "Data Drifted Low" 31 "Condition Exists" ;
VAL_ 2566834931 Oc07 127 "Not Available" ;
VAL_ 2566834931 SpnCm07 0 "SPN v.4" 1 "SPN v.1,2,3" ;
VAL_ 2566834931 Fmi08 0 "Data Above Normal, Most severe" 1 "Data Below Normal, Most severe" 2 "Data erratic, interm, incorrect" 3 "Voltage above normal, SC High" 4 "Voltage below normal, SC Low" 5 "Current below normal, OC" 6 "Current above normal, SC" 7 "Mech. system not responding" 8 "Abnormal Freq, Width, Period" 9 "Abnormal Update Rate" 10 "Abnormal Rate Of Change" 11 "Root Cause Not Known" 12 "Bad Intell. Device, Component" 13 "Out Of Calibration" 14 "Special Instructions" 15 "Data Above Normal, Least severe" 16 "Data Above Normal, Moder. severe" 17 "Data Below Normal, Least Severe" 18 "Data Below Normal, Moder. severe" 19 "Received Network Data In Error" 20 "Data Drifted High" 21 "Data Drifted Low" 31 "Condition Exists" ;
VAL_ 2566834931 Oc08 127 "Not Available" ;
VAL_ 2566834931 SpnCm08 0 "SPN v.4" 1 "SPN v.1,2,3" ;
VAL_ 2566834931 Fmi09 0 "Data Above Normal, Most severe" 1 "Data Below Normal, Most severe" 2 "Data erratic, interm, incorrect" 3 "Voltage above normal, SC High" 4 "Voltage below normal, SC Low" 5 "Current below normal, OC" 6 "Current above normal, SC" 7 "Mech. system not responding" 8 "Abnormal Freq, Width, Period" 9 "Abnormal Update Rate" 10 "Abnormal Rate Of Change" 11 "Root Cause Not Known" 12 "Bad Intell. Device, Component" 13 "Out Of Calibration" 14 "Special Instructions" 15 "Data Above Normal, Least severe" 16 "Data Above Normal, Moder. severe" 17 "Data Below Normal, Least Severe" 18 "Data Below Normal, Moder. severe" 19 "Received Network Data In Error" 20 "Data Drifted High" 21 "Data Drifted Low" 31 "Condition Exists" ;
VAL_ 2566834931 Oc09 127 "Not Available" ;
VAL_ 2566834931 SpnCm09 0 "SPN v.4" 1 "SPN v.1,2,3" ;
VAL_ 2566834931 Fmi10 0 "Data Above Normal, Most severe" 1 "Data Below Normal, Most severe" 2 "Data erratic, interm, incorrect" 3 "Voltage above normal, SC High" 4 "Voltage below normal, SC Low" 5 "Current below normal, OC" 6 "Current above normal, SC" 7 "Mech. system not responding" 8 "Abnormal Freq, Width, Period" 9 "Abnormal Update Rate" 10 "Abnormal Rate Of Change" 11 "Root Cause Not Known" 12 "Bad Intell. Device, Component" 13 "Out Of Calibration" 14 "Special Instructions" 15 "Data Above Normal, Least severe" 16 "Data Above Normal, Moder. severe" 17 "Data Below Normal, Least Severe" 18 "Data Below Normal, Moder. severe" 19 "Received Network Data In Error" 20 "Data Drifted High" 21 "Data Drifted Low" 31 "Condition Exists" ;
VAL_ 2566834931 Oc10 127 "Not Available" ;
VAL_ 2566834931 SpnCm10 0 "SPN v.4" 1 "SPN v.1,2,3" ;
VAL_ 2416902131 Inv_SDM_E_Data_Pg_Tx_65473 3 "11b = Don't care/Take no action" 2 "10b = Reserved" 1 "01b = Enable charging" 0 "00b = Disable charging" ;
VAL_ 2416902131 Inv_SDM_Data_Pg_Tx_65473 3 "11b = Don't care/Take no action" 2 "10b = Reserved" 1 "01b = Enable charging" 0 "00b = Disable charging" ;
VAL_ 2416902131 Inv_SDM_PF_Value_Tx_65473 3 "11b = Don't care/Take no action" 2 "10b = Reserved" 1 "01b = Enable charging" 0 "00b = Disable charging" ;
VAL_ 2416902131 Inv_SDM_PS_Value_Tx_65473 3 "11b = Don't care/Take no action" 2 "10b = Reserved" 1 "01b = Enable charging" 0 "00b = Disable charging" ;
VAL_ 2416902131 Inv_SDM_SA_Tx_65473 3 "11b = Don't care/Take no action" 2 "10b = Reserved" 1 "01b = Enable charging" 0 "00b = Disable charging" ;
VAL_ 2416902131 SDM_Data_CRC_Tx_65473 3 "11b = Don't care/Take no action" 2 "10b = Reserved" 1 "01b = Enable charging" 0 "00b = Disable charging" ;
VAL_ 2416902131 Sequence_Number_Tx_65473 3 "11b = Don't care/Take no action" 2 "10b = Reserved" 1 "01b = Enable charging" 0 "00b = Disable charging" ;
VAL_ 2416902131 SHM_Reserved_Tx_65473 3 "11b = Don't care/Take no action" 2 "10b = Reserved" 1 "01b = Enable charging" 0 "00b = Disable charging" ;
VAL_ 2484010995 Inv_SDM_E_Data_Pg_Tx_65472 3 "11b = Don't care/Take no action" 2 "10b = Reserved" 1 "01b = Enable charging" 0 "00b = Disable charging" ;
VAL_ 2484010995 Inv_SDM_Data_Pg_Tx_65472 3 "11b = Don't care/Take no action" 2 "10b = Reserved" 1 "01b = Enable charging" 0 "00b = Disable charging" ;
VAL_ 2484010995 Inv_SDM_PF_Value_Tx_65472 3 "11b = Don't care/Take no action" 2 "10b = Reserved" 1 "01b = Enable charging" 0 "00b = Disable charging" ;
VAL_ 2484010995 Inv_SDM_PS_Value_Tx_65472 3 "11b = Don't care/Take no action" 2 "10b = Reserved" 1 "01b = Enable charging" 0 "00b = Disable charging" ;
VAL_ 2484010995 Inv_SDM_SA_Tx_65472 3 "11b = Don't care/Take no action" 2 "10b = Reserved" 1 "01b = Enable charging" 0 "00b = Disable charging" ;
VAL_ 2484010995 SDM_Data_CRC_Tx_65472 3 "11b = Don't care/Take no action" 2 "10b = Reserved" 1 "01b = Enable charging" 0 "00b = Disable charging" ;
VAL_ 2484010995 Sequence_Number_Tx_65472 3 "11b = Don't care/Take no action" 2 "10b = Reserved" 1 "01b = Enable charging" 0 "00b = Disable charging" ;
VAL_ 2484010995 SHM_Reserved_Tx_65472 3 "11b = Don't care/Take no action" 2 "10b = Reserved" 1 "01b = Enable charging" 0 "00b = Disable charging" ;
VAL_ 2349793267 Inv_SDM_E_Data_Pg_Tx_61584 3 "11b = Don't care/Take no action" 2 "10b = Reserved" 1 "01b = Enable charging" 0 "00b = Disable charging" ;
VAL_ 2349793267 Inv_SDM_Data_Pg_Tx_61584 3 "11b = Don't care/Take no action" 2 "10b = Reserved" 1 "01b = Enable charging" 0 "00b = Disable charging" ;
VAL_ 2349793267 Inv_SDM_PF_Value_Tx_61584 3 "11b = Don't care/Take no action" 2 "10b = Reserved" 1 "01b = Enable charging" 0 "00b = Disable charging" ;
VAL_ 2349793267 Inv_SDM_PS_Value_Tx_61584 3 "11b = Don't care/Take no action" 2 "10b = Reserved" 1 "01b = Enable charging" 0 "00b = Disable charging" ;
VAL_ 2349793267 Inv_SDM_SA_Tx_61584 3 "11b = Don't care/Take no action" 2 "10b = Reserved" 1 "01b = Enable charging" 0 "00b = Disable charging" ;
VAL_ 2349793267 SDM_Data_CRC_Tx_61584 3 "11b = Don't care/Take no action" 2 "10b = Reserved" 1 "01b = Enable charging" 0 "00b = Disable charging" ;
VAL_ 2349793267 Sequence_Number_Tx_61584 3 "11b = Don't care/Take no action" 2 "10b = Reserved" 1 "01b = Enable charging" 0 "00b = Disable charging" ;
VAL_ 2349793267 SHM_Reserved_Tx_61584 3 "11b = Don't care/Take no action" 2 "10b = Reserved" 1 "01b = Enable charging" 0 "00b = Disable charging" ;
VAL_ 2216424225 HS_HiUBusCnctCmd_Rx1 3 "11b = Don't care/Take no action" 2 "10b = Emergency contactor closure request" 1 "01b = Close Contactor; Connect HVES to high-voltage bus" 0 "00b = Open Contactor; Disconnect HVES from high-voltage bus" ;
VAL_ 2216424225 HS_PwrDwnCmd_Rx1 3 "11b = Don't care/Take no action" 2 "10b = Execute emergency power-down" 1 "01b = Execute normal power-down" 0 "00b = Power-down not requested" ;
VAL_ 2216424225 HS_HiUBusAcvIslnTestCmd_Rx1 3 "11b = Don't care/Take no action" 2 "10b = Inhibit Active Isolation Test" 1 "01b = Active Isolation Test request" 0 "00b = Active Isolation Test not requested" ;
VAL_ 2216424225 HS_HiUBusPasIslnTestCmd_Rx1 3 "11b = Don't care/Take no action" 2 "10b = Inhibit Passive Isolation Test" 1 "01b = Passive Isolation Test request" 0 "00b = Passive Isolation Test not requested" ;
VAL_ 2216424225 HS_CellBalnCmd_Rx1 3 "11b = Don't care/Take no action" 2 "10b = Reserved" 1 "01b = Cell Balancing requested" 0 "00b = Cell Balancing not requested" ;
VAL_ 2216424225 HS_EnaIntChrgrCmd_Rx1 3 "11b = Don't care/Take no action" 2 "10b = Reserved" 1 "01b = Enable charging" 0 "00b = Disable charging" ;
VAL_ 2216424225 HS_OperConsent_Rx1 3 "11b = Don't care/Take no action" 2 "10b = Error" 1 "01b = Consent given; system component consents to HVES instance operation" 0 "00b = Consent revoked; system component does not consent to HVES instance operation" ;
VAL_ 2216424225 HS_HiUBusHiSideRestrCnctReq_Rx1 3 "11b = Don't care/take no action" 2 "10b = Reserved" 1 "01b = Connection Requested" 0 "00b = Connection not Requested" ;
VAL_ 2216424225 HS_HiUBusLoSideRestrCnctReq_Rx1 3 "11b = Don't care/take no action" 2 "10b = Reserved" 1 "01b = Connection Requested" 0 "00b = Connection not Requested" ;
VAL_ 2215575539 SDM_Data_CRC_Tx_61590 3 "11b = Don't care/Take no action" 2 "10b = Reserved" 1 "01b = Enable charging" 0 "00b = Disable charging" ;
VAL_ 2215575539 Inv_SDM_SA_Tx_61590 3 "11b = Don't care/Take no action" 2 "10b = Reserved" 1 "01b = Enable charging" 0 "00b = Disable charging" ;
VAL_ 2215575539 Inv_SDM_PS_Value_Tx_61590 3 "11b = Don't care/Take no action" 2 "10b = Reserved" 1 "01b = Enable charging" 0 "00b = Disable charging" ;
VAL_ 2215575539 Inv_SDM_PF_Value_Tx_61590 3 "11b = Don't care/Take no action" 2 "10b = Reserved" 1 "01b = Enable charging" 0 "00b = Disable charging" ;
VAL_ 2215575539 Sequence_Number_Tx_61590 3 "11b = Don't care/Take no action" 2 "10b = Reserved" 1 "01b = Enable charging" 0 "00b = Disable charging" ;
VAL_ 2215575539 SHM_Reserved_Tx_61590 3 "11b = Don't care/Take no action" 2 "10b = Reserved" 1 "01b = Enable charging" 0 "00b = Disable charging" ;
VAL_ 2215575539 Inv_SDM_E_Data_Pg_Tx_61590 3 "11b = Don't care/Take no action" 2 "10b = Reserved" 1 "01b = Enable charging" 0 "00b = Disable charging" ;
VAL_ 2215575539 Inv_SDM_Data_Pg_Tx_61590 3 "11b = Don't care/Take no action" 2 "10b = Reserved" 1 "01b = Enable charging" 0 "00b = Disable charging" ;
VAL_ 2282684403 SDM_Data_CRC_Tx_61708 3 "11b = Don't care/Take no action" 2 "10b = Reserved" 1 "01b = Enable charging" 0 "00b = Disable charging" ;
VAL_ 2282684403 Inv_SDM_SA_Tx_61708 3 "11b = Don't care/Take no action" 2 "10b = Reserved" 1 "01b = Enable charging" 0 "00b = Disable charging" ;
VAL_ 2282684403 Inv_SDM_PS_Value_Tx_61708 3 "11b = Don't care/Take no action" 2 "10b = Reserved" 1 "01b = Enable charging" 0 "00b = Disable charging" ;
VAL_ 2282684403 Inv_SDM_PF_Value_Tx_61708 3 "11b = Don't care/Take no action" 2 "10b = Reserved" 1 "01b = Enable charging" 0 "00b = Disable charging" ;
VAL_ 2282684403 Sequence_Number_Tx_61708 3 "11b = Don't care/Take no action" 2 "10b = Reserved" 1 "01b = Enable charging" 0 "00b = Disable charging" ;
VAL_ 2282684403 SHM_Reserved_Tx_61708 3 "11b = Don't care/Take no action" 2 "10b = Reserved" 1 "01b = Enable charging" 0 "00b = Disable charging" ;
VAL_ 2282684403 Inv_SDM_E_Data_Pg_Tx_61708 3 "11b = Don't care/Take no action" 2 "10b = Reserved" 1 "01b = Enable charging" 0 "00b = Disable charging" ;
VAL_ 2282684403 Inv_SDM_Data_Pg_Tx_61708 3 "11b = Don't care/Take no action" 2 "10b = Reserved" 1 "01b = Enable charging" 0 "00b = Disable charging" ;
VAL_ 2551119649 SDM_Data_CRC_Rx_65269 3 "11b = Don't care/Take no action" 2 "10b = Reserved" 1 "01b = Enable charging" 0 "00b = Disable charging" ;
VAL_ 2551119649 Inv_SDM_PF_Value_Rx_65269 3 "11b = Don't care/Take no action" 2 "10b = Reserved" 1 "01b = Enable charging" 0 "00b = Disable charging" ;
VAL_ 2551119649 Inv_SDM_PS_Value_Rx_65269 3 "11b = Don't care/Take no action" 2 "10b = Reserved" 1 "01b = Enable charging" 0 "00b = Disable charging" ;
VAL_ 2551119649 Inv_SDM_SA_Rx_65269 3 "11b = Don't care/Take no action" 2 "10b = Reserved" 1 "01b = Enable charging" 0 "00b = Disable charging" ;
VAL_ 2551119649 Sequence_Number_Rx_65269 3 "11b = Don't care/Take no action" 2 "10b = Reserved" 1 "01b = Enable charging" 0 "00b = Disable charging" ;
VAL_ 2551119649 SHM_Reserved_Rx_65269 3 "11b = Don't care/Take no action" 2 "10b = Reserved" 1 "01b = Enable charging" 0 "00b = Disable charging" ;
VAL_ 2551119649 Inv_SDM_E_Data_Pg_Rx_65269 3 "11b = Don't care/Take no action" 2 "10b = Reserved" 1 "01b = Enable charging" 0 "00b = Disable charging" ;
VAL_ 2551119649 Inv_SDM_Data_Pg_Rx_65269 3 "11b = Don't care/Take no action" 2 "10b = Reserved" 1 "01b = Enable charging" 0 "00b = Disable charging" ;
VAL_ 2484010785 SDM_Data_CRC_Rx_65265 3 "11b = Don't care/Take no action" 2 "10b = Reserved" 1 "01b = Enable charging" 0 "00b = Disable charging" ;
VAL_ 2484010785 Inv_SDM_PF_Value_Rx_65265 3 "11b = Don't care/Take no action" 2 "10b = Reserved" 1 "01b = Enable charging" 0 "00b = Disable charging" ;
VAL_ 2484010785 Inv_SDM_PS_Value_Rx_65265 3 "11b = Don't care/Take no action" 2 "10b = Reserved" 1 "01b = Enable charging" 0 "00b = Disable charging" ;
VAL_ 2484010785 Inv_SDM_SA_Rx_65265 3 "11b = Don't care/Take no action" 2 "10b = Reserved" 1 "01b = Enable charging" 0 "00b = Disable charging" ;
VAL_ 2484010785 Sequence_Number_Rx_65265 3 "11b = Don't care/Take no action" 2 "10b = Reserved" 1 "01b = Enable charging" 0 "00b = Disable charging" ;
VAL_ 2484010785 SHM_Reserved_Rx_65265 3 "11b = Don't care/Take no action" 2 "10b = Reserved" 1 "01b = Enable charging" 0 "00b = Disable charging" ;
VAL_ 2484010785 Inv_SDM_E_Data_Pg_Rx_65265 3 "11b = Don't care/Take no action" 2 "10b = Reserved" 1 "01b = Enable charging" 0 "00b = Disable charging" ;
VAL_ 2484010785 Inv_SDM_Data_Pg_Rx_65265 3 "11b = Don't care/Take no action" 2 "10b = Reserved" 1 "01b = Enable charging" 0 "00b = Disable charging" ;
VAL_ 2416901921 SDM_Data_CRC_Rx_61483 3 "11b = Don't care/Take no action" 2 "10b = Reserved" 1 "01b = Enable charging" 0 "00b = Disable charging" ;
VAL_ 2416901921 Inv_SDM_SA_Rx_61483 3 "11b = Don't care/Take no action" 2 "10b = Reserved" 1 "01b = Enable charging" 0 "00b = Disable charging" ;
VAL_ 2416901921 Inv_SDM_PS_Value_Rx_61483 3 "11b = Don't care/Take no action" 2 "10b = Reserved" 1 "01b = Enable charging" 0 "00b = Disable charging" ;
VAL_ 2416901921 Inv_SDM_PF_Value_Rx_61483 3 "11b = Don't care/Take no action" 2 "10b = Reserved" 1 "01b = Enable charging" 0 "00b = Disable charging" ;
VAL_ 2416901921 Sequence_Number_Rx_61483 3 "11b = Don't care/Take no action" 2 "10b = Reserved" 1 "01b = Enable charging" 0 "00b = Disable charging" ;
VAL_ 2416901921 SHM_Reserved_Rx_61483 3 "11b = Don't care/Take no action" 2 "10b = Reserved" 1 "01b = Enable charging" 0 "00b = Disable charging" ;
VAL_ 2416901921 Inv_SDM_E_Data_Pg_Rx_61483 3 "11b = Don't care/Take no action" 2 "10b = Reserved" 1 "01b = Enable charging" 0 "00b = Disable charging" ;
VAL_ 2416901921 Inv_SDM_Data_Pg_Rx_61483 3 "11b = Don't care/Take no action" 2 "10b = Reserved" 1 "01b = Enable charging" 0 "00b = Disable charging" ;
VAL_ 2282627571 Inv_SDM_Ext_Data_Pg_Tx_6912 3 "11b = Don't care/Take no action" 2 "10b = Reserved" 1 "01b = Enable charging" 0 "00b = Disable charging" ;
VAL_ 2282627571 Inv_SDM_Data_Pg_Tx_6912 3 "11b = Don't care/Take no action" 2 "10b = Reserved" 1 "01b = Enable charging" 0 "00b = Disable charging" ;
VAL_ 2282627571 Inv_SDM_PF_Value_Tx_6912 3 "11b = Don't care/Take no action" 2 "10b = Reserved" 1 "01b = Enable charging" 0 "00b = Disable charging" ;
VAL_ 2282627571 Inv_SDM_PS_Value_Tx_6912 3 "11b = Don't care/Take no action" 2 "10b = Reserved" 1 "01b = Enable charging" 0 "00b = Disable charging" ;
VAL_ 2282627571 Inv_SDM_SA_Tx_6912 3 "11b = Don't care/Take no action" 2 "10b = Reserved" 1 "01b = Enable charging" 0 "00b = Disable charging" ;
VAL_ 2282627571 SDM_Data_CRC_Tx_6912 3 "11b = Don't care/Take no action" 2 "10b = Reserved" 1 "01b = Enable charging" 0 "00b = Disable charging" ;
VAL_ 2282627571 Sequence_Number_Tx_6912 3 "11b = Don't care/Take no action" 2 "10b = Reserved" 1 "01b = Enable charging" 0 "00b = Disable charging" ;
VAL_ 2282627571 SHM_Reserved_Tx_6912 3 "11b = Don't care/Take no action" 2 "10b = Reserved" 1 "01b = Enable charging" 0 "00b = Disable charging" ;
VAL_ 2499789043 ThermRunAwPermsnToCls 15 "1111b = Info not available (default)" 11 "1011b = Granted but error" 10 "1010b = Granted" 2 "10b = Denied permanently" 1 "01b = Denied until restart" 0 "00b = Denied due to initialization" ;
VAL_ 2499789043 LockMemPermsnToCls 15 "1111b = Info not available (default)" 11 "1011b = Granted but error" 10 "1010b = Granted" 2 "10b = Denied permanently" 1 "01b = Denied until restart" 0 "00b = Denied due to initialization" ;
VAL_ 2499789043 IslnPermsnToCls 15 "1111b = Info not available (default)" 11 "1011b = Granted but error" 10 "1010b = Granted" 2 "10b = Denied permanently" 1 "01b = Denied until restart" 0 "00b = Denied due to initialization" ;
VAL_ 2499789043 IPermsnToCls 15 "1111b = Info not available (default)" 11 "1011b = Granted but error" 10 "1010b = Granted" 2 "10b = Denied permanently" 1 "01b = Denied until restart" 0 "00b = Denied due to initialization" ;
VAL_ 2499789043 DcChCtctrPermsnToCls 15 "1111b = Info not available (default)" 11 "1011b = Granted but error" 10 "1010b = Granted" 2 "10b = Denied permanently" 1 "01b = Denied until restart" 0 "00b = Denied due to initialization" ;
VAL_ 2499789043 CtctrStuckPermsnToCls 15 "1111b = Info not available (default)" 11 "1011b = Granted but error" 10 "1010b = Granted" 2 "10b = Denied permanently" 1 "01b = Denied until restart" 0 "00b = Denied due to initialization" ;
VAL_ 2499789043 CrashPermsnToCls 15 "1111b = Info not available (default)" 11 "1011b = Granted but error" 10 "1010b = Granted" 2 "10b = Denied permanently" 1 "01b = Denied until restart" 0 "00b = Denied due to initialization" ;
VAL_ 2499789043 CptTPermsnToCls 15 "1111b = Info not available (default)" 11 "1011b = Granted but error" 10 "1010b = Granted" 2 "10b = Denied permanently" 1 "01b = Denied until restart" 0 "00b = Denied due to initialization" ;
VAL_ 2499789043 CellUPermsnToCls 15 "1111b = Info not available (default)" 11 "1011b = Granted but error" 10 "1010b = Granted" 2 "10b = Denied permanently" 1 "01b = Denied until restart" 0 "00b = Denied due to initialization" ;
VAL_ 2499789043 CellTPermsnToCls 15 "1111b = Info not available (default)" 11 "1011b = Granted but error" 10 "1010b = Granted" 2 "10b = Denied permanently" 1 "01b = Denied until restart" 0 "00b = Denied due to initialization" ;
VAL_ 2499789299 HvilPermsnToCls 15 "1111b = Info not available (default)" 11 "1011b = Granted but error" 10 "1010b = Granted" 2 "10b = Denied permanently" 1 "01b = Denied until restart" 0 "00b = Denied due to initialization" ;
VAL_ 2499789299 ThermEveStsCellT 3 "11b = info not available (default)" 2 "10b = crit. temp. warn. limit exceeded" 1 "01b = temp. warn. limit exceeded" 0 "00b = temperature ok" ;
VAL_ 2499789299 ErrLvl 7 "111b = Open contactors immediately and lock" 6 "110b = Open contactors immediately" 5 "101b = Open contactors normal" 4 "100b = Open contactors with time limit" 3 "11b = Open contactors with speed limit" 2 "10b = Limp Home with limited power" 1 "01b = Internal information" 0 "00b = System is ok" ;
VAL_ 2215572257 SHM_Reserved_Rx1_6912 3 "11b = Don't care/Take no action" 2 "10b = Reserved" 1 "01b = Enable charging" 0 "00b = Disable charging" ;
VAL_ 2215572257 SDM_Data_CRC_Rx1_6912 3 "11b = Don't care/Take no action" 2 "10b = Reserved" 1 "01b = Enable charging" 0 "00b = Disable charging" ;
VAL_ 2215572257 Sequence_Number_Rx1_6912 3 "11b = Don't care/Take no action" 2 "10b = Reserved" 1 "01b = Enable charging" 0 "00b = Disable charging" ;
VAL_ 2215572257 Inv_SDM_SA_Rx1_6912 3 "11b = Don't care/Take no action" 2 "10b = Reserved" 1 "01b = Enable charging" 0 "00b = Disable charging" ;
VAL_ 2215572257 Inv_SDM_PS_Value_Rx1_6912 3 "11b = Don't care/Take no action" 2 "10b = Reserved" 1 "01b = Enable charging" 0 "00b = Disable charging" ;
VAL_ 2215572257 Inv_SDM_PF_Value_Rx1_6912 3 "11b = Don't care/Take no action" 2 "10b = Reserved" 1 "01b = Enable charging" 0 "00b = Disable charging" ;
VAL_ 2215572257 Inv_SDM_E_Data_Pg_Rx1_6912 3 "11b = Don't care/Take no action" 2 "10b = Reserved" 1 "01b = Enable charging" 0 "00b = Disable charging" ;
VAL_ 2215572257 Inv_SDM_Data_Pg_Rx1_6912 3 "11b = Don't care/Take no action" 2 "10b = Reserved" 1 "01b = Enable charging" 0 "00b = Disable charging" ;
VAL_ 2283479539 HS_HiUBusCnctCmd_Tx 3 "11b = Don't care/Take no action" 2 "10b = Emergency contactor closure request" 1 "01b = Close Contactor; Connect HVES to high-voltage bus" 0 "00b = Open Contactor; Disconnect HVES from high-voltage bus" ;
VAL_ 2283479539 HS_PwrDwnCmd_Tx 3 "11b = Don't care/Take no action" 2 "10b = Execute emergency power-down" 1 "01b = Execute normal power-down" 0 "00b = Power-down not requested" ;
VAL_ 2283479539 HS_HiUBusAcvIslnTestCmd_Tx 3 "11b = Don't care/Take no action" 2 "10b = Inhibit Active Isolation Test" 1 "01b = Active Isolation Test request" 0 "00b = Active Isolation Test not requested" ;
VAL_ 2283479539 HS_HiUBusPasIslnTestCmd_Tx 3 "11b = Don't care/Take no action" 2 "10b = Inhibit Passive Isolation Test" 1 "01b = Passive Isolation Test request" 0 "00b = Passive Isolation Test not requested" ;
VAL_ 2283479539 HS_CellBalnCmd_Tx 3 "11b = Don't care/Take no action" 2 "10b = Reserved" 1 "01b = Cell Balancing requested" 0 "00b = Cell Balancing not requested" ;
VAL_ 2283479539 HS_EnaIntChrgrCmd_Tx 3 "11b = Don't care/Take no action" 2 "10b = Reserved" 1 "01b = Enable charging" 0 "00b = Disable charging" ;
VAL_ 2283479539 HS_OperConsent_Tx 3 "11b = Don't care/Take no action" 2 "10b = Error" 1 "01b = Consent given; system component consents to HVES instance operation" 0 "00b = Consent revoked; system component does not consent to HVES instance operation" ;
VAL_ 2283479539 HS_HiUBusHiSideRestrCnctReq_Tx 3 "11b = Don't care/take no action" 2 "10b = Reserved" 1 "01b = Connection Requested" 0 "00b = Connection not Requested" ;
VAL_ 2283479539 HS_HiUBusLoSideRestrCnctReq_Tx 3 "11b = Don't care/take no action" 2 "10b = Reserved" 1 "01b = Connection Requested" 0 "00b = Connection not Requested" ;
VAL_ 2565876513 Crash_Typ 6 "It is possible to combine different Crash Types. (e.g. frontal and side crash (left) = 00101b)" 5 "10000b = rollover" 4 "01000b = side crash (right)" 3 "00100b = side crash (left)" 2 "00010b = rear crash" 1 "00001b = frontal crash" 0 "00000b = no crash" ;
VAL_ 2565876513 Crash_Cks 1 "Checksum = ((Checksum >> 4) + Checksum) & 0Fh" 0 "Checksum = (Byte1 + Byte2 + Byte3 + Byte4 + Byte5 + Byte6 + Byte7 + (message counter & 0Fh) + message ID low byte + message ID mid low byte + message ID mid high byte + message ID high byte)" ;
VAL_ 2498795251 HS_HiUBusPosCtctrSt 3 "11b = Not Available" 2 "10b = Error" 1 "01b = Contactor Closed" 0 "00b = Contactor Open" ;
VAL_ 2498795251 HS_HiUBusNegCtctrSt 3 "11b = Not Available" 2 "10b = Error" 1 "01b = Contactor Closed" 0 "00b = Contactor Open" ;
VAL_ 2498795251 HS_HiUBusDcnctForewarning 15 "1111b = Not Available" 14 "1110b = Error" 13 "1101b = Disconnect imminent - no reason given" 12 "1100b = Reserved" 11 "1011b = Reserved" 10 "1010b = Reserved" 9 "1001b = Reserved" 8 "1000b = Reserved" 7 "0111b = Disconnect imminent due to battery pack current approaching maximum acceptable level" 6 "0110b = Disconnect imminent due to cell voltage approaching maximum acceptable level" 5 "0101b = Disconnect imminent due to cell voltage approaching minimum acceptable level" 4 "0100b = Disconnect imminent due to module voltage approaching maximum acceptable level" 3 "0011b = Disconnect imminent due to module voltage approaching minimum acceptable level" 2 "0010b = Disconnect imminent due to battery pack voltage approaching maximum acceptable level" 1 "0001b = Disconnect imminent due to battery pack voltage approaching minimum acceptable level" 0 "0000b = Disconnect not pending" ;
VAL_ 2498795251 HS_HiUBusPreChRlySt 3 "11b = Not Available" 2 "10b = Error" 1 "01b = Relay Closed" 0 "00b = Relay Open" ;
VAL_ 2498795251 HS_CentrofPackCtctrSt 3 "11b = Not Available" 2 "10b = Error" 1 "01b = Contactor Closed" 0 "00b = Contactor Open" ;
VAL_ 2498795251 HS_HiUBusAcvIslnTestSts 15 "1111b = Not available" 14 "1110b = Error" 13 "1101b = Reserved" 12 "1100b = Reserved" 11 "1011b = Reserved" 10 "1010b = Reserved" 9 "1001b = Reserved" 8 "1000b = Reserved" 7 "0111b = Reserved" 6 "0110b = Test is inhibited" 5 "0101b = Test complete; isolation fault" 4 "0100b = Test complete; isolation marginal" 3 "0011b = Test complete; isolation acceptable" 2 "0010b = Test in process" 1 "0001b = Test requested but not yet in process" 0 "0000b = No test requested / No test in process" ;
VAL_ 2498795251 HS_HiUBusPasIslnTestSts 15 "1111b = Not available" 14 "1110b = Error" 13 "1101b = Reserved" 12 "1100b = Reserved" 11 "1011b = Reserved" 10 "1010b = Reserved" 9 "1001b = Reserved" 8 "1000b = Reserved" 7 "0111b = Reserved" 6 "0110b = Test is inhibited" 5 "0101b = Test complete; isolation fault" 4 "0100b = Test complete; isolation marginal" 3 "0011b = Test complete; isolation acceptable" 2 "0010b = Test in process" 1 "0001b = Test requested but not yet in process" 0 "0000b = No test requested / No test in process" ;
VAL_ 2498795251 HS_HVILSts 3 "11b = Not Available" 2 "10b = Error" 1 "01b = HVIL Open" 0 "00b = HVIL Closed" ;
VAL_ 2498795251 HS_JSwtSts 3 "11b = Not Available" 2 "10b = Error" 1 "01b = Impact sensed" 0 "00b = No impact sensed" ;
VAL_ 2498795251 HS_StofChSts 15 "1111b = Not  Available" 14 "1110b = Error" 13 "1101b = Reserved" 12 "1100b = Reserved" 11 "1011b = Reserved" 10 "1010b = Reserved" 9 "1001b = Reserved" 8 "1000b = Reserved" 7 "0111b = Reserved" 6 "0110b = SOC is above its recommended upper limit" 5 "0101b = SOC is at its recommended upper limit" 4 "0100b = SOC is approaching its recommended upper limit" 3 "0011b = SOC is below its recommended lower limit" 2 "0010b = SOC is at its recommended lower limit" 1 "0001b = SOC is approaching its recommended lower limit" 0 "0000b = SOC level is acceptable." ;
VAL_ 2498795251 HS_CellBalSts 3 "11b = Not Available" 2 "10b = Error" 1 "01b = Cells are unbalanced" 0 "00b = Cells are balanced" ;
VAL_ 2498795251 HS_CellBalnAcv 3 "11b = Not Available" 2 "10b = Error" 1 "01b = Cell balancing is active" 0 "00b = Cell balancing is not active" ;
VAL_ 2498795251 HS_IntChrgrSts 3 "11b = Not Available" 2 "10b = Error" 1 "01b = Charging on" 0 "00b = Charging off" ;
VAL_ 2498795251 HS_HiUBusCnctnSts 15 "1111b = Not Available" 14 "1110b = Error" 13 "1101b = Reserved" 12 "1100b = Reserved" 11 "1011b = Reserved" 10 "1010b = Reserved" 9 "1001b = Reserved" 8 "1000b = Reserved" 7 "0111b = Reserved" 6 "0110b = Reserved" 5 "0101b = Reserved" 4 "0100b = Disconnected; Precharge Failed.  Indicates that the pre-charge function status cannot be determined or did not complete (e.g. Relay failure, insufficient HVES voltage, etc.)." 3 "0011b = Disconnection in Process.   May be rapidly transitioned through depending on HVES design, but indicates that HVES1 is in the process of disconnecting itself from the high voltage bus." 2 "0010b = Connection in Process.  May be rapidly transitioned through depending on HVES design, but indicates that the precharge relay is closed and/or one or more contactors may also be closed or in the process of being closed." 1 "0001b = Connected.  All contactors are closed and the precharge relay is open.  Typically results from the SPN 8123 (HVESS High-Voltage Bus Connect Command) ." 0 "0000b = Disconnected.  One or more contactors are open.  State may result from the SPN 8123 (HVESS High-Voltage Bus Connect Command) or due to a limit being exceeded." ;
VAL_ 2498795251 HS_OperationalSts 15 "1111b = Not Available" 14 "1110b = Error" 13 "1101b = Reserved" 12 "1100b = Reserved" 11 "1011b = Reserved" 10 "1010b = Reserved" 9 "1001b = Reserved" 8 "1000b = Reserved" 7 "0111b = Reserved" 6 "0110b = Disabled by internal decision of HVES controller (e.g. malfunction, protection)" 5 "0101b = Disabled by external command.  The HVES is in a non-operational state due to a Power Down Command, or the result of Operation Consent being revoked." 4 "0100b = Emergency Power-Down In Process.  This state is a response to Power Down Command state 10b." 3 "0011b = Normal Power-Down in Process.  This state is a response to Power Down Command state 01b." 2 "0010b = Operational." 1 "0001b = Initialization Complete, awaiting Operation Consent.  HVES controller is ready from its perspective, but requires one or more positive Operation Consent indications before becoming fully operational.  Some applications may not support this state." 0 "0000b = Initialization in process.  The HVES controller is powering up.  This process may include both internal HVES controller checks, as well as system checks being run by the HVES controller." ;
